VERSION ""

NS_ :

BS_:

BU_: HVESP01 HVESS

BO_ 2499750250 HVESP01_EstOcv_6: 8 HVESP01
 SG_ HVESP01_estOcv_01_6 m0 : 8|14@1+ (0.001,0) [0|16.383] "Ah"  HVESP01
 SG_ HVESP01_estOcv_02_6 m0 : 22|14@1+ (0.001,0) [0|16.383] "Ah"  HVESP01
 SG_ HVESP01_estOcv_03_6 m0 : 36|14@1+ (0.001,0) [0|16.383] "Ah"  HVESP01
 SG_ HVESP01_estOcv_04_6 m0 : 50|14@1+ (0.001,0) [0|16.383] "Ah"  HVESP01
 SG_ HVESP01_estOcv_05_6 m1 : 8|14@1+ (0.001,0) [0|16.383] "Ah"  HVESP01
 SG_ HVESP01_estOcv_06_6 m1 : 22|14@1+ (0.001,0) [0|16.383] "Ah"  HVESP01
 SG_ HVESP01_estOcv_07_6 m1 : 36|14@1+ (0.001,0) [0|16.383] "Ah"  HVESP01
 SG_ HVESP01_estOcv_08_6 m1 : 50|14@1+ (0.001,0) [0|16.383] "Ah"  HVESP01
 SG_ HVESP01_estOcv_09_6 m2 : 8|14@1+ (0.001,0) [0|16.383] "Ah"  HVESP01
 SG_ HVESP01_estOcv_10_6 m2 : 22|14@1+ (0.001,0) [0|16.383] "Ah"  HVESP01
 SG_ HVESP01_estOcv_11_6 m2 : 36|14@1+ (0.001,0) [0|16.383] "Ah"  HVESP01
 SG_ HVESP01_estOcv_12_6 m2 : 50|14@1+ (0.001,0) [0|16.383] "Ah"  HVESP01
 SG_ HVESP01_estOcv_13_6 m3 : 8|14@1+ (0.001,0) [0|16.383] "Ah"  HVESP01
 SG_ HVESP01_estOcv_14_6 m3 : 22|14@1+ (0.001,0) [0|16.383] "Ah"  HVESP01
 SG_ HVESP01_estOcv_15_6 m3 : 36|14@1+ (0.001,0) [0|16.383] "Ah"  HVESP01
 SG_ HVESP01_estOcv_16_6 m3 : 50|14@1+ (0.001,0) [0|16.383] "Ah"  HVESP01
 SG_ HVESP01_estOcv_17_6 m4 : 8|14@1+ (0.001,0) [0|16.383] "Ah"  HVESP01
 SG_ HVESP01_estOcv_18_6 m4 : 22|14@1+ (0.001,0) [0|16.383] "Ah"  HVESP01
 SG_ HVESP01_estOcv_19_6 m4 : 36|14@1+ (0.001,0) [0|16.383] "Ah"  HVESP01
 SG_ HVESP01_estOcv_20_6 m4 : 50|14@1+ (0.001,0) [0|16.383] "Ah"  HVESP01
 SG_ HVESP01_estOcv_21_6 m5 : 8|14@1+ (0.001,0) [0|16.383] "Ah"  HVESP01
 SG_ HVESP01_estOcv_22_6 m5 : 22|14@1+ (0.001,0) [0|16.383] "Ah"  HVESP01
 SG_ HVESP01_estOcv_23_6 m5 : 36|14@1+ (0.001,0) [0|16.383] "Ah"  HVESP01
 SG_ HVESP01_estOcv_24_6 m5 : 50|14@1+ (0.001,0) [0|16.383] "Ah"  HVESP01
 SG_ HVESP01_estOcv_25_6 m6 : 8|14@1+ (0.001,0) [0|16.383] "Ah"  HVESP01
 SG_ HVESP01_estOcv_26_6 m6 : 22|14@1+ (0.001,0) [0|16.383] "Ah"  HVESP01
 SG_ HVESP01_estOcv_27_6 m6 : 36|14@1+ (0.001,0) [0|16.383] "Ah"  HVESP01
 SG_ HVESP01_estOcv_28_6 m6 : 50|14@1+ (0.001,0) [0|16.383] "Ah"  HVESP01
 SG_ HVESP01_estOcv_29_6 m7 : 8|14@1+ (0.001,0) [0|16.383] "Ah"  HVESP01
 SG_ HVESP01_estOcv_30_6 m7 : 22|14@1+ (0.001,0) [0|16.383] "Ah"  HVESP01
 SG_ HVESP01_estOcv_31_6 m7 : 36|14@1+ (0.001,0) [0|16.383] "Ah"  HVESP01
 SG_ HVESP01_estOcv_32_6 m7 : 50|14@1+ (0.001,0) [0|16.383] "Ah"  HVESP01
 SG_ HVESP01_estOcv_33_6 m8 : 8|14@1+ (0.001,0) [0|16.383] "Ah"  HVESP01
 SG_ HVESP01_estOcv_34_6 m8 : 22|14@1+ (0.001,0) [0|16.383] "Ah"  HVESP01
 SG_ HVESP01_estOcv_35_6 m8 : 36|14@1+ (0.001,0) [0|16.383] "Ah"  HVESP01
 SG_ HVESP01_estOcv_36_6 m8 : 50|14@1+ (0.001,0) [0|16.383] "Ah"  HVESP01
 SG_ HVESP01_estOcv_37_6 m9 : 8|14@1+ (0.001,0) [0|16.383] "Ah"  HVESP01
 SG_ HVESP01_estOcv_38_6 m9 : 22|14@1+ (0.001,0) [0|16.383] "Ah"  HVESP01
 SG_ HVESP01_estOcv_39_6 m9 : 36|14@1+ (0.001,0) [0|16.383] "Ah"  HVESP01
 SG_ HVESP01_estOcv_40_6 m9 : 50|14@1+ (0.001,0) [0|16.383] "Ah"  HVESP01
 SG_ HVESP01_estOcv_41_6 m10 : 8|14@1+ (0.001,0) [0|16.383] "Ah"  HVESP01
 SG_ HVESP01_estOcv_42_6 m10 : 22|14@1+ (0.001,0) [0|16.383] "Ah"  HVESP01
 SG_ HVESP01_estOcv_43_6 m10 : 36|14@1+ (0.001,0) [0|16.383] "Ah"  HVESP01
 SG_ HVESP01_estOcv_44_6 m10 : 50|14@1+ (0.001,0) [0|16.383] "Ah"  HVESP01
 SG_ HVESP01_estOcv_45_6 m11 : 8|14@1+ (0.001,0) [0|16.383] "Ah"  HVESP01
 SG_ HVESP01_estOcv_46_6 m11 : 22|14@1+ (0.001,0) [0|16.383] "Ah"  HVESP01
 SG_ HVESP01_estOcv_47_6 m11 : 36|14@1+ (0.001,0) [0|16.383] "Ah"  HVESP01
 SG_ HVESP01_estOcv_48_6 m11 : 50|14@1+ (0.001,0) [0|16.383] "Ah"  HVESP01
 SG_ HVESP01_estOcv_49_6 m12 : 8|14@1+ (0.001,0) [0|16.383] "Ah"  HVESP01
 SG_ HVESP01_estOcv_50_6 m12 : 22|14@1+ (0.001,0) [0|16.383] "Ah"  HVESP01
 SG_ HVESP01_estOcv_51_6 m12 : 36|14@1+ (0.001,0) [0|16.383] "Ah"  HVESP01
 SG_ HVESP01_estOcv_52_6 m12 : 50|14@1+ (0.001,0) [0|16.383] "Ah"  HVESP01
 SG_ HVESP01_estOcv_53_6 m13 : 8|14@1+ (0.001,0) [0|16.383] "Ah"  HVESP01
 SG_ HVESP01_estOcv_54_6 m13 : 22|14@1+ (0.001,0) [0|16.383] "Ah"  HVESP01
 SG_ HVESP01_estOcv_55_6 m13 : 36|14@1+ (0.001,0) [0|16.383] "Ah"  HVESP01
 SG_ HVESP01_estOcv_56_6 m13 : 50|14@1+ (0.001,0) [0|16.383] "Ah"  HVESP01
 SG_ HVESP01_estOcv_57_6 m14 : 8|14@1+ (0.001,0) [0|16.383] "Ah"  HVESP01
 SG_ HVESP01_estOcv_58_6 m14 : 22|14@1+ (0.001,0) [0|16.383] "Ah"  HVESP01
 SG_ HVESP01_estOcv_59_6 m14 : 36|14@1+ (0.001,0) [0|16.383] "Ah"  HVESP01
 SG_ HVESP01_estOcv_60_6 m14 : 50|14@1+ (0.001,0) [0|16.383] "Ah"  HVESP01
 SG_ HVESP01_estOcv_61_6 m15 : 8|14@1+ (0.001,0) [0|16.383] "Ah"  HVESP01
 SG_ HVESP01_estOcv_62_6 m15 : 22|14@1+ (0.001,0) [0|16.383] "Ah"  HVESP01
 SG_ HVESP01_estOcv_63_6 m15 : 36|14@1+ (0.001,0) [0|16.383] "Ah"  HVESP01
 SG_ HVESP01_estOcv_64_6 m15 : 50|14@1+ (0.001,0) [0|16.383] "Ah"  HVESP01
 SG_ HVESP01_estOcv_65_6 m16 : 8|14@1+ (0.001,0) [0|16.383] "Ah"  HVESP01
 SG_ HVESP01_estOcv_66_6 m16 : 22|14@1+ (0.001,0) [0|16.383] "Ah"  HVESP01
 SG_ HVESP01_estOcv_67_6 m16 : 36|14@1+ (0.001,0) [0|16.383] "Ah"  HVESP01
 SG_ HVESP01_estOcv_68_6 m16 : 50|14@1+ (0.001,0) [0|16.383] "Ah"  HVESP01
 SG_ HVESP01_estOcv_69_6 m17 : 8|14@1+ (0.001,0) [0|16.383] "Ah"  HVESP01
 SG_ HVESP01_estOcv_70_6 m17 : 22|14@1+ (0.001,0) [0|16.383] "Ah"  HVESP01
 SG_ HVESP01_estOcv_71_6 m17 : 36|14@1+ (0.001,0) [0|16.383] "Ah"  HVESP01
 SG_ HVESP01_estOcv_72_6 m17 : 50|14@1+ (0.001,0) [0|16.383] "Ah"  HVESP01
 SG_ HVESP01_estOcv_73_6 m18 : 8|14@1+ (0.001,0) [0|16.383] "Ah"  HVESP01
 SG_ HVESP01_estOcv_74_6 m18 : 22|14@1+ (0.001,0) [0|16.383] "Ah"  HVESP01
 SG_ HVESP01_estOcv_75_6 m18 : 36|14@1+ (0.001,0) [0|16.383] "Ah"  HVESP01
 SG_ HVESP01_estOcv_76_6 m18 : 50|14@1+ (0.001,0) [0|16.383] "Ah"  HVESP01
 SG_ HVESP01_estOcv_77_6 m19 : 8|14@1+ (0.001,0) [0|16.383] "Ah"  HVESP01
 SG_ HVESP01_estOcv_78_6 m19 : 22|14@1+ (0.001,0) [0|16.383] "Ah"  HVESP01
 SG_ HVESP01_estOcv_79_6 m19 : 36|14@1+ (0.001,0) [0|16.383] "Ah"  HVESP01
 SG_ HVESP01_estOcv_80_6 m19 : 50|14@1+ (0.001,0) [0|16.383] "Ah"  HVESP01
 SG_ HVESP01_estOcv_81_6 m20 : 8|14@1+ (0.001,0) [0|16.383] "Ah"  HVESP01
 SG_ HVESP01_estOcv_82_6 m20 : 22|14@1+ (0.001,0) [0|16.383] "Ah"  HVESP01
 SG_ HVESP01_estOcv_83_6 m20 : 36|14@1+ (0.001,0) [0|16.383] "Ah"  HVESP01
 SG_ HVESP01_estOcv_84_6 m20 : 50|14@1+ (0.001,0) [0|16.383] "Ah"  HVESP01
 SG_ HVESP01_estOcv_85_6 m21 : 8|14@1+ (0.001,0) [0|16.383] "Ah"  HVESP01
 SG_ HVESP01_estOcv_86_6 m21 : 22|14@1+ (0.001,0) [0|16.383] "Ah"  HVESP01
 SG_ HVESP01_estOcv_87_6 m21 : 36|14@1+ (0.001,0) [0|16.383] "Ah"  HVESP01
 SG_ HVESP01_estOcv_88_6 m21 : 50|14@1+ (0.001,0) [0|16.383] "Ah"  HVESP01
 SG_ HVESP01_estOcv_89_6 m22 : 8|14@1+ (0.001,0) [0|16.383] "Ah"  HVESP01
 SG_ HVESP01_estOcv_90_6 m22 : 22|14@1+ (0.001,0) [0|16.383] "Ah"  HVESP01
 SG_ HVESP01_estOcv_91_6 m22 : 36|14@1+ (0.001,0) [0|16.383] "Ah"  HVESP01
 SG_ HVESP01_estOcv_92_6 m22 : 50|14@1+ (0.001,0) [0|16.383] "Ah"  HVESP01
 SG_ HVESP01_estOcv_93_6 m23 : 8|14@1+ (0.001,0) [0|16.383] "Ah"  HVESP01
 SG_ HVESP01_estOcv_94_6 m23 : 22|14@1+ (0.001,0) [0|16.383] "Ah"  HVESP01
 SG_ HVESP01_estOcv_95_6 m23 : 36|14@1+ (0.001,0) [0|16.383] "Ah"  HVESP01
 SG_ HVESP01_estOcv_96_6 m23 : 50|14@1+ (0.001,0) [0|16.383] "Ah"  HVESP01
 SG_ HVESP01_estOcv_97_6 m24 : 8|14@1+ (0.001,0) [0|16.383] "Ah"  HVESP01
 SG_ HVESP01_estOcv_98_6 m24 : 22|14@1+ (0.001,0) [0|16.383] "Ah"  HVESP01
 SG_ HVESP01_estOcv_99_6 m24 : 36|14@1+ (0.001,0) [0|16.383] "Ah"  HVESP01
 SG_ HVESP01_estOcv_100_6 m24 : 50|14@1+ (0.001,0) [0|16.383] "Ah"  HVESP01
 SG_ HVESP01_estOcv_101_6 m25 : 8|14@1+ (0.001,0) [0|16.383] "Ah"  HVESP01
 SG_ HVESP01_estOcv_102_6 m25 : 22|14@1+ (0.001,0) [0|16.383] "Ah"  HVESP01
 SG_ HVESP01_estOcv_103_6 m25 : 36|14@1+ (0.001,0) [0|16.383] "Ah"  HVESP01
 SG_ HVESP01_estOcv_104_6 m25 : 50|14@1+ (0.001,0) [0|16.383] "Ah"  HVESP01
 SG_ HVESP01_estOcv_105_6 m26 : 8|14@1+ (0.001,0) [0|16.383] "Ah"  HVESP01
 SG_ HVESP01_estOcv_106_6 m26 : 22|14@1+ (0.001,0) [0|16.383] "Ah"  HVESP01
 SG_ HVESP01_estOcv_107_6 m26 : 36|14@1+ (0.001,0) [0|16.383] "Ah"  HVESP01
 SG_ HVESP01_estOcv_108_6 m26 : 50|14@1+ (0.001,0) [0|16.383] "Ah"  HVESP01
 SG_ HVESP01_estOcv_109_6 m27 : 8|14@1+ (0.001,0) [0|16.383] "Ah"  HVESP01
 SG_ HVESP01_estOcv_110_6 m27 : 22|14@1+ (0.001,0) [0|16.383] "Ah"  HVESP01
 SG_ HVESP01_estOcv_111_6 m27 : 36|14@1+ (0.001,0) [0|16.383] "Ah"  HVESP01
 SG_ HVESP01_estOcv_112_6 m27 : 50|14@1+ (0.001,0) [0|16.383] "Ah"  HVESP01
 SG_ HVESP01_estOcv_113_6 m28 : 8|14@1+ (0.001,0) [0|16.383] "Ah"  HVESP01
 SG_ HVESP01_estOcv_114_6 m28 : 22|14@1+ (0.001,0) [0|16.383] "Ah"  HVESP01
 SG_ HVESP01_estOcv_115_6 m28 : 36|14@1+ (0.001,0) [0|16.383] "Ah"  HVESP01
 SG_ HVESP01_estOcv_116_6 m28 : 50|14@1+ (0.001,0) [0|16.383] "Ah"  HVESP01
 SG_ HVESP01_estOcv_117_6 m29 : 8|14@1+ (0.001,0) [0|16.383] "Ah"  HVESP01
 SG_ HVESP01_estOcv_118_6 m29 : 22|14@1+ (0.001,0) [0|16.383] "Ah"  HVESP01
 SG_ HVESP01_estOcv_119_6 m29 : 36|14@1+ (0.001,0) [0|16.383] "Ah"  HVESP01
 SG_ HVESP01_estOcv_120_6 m29 : 50|14@1+ (0.001,0) [0|16.383] "Ah"  HVESP01
 SG_ HVESP01_estOcv_121_6 m30 : 8|14@1+ (0.001,0) [0|16.383] "Ah"  HVESP01
 SG_ HVESP01_estOcv_122_6 m30 : 22|14@1+ (0.001,0) [0|16.383] "Ah"  HVESP01
 SG_ HVESP01_estOcv_123_6 m30 : 36|14@1+ (0.001,0) [0|16.383] "Ah"  HVESP01
 SG_ HVESP01_estOcv_124_6 m30 : 50|14@1+ (0.001,0) [0|16.383] "Ah"  HVESP01
 SG_ HVESP01_estOcv_125_6 m31 : 8|14@1+ (0.001,0) [0|16.383] "Ah"  HVESP01
 SG_ HVESP01_estOcv_126_6 m31 : 22|14@1+ (0.001,0) [0|16.383] "Ah"  HVESP01
 SG_ HVESP01_estOcv_127_6 m31 : 36|14@1+ (0.001,0) [0|16.383] "Ah"  HVESP01
 SG_ HVESP01_estOcv_128_6 m31 : 50|14@1+ (0.001,0) [0|16.383] "Ah"  HVESP01
 SG_ HVESP01_estOcv_129_6 m32 : 8|14@1+ (0.001,0) [0|16.383] "Ah"  HVESP01
 SG_ HVESP01_estOcv_130_6 m32 : 22|14@1+ (0.001,0) [0|16.383] "Ah"  HVESP01
 SG_ HVESP01_estOcv_131_6 m32 : 36|14@1+ (0.001,0) [0|16.383] "Ah"  HVESP01
 SG_ HVESP01_estOcv_132_6 m32 : 50|14@1+ (0.001,0) [0|16.383] "Ah"  HVESP01
 SG_ HVESP01_estOcv_133_6 m33 : 8|14@1+ (0.001,0) [0|16.383] "Ah"  HVESP01
 SG_ HVESP01_estOcv_134_6 m33 : 22|14@1+ (0.001,0) [0|16.383] "Ah"  HVESP01
 SG_ HVESP01_estOcv_135_6 m33 : 36|14@1+ (0.001,0) [0|16.383] "Ah"  HVESP01
 SG_ HVESP01_estOcv_136_6 m33 : 50|14@1+ (0.001,0) [0|16.383] "Ah"  HVESP01
 SG_ HVESP01_estOcv_137_6 m34 : 8|14@1+ (0.001,0) [0|16.383] "Ah"  HVESP01
 SG_ HVESP01_estOcv_138_6 m34 : 22|14@1+ (0.001,0) [0|16.383] "Ah"  HVESP01
 SG_ HVESP01_estOcv_139_6 m34 : 36|14@1+ (0.001,0) [0|16.383] "Ah"  HVESP01
 SG_ HVESP01_estOcv_140_6 m34 : 50|14@1+ (0.001,0) [0|16.383] "Ah"  HVESP01
 SG_ HVESP01_estOcv_141_6 m35 : 8|14@1+ (0.001,0) [0|16.383] "Ah"  HVESP01
 SG_ HVESP01_estOcv_142_6 m35 : 22|14@1+ (0.001,0) [0|16.383] "Ah"  HVESP01
 SG_ HVESP01_estOcv_143_6 m35 : 36|14@1+ (0.001,0) [0|16.383] "Ah"  HVESP01
 SG_ HVESP01_estOcv_144_6 m35 : 50|14@1+ (0.001,0) [0|16.383] "Ah"  HVESP01
 SG_ HVESP01_estOcv_145_6 m36 : 8|14@1+ (0.001,0) [0|16.383] "Ah"  HVESP01
 SG_ HVESP01_estOcv_146_6 m36 : 22|14@1+ (0.001,0) [0|16.383] "Ah"  HVESP01
 SG_ HVESP01_estOcv_147_6 m36 : 36|14@1+ (0.001,0) [0|16.383] "Ah"  HVESP01
 SG_ HVESP01_estOcv_148_6 m36 : 50|14@1+ (0.001,0) [0|16.383] "Ah"  HVESP01
 SG_ HVESP01_estOcv_149_6 m37 : 8|14@1+ (0.001,0) [0|16.383] "Ah"  HVESP01
 SG_ HVESP01_estOcv_150_6 m37 : 22|14@1+ (0.001,0) [0|16.383] "Ah"  HVESP01
 SG_ HVESP01_estOcv_151_6 m37 : 36|14@1+ (0.001,0) [0|16.383] "Ah"  HVESP01
 SG_ HVESP01_estOcv_152_6 m37 : 50|14@1+ (0.001,0) [0|16.383] "Ah"  HVESP01
 SG_ HVESP01_estOcv_153_6 m38 : 8|14@1+ (0.001,0) [0|16.383] "Ah"  HVESP01
 SG_ HVESP01_estOcv_154_6 m38 : 22|14@1+ (0.001,0) [0|16.383] "Ah"  HVESP01
 SG_ HVESP01_estOcv_155_6 m38 : 36|14@1+ (0.001,0) [0|16.383] "Ah"  HVESP01
 SG_ HVESP01_estOcv_156_6 m38 : 50|14@1+ (0.001,0) [0|16.383] "Ah"  HVESP01
 SG_ HVESP01_estOcv_157_6 m39 : 8|14@1+ (0.001,0) [0|16.383] "Ah"  HVESP01
 SG_ HVESP01_estOcv_158_6 m39 : 22|14@1+ (0.001,0) [0|16.383] "Ah"  HVESP01
 SG_ HVESP01_estOcv_159_6 m39 : 36|14@1+ (0.001,0) [0|16.383] "Ah"  HVESP01
 SG_ HVESP01_estOcv_160_6 m39 : 50|14@1+ (0.001,0) [0|16.383] "Ah"  HVESP01
 SG_ HVESP01_estOcv_161_6 m40 : 8|14@1+ (0.001,0) [0|16.383] "Ah"  HVESP01
 SG_ HVESP01_estOcv_162_6 m40 : 22|14@1+ (0.001,0) [0|16.383] "Ah"  HVESP01
 SG_ HVESP01_estOcv_163_6 m40 : 36|14@1+ (0.001,0) [0|16.383] "Ah"  HVESP01
 SG_ HVESP01_estOcv_164_6 m40 : 50|14@1+ (0.001,0) [0|16.383] "Ah"  HVESP01
 SG_ HVESP01_estOcv_165_6 m41 : 8|14@1+ (0.001,0) [0|16.383] "Ah"  HVESP01
 SG_ HVESP01_estOcv_166_6 m41 : 22|14@1+ (0.001,0) [0|16.383] "Ah"  HVESP01
 SG_ HVESP01_estOcv_167_6 m41 : 36|14@1+ (0.001,0) [0|16.383] "Ah"  HVESP01
 SG_ HVESP01_estOcv_168_6 m41 : 50|14@1+ (0.001,0) [0|16.383] "Ah"  HVESP01
 SG_ HVESP01_estOcv_169_6 m42 : 8|14@1+ (0.001,0) [0|16.383] "Ah"  HVESP01
 SG_ HVESP01_estOcv_170_6 m42 : 22|14@1+ (0.001,0) [0|16.383] "Ah"  HVESP01
 SG_ HVESP01_estOcv_171_6 m42 : 36|14@1+ (0.001,0) [0|16.383] "Ah"  HVESP01
 SG_ HVESP01_estOcv_172_6 m42 : 50|14@1+ (0.001,0) [0|16.383] "Ah"  HVESP01
 SG_ HVESP01_estOcv_173_6 m43 : 8|14@1+ (0.001,0) [0|16.383] "Ah"  HVESP01
 SG_ HVESP01_estOcv_174_6 m43 : 22|14@1+ (0.001,0) [0|16.383] "Ah"  HVESP01
 SG_ HVESP01_estOcv_175_6 m43 : 36|14@1+ (0.001,0) [0|16.383] "Ah"  HVESP01
 SG_ HVESP01_estOcv_176_6 m43 : 50|14@1+ (0.001,0) [0|16.383] "Ah"  HVESP01
 SG_ HVESP01_estOcv_177_6 m44 : 8|14@1+ (0.001,0) [0|16.383] "Ah"  HVESP01
 SG_ HVESP01_estOcv_178_6 m44 : 22|14@1+ (0.001,0) [0|16.383] "Ah"  HVESP01
 SG_ HVESP01_estOcv_179_6 m44 : 36|14@1+ (0.001,0) [0|16.383] "Ah"  HVESP01
 SG_ HVESP01_estOcv_180_6 m44 : 50|14@1+ (0.001,0) [0|16.383] "Ah"  HVESP01
 SG_ multiplexoreo_6 M : 0|8@1+ (1,0) [0|255] ""  HVESP01

BO_ 2499750251 HVESP01_EstOcv_7: 8 HVESP01
 SG_ HVESP01_estOcv_01_7 m0 : 8|14@1+ (0.001,0) [0|16.383] "Ah"  HVESP01
 SG_ HVESP01_estOcv_02_7 m0 : 22|14@1+ (0.001,0) [0|16.383] "Ah"  HVESP01
 SG_ HVESP01_estOcv_03_7 m0 : 36|14@1+ (0.001,0) [0|16.383] "Ah"  HVESP01
 SG_ HVESP01_estOcv_04_7 m0 : 50|14@1+ (0.001,0) [0|16.383] "Ah"  HVESP01
 SG_ HVESP01_estOcv_05_7 m1 : 8|14@1+ (0.001,0) [0|16.383] "Ah"  HVESP01
 SG_ HVESP01_estOcv_06_7 m1 : 22|14@1+ (0.001,0) [0|16.383] "Ah"  HVESP01
 SG_ HVESP01_estOcv_07_7 m1 : 36|14@1+ (0.001,0) [0|16.383] "Ah"  HVESP01
 SG_ HVESP01_estOcv_08_7 m1 : 50|14@1+ (0.001,0) [0|16.383] "Ah"  HVESP01
 SG_ HVESP01_estOcv_09_7 m2 : 8|14@1+ (0.001,0) [0|16.383] "Ah"  HVESP01
 SG_ HVESP01_estOcv_10_7 m2 : 22|14@1+ (0.001,0) [0|16.383] "Ah"  HVESP01
 SG_ HVESP01_estOcv_11_7 m2 : 36|14@1+ (0.001,0) [0|16.383] "Ah"  HVESP01
 SG_ HVESP01_estOcv_12_7 m2 : 50|14@1+ (0.001,0) [0|16.383] "Ah"  HVESP01
 SG_ HVESP01_estOcv_13_7 m3 : 8|14@1+ (0.001,0) [0|16.383] "Ah"  HVESP01
 SG_ HVESP01_estOcv_14_7 m3 : 22|14@1+ (0.001,0) [0|16.383] "Ah"  HVESP01
 SG_ HVESP01_estOcv_15_7 m3 : 36|14@1+ (0.001,0) [0|16.383] "Ah"  HVESP01
 SG_ HVESP01_estOcv_16_7 m3 : 50|14@1+ (0.001,0) [0|16.383] "Ah"  HVESP01
 SG_ HVESP01_estOcv_17_7 m4 : 8|14@1+ (0.001,0) [0|16.383] "Ah"  HVESP01
 SG_ HVESP01_estOcv_18_7 m4 : 22|14@1+ (0.001,0) [0|16.383] "Ah"  HVESP01
 SG_ HVESP01_estOcv_19_7 m4 : 36|14@1+ (0.001,0) [0|16.383] "Ah"  HVESP01
 SG_ HVESP01_estOcv_20_7 m4 : 50|14@1+ (0.001,0) [0|16.383] "Ah"  HVESP01
 SG_ HVESP01_estOcv_21_7 m5 : 8|14@1+ (0.001,0) [0|16.383] "Ah"  HVESP01
 SG_ HVESP01_estOcv_22_7 m5 : 22|14@1+ (0.001,0) [0|16.383] "Ah"  HVESP01
 SG_ HVESP01_estOcv_23_7 m5 : 36|14@1+ (0.001,0) [0|16.383] "Ah"  HVESP01
 SG_ HVESP01_estOcv_24_7 m5 : 50|14@1+ (0.001,0) [0|16.383] "Ah"  HVESP01
 SG_ HVESP01_estOcv_25_7 m6 : 8|14@1+ (0.001,0) [0|16.383] "Ah"  HVESP01
 SG_ HVESP01_estOcv_26_7 m6 : 22|14@1+ (0.001,0) [0|16.383] "Ah"  HVESP01
 SG_ HVESP01_estOcv_27_7 m6 : 36|14@1+ (0.001,0) [0|16.383] "Ah"  HVESP01
 SG_ HVESP01_estOcv_28_7 m6 : 50|14@1+ (0.001,0) [0|16.383] "Ah"  HVESP01
 SG_ HVESP01_estOcv_29_7 m7 : 8|14@1+ (0.001,0) [0|16.383] "Ah"  HVESP01
 SG_ HVESP01_estOcv_30_7 m7 : 22|14@1+ (0.001,0) [0|16.383] "Ah"  HVESP01
 SG_ HVESP01_estOcv_31_7 m7 : 36|14@1+ (0.001,0) [0|16.383] "Ah"  HVESP01
 SG_ HVESP01_estOcv_32_7 m7 : 50|14@1+ (0.001,0) [0|16.383] "Ah"  HVESP01
 SG_ HVESP01_estOcv_33_7 m8 : 8|14@1+ (0.001,0) [0|16.383] "Ah"  HVESP01
 SG_ HVESP01_estOcv_34_7 m8 : 22|14@1+ (0.001,0) [0|16.383] "Ah"  HVESP01
 SG_ HVESP01_estOcv_35_7 m8 : 36|14@1+ (0.001,0) [0|16.383] "Ah"  HVESP01
 SG_ HVESP01_estOcv_36_7 m8 : 50|14@1+ (0.001,0) [0|16.383] "Ah"  HVESP01
 SG_ HVESP01_estOcv_37_7 m9 : 8|14@1+ (0.001,0) [0|16.383] "Ah"  HVESP01
 SG_ HVESP01_estOcv_38_7 m9 : 22|14@1+ (0.001,0) [0|16.383] "Ah"  HVESP01
 SG_ HVESP01_estOcv_39_7 m9 : 36|14@1+ (0.001,0) [0|16.383] "Ah"  HVESP01
 SG_ HVESP01_estOcv_40_7 m9 : 50|14@1+ (0.001,0) [0|16.383] "Ah"  HVESP01
 SG_ HVESP01_estOcv_41_7 m10 : 8|14@1+ (0.001,0) [0|16.383] "Ah"  HVESP01
 SG_ HVESP01_estOcv_42_7 m10 : 22|14@1+ (0.001,0) [0|16.383] "Ah"  HVESP01
 SG_ HVESP01_estOcv_43_7 m10 : 36|14@1+ (0.001,0) [0|16.383] "Ah"  HVESP01
 SG_ HVESP01_estOcv_44_7 m10 : 50|14@1+ (0.001,0) [0|16.383] "Ah"  HVESP01
 SG_ HVESP01_estOcv_45_7 m11 : 8|14@1+ (0.001,0) [0|16.383] "Ah"  HVESP01
 SG_ HVESP01_estOcv_46_7 m11 : 22|14@1+ (0.001,0) [0|16.383] "Ah"  HVESP01
 SG_ HVESP01_estOcv_47_7 m11 : 36|14@1+ (0.001,0) [0|16.383] "Ah"  HVESP01
 SG_ HVESP01_estOcv_48_7 m11 : 50|14@1+ (0.001,0) [0|16.383] "Ah"  HVESP01
 SG_ HVESP01_estOcv_49_7 m12 : 8|14@1+ (0.001,0) [0|16.383] "Ah"  HVESP01
 SG_ HVESP01_estOcv_50_7 m12 : 22|14@1+ (0.001,0) [0|16.383] "Ah"  HVESP01
 SG_ HVESP01_estOcv_51_7 m12 : 36|14@1+ (0.001,0) [0|16.383] "Ah"  HVESP01
 SG_ HVESP01_estOcv_52_7 m12 : 50|14@1+ (0.001,0) [0|16.383] "Ah"  HVESP01
 SG_ HVESP01_estOcv_53_7 m13 : 8|14@1+ (0.001,0) [0|16.383] "Ah"  HVESP01
 SG_ HVESP01_estOcv_54_7 m13 : 22|14@1+ (0.001,0) [0|16.383] "Ah"  HVESP01
 SG_ HVESP01_estOcv_55_7 m13 : 36|14@1+ (0.001,0) [0|16.383] "Ah"  HVESP01
 SG_ HVESP01_estOcv_56_7 m13 : 50|14@1+ (0.001,0) [0|16.383] "Ah"  HVESP01
 SG_ HVESP01_estOcv_57_7 m14 : 8|14@1+ (0.001,0) [0|16.383] "Ah"  HVESP01
 SG_ HVESP01_estOcv_58_7 m14 : 22|14@1+ (0.001,0) [0|16.383] "Ah"  HVESP01
 SG_ HVESP01_estOcv_59_7 m14 : 36|14@1+ (0.001,0) [0|16.383] "Ah"  HVESP01
 SG_ HVESP01_estOcv_60_7 m14 : 50|14@1+ (0.001,0) [0|16.383] "Ah"  HVESP01
 SG_ HVESP01_estOcv_61_7 m15 : 8|14@1+ (0.001,0) [0|16.383] "Ah"  HVESP01
 SG_ HVESP01_estOcv_62_7 m15 : 22|14@1+ (0.001,0) [0|16.383] "Ah"  HVESP01
 SG_ HVESP01_estOcv_63_7 m15 : 36|14@1+ (0.001,0) [0|16.383] "Ah"  HVESP01
 SG_ HVESP01_estOcv_64_7 m15 : 50|14@1+ (0.001,0) [0|16.383] "Ah"  HVESP01
 SG_ HVESP01_estOcv_65_7 m16 : 8|14@1+ (0.001,0) [0|16.383] "Ah"  HVESP01
 SG_ HVESP01_estOcv_66_7 m16 : 22|14@1+ (0.001,0) [0|16.383] "Ah"  HVESP01
 SG_ HVESP01_estOcv_67_7 m16 : 36|14@1+ (0.001,0) [0|16.383] "Ah"  HVESP01
 SG_ HVESP01_estOcv_68_7 m16 : 50|14@1+ (0.001,0) [0|16.383] "Ah"  HVESP01
 SG_ HVESP01_estOcv_69_7 m17 : 8|14@1+ (0.001,0) [0|16.383] "Ah"  HVESP01
 SG_ HVESP01_estOcv_70_7 m17 : 22|14@1+ (0.001,0) [0|16.383] "Ah"  HVESP01
 SG_ HVESP01_estOcv_71_7 m17 : 36|14@1+ (0.001,0) [0|16.383] "Ah"  HVESP01
 SG_ HVESP01_estOcv_72_7 m17 : 50|14@1+ (0.001,0) [0|16.383] "Ah"  HVESP01
 SG_ HVESP01_estOcv_73_7 m18 : 8|14@1+ (0.001,0) [0|16.383] "Ah"  HVESP01
 SG_ HVESP01_estOcv_74_7 m18 : 22|14@1+ (0.001,0) [0|16.383] "Ah"  HVESP01
 SG_ HVESP01_estOcv_75_7 m18 : 36|14@1+ (0.001,0) [0|16.383] "Ah"  HVESP01
 SG_ HVESP01_estOcv_76_7 m18 : 50|14@1+ (0.001,0) [0|16.383] "Ah"  HVESP01
 SG_ HVESP01_estOcv_77_7 m19 : 8|14@1+ (0.001,0) [0|16.383] "Ah"  HVESP01
 SG_ HVESP01_estOcv_78_7 m19 : 22|14@1+ (0.001,0) [0|16.383] "Ah"  HVESP01
 SG_ HVESP01_estOcv_79_7 m19 : 36|14@1+ (0.001,0) [0|16.383] "Ah"  HVESP01
 SG_ HVESP01_estOcv_80_7 m19 : 50|14@1+ (0.001,0) [0|16.383] "Ah"  HVESP01
 SG_ HVESP01_estOcv_81_7 m20 : 8|14@1+ (0.001,0) [0|16.383] "Ah"  HVESP01
 SG_ HVESP01_estOcv_82_7 m20 : 22|14@1+ (0.001,0) [0|16.383] "Ah"  HVESP01
 SG_ HVESP01_estOcv_83_7 m20 : 36|14@1+ (0.001,0) [0|16.383] "Ah"  HVESP01
 SG_ HVESP01_estOcv_84_7 m20 : 50|14@1+ (0.001,0) [0|16.383] "Ah"  HVESP01
 SG_ HVESP01_estOcv_85_7 m21 : 8|14@1+ (0.001,0) [0|16.383] "Ah"  HVESP01
 SG_ HVESP01_estOcv_86_7 m21 : 22|14@1+ (0.001,0) [0|16.383] "Ah"  HVESP01
 SG_ HVESP01_estOcv_87_7 m21 : 36|14@1+ (0.001,0) [0|16.383] "Ah"  HVESP01
 SG_ HVESP01_estOcv_88_7 m21 : 50|14@1+ (0.001,0) [0|16.383] "Ah"  HVESP01
 SG_ HVESP01_estOcv_89_7 m22 : 8|14@1+ (0.001,0) [0|16.383] "Ah"  HVESP01
 SG_ HVESP01_estOcv_90_7 m22 : 22|14@1+ (0.001,0) [0|16.383] "Ah"  HVESP01
 SG_ HVESP01_estOcv_91_7 m22 : 36|14@1+ (0.001,0) [0|16.383] "Ah"  HVESP01
 SG_ HVESP01_estOcv_92_7 m22 : 50|14@1+ (0.001,0) [0|16.383] "Ah"  HVESP01
 SG_ HVESP01_estOcv_93_7 m23 : 8|14@1+ (0.001,0) [0|16.383] "Ah"  HVESP01
 SG_ HVESP01_estOcv_94_7 m23 : 22|14@1+ (0.001,0) [0|16.383] "Ah"  HVESP01
 SG_ HVESP01_estOcv_95_7 m23 : 36|14@1+ (0.001,0) [0|16.383] "Ah"  HVESP01
 SG_ HVESP01_estOcv_96_7 m23 : 50|14@1+ (0.001,0) [0|16.383] "Ah"  HVESP01
 SG_ HVESP01_estOcv_97_7 m24 : 8|14@1+ (0.001,0) [0|16.383] "Ah"  HVESP01
 SG_ HVESP01_estOcv_98_7 m24 : 22|14@1+ (0.001,0) [0|16.383] "Ah"  HVESP01
 SG_ HVESP01_estOcv_99_7 m24 : 36|14@1+ (0.001,0) [0|16.383] "Ah"  HVESP01
 SG_ HVESP01_estOcv_100_7 m24 : 50|14@1+ (0.001,0) [0|16.383] "Ah"  HVESP01
 SG_ HVESP01_estOcv_101_7 m25 : 8|14@1+ (0.001,0) [0|16.383] "Ah"  HVESP01
 SG_ HVESP01_estOcv_102_7 m25 : 22|14@1+ (0.001,0) [0|16.383] "Ah"  HVESP01
 SG_ HVESP01_estOcv_103_7 m25 : 36|14@1+ (0.001,0) [0|16.383] "Ah"  HVESP01
 SG_ HVESP01_estOcv_104_7 m25 : 50|14@1+ (0.001,0) [0|16.383] "Ah"  HVESP01
 SG_ HVESP01_estOcv_105_7 m26 : 8|14@1+ (0.001,0) [0|16.383] "Ah"  HVESP01
 SG_ HVESP01_estOcv_106_7 m26 : 22|14@1+ (0.001,0) [0|16.383] "Ah"  HVESP01
 SG_ HVESP01_estOcv_107_7 m26 : 36|14@1+ (0.001,0) [0|16.383] "Ah"  HVESP01
 SG_ HVESP01_estOcv_108_7 m26 : 50|14@1+ (0.001,0) [0|16.383] "Ah"  HVESP01
 SG_ HVESP01_estOcv_109_7 m27 : 8|14@1+ (0.001,0) [0|16.383] "Ah"  HVESP01
 SG_ HVESP01_estOcv_110_7 m27 : 22|14@1+ (0.001,0) [0|16.383] "Ah"  HVESP01
 SG_ HVESP01_estOcv_111_7 m27 : 36|14@1+ (0.001,0) [0|16.383] "Ah"  HVESP01
 SG_ HVESP01_estOcv_112_7 m27 : 50|14@1+ (0.001,0) [0|16.383] "Ah"  HVESP01
 SG_ HVESP01_estOcv_113_7 m28 : 8|14@1+ (0.001,0) [0|16.383] "Ah"  HVESP01
 SG_ HVESP01_estOcv_114_7 m28 : 22|14@1+ (0.001,0) [0|16.383] "Ah"  HVESP01
 SG_ HVESP01_estOcv_115_7 m28 : 36|14@1+ (0.001,0) [0|16.383] "Ah"  HVESP01
 SG_ HVESP01_estOcv_116_7 m28 : 50|14@1+ (0.001,0) [0|16.383] "Ah"  HVESP01
 SG_ HVESP01_estOcv_117_7 m29 : 8|14@1+ (0.001,0) [0|16.383] "Ah"  HVESP01
 SG_ HVESP01_estOcv_118_7 m29 : 22|14@1+ (0.001,0) [0|16.383] "Ah"  HVESP01
 SG_ HVESP01_estOcv_119_7 m29 : 36|14@1+ (0.001,0) [0|16.383] "Ah"  HVESP01
 SG_ HVESP01_estOcv_120_7 m29 : 50|14@1+ (0.001,0) [0|16.383] "Ah"  HVESP01
 SG_ HVESP01_estOcv_121_7 m30 : 8|14@1+ (0.001,0) [0|16.383] "Ah"  HVESP01
 SG_ HVESP01_estOcv_122_7 m30 : 22|14@1+ (0.001,0) [0|16.383] "Ah"  HVESP01
 SG_ HVESP01_estOcv_123_7 m30 : 36|14@1+ (0.001,0) [0|16.383] "Ah"  HVESP01
 SG_ HVESP01_estOcv_124_7 m30 : 50|14@1+ (0.001,0) [0|16.383] "Ah"  HVESP01
 SG_ HVESP01_estOcv_125_7 m31 : 8|14@1+ (0.001,0) [0|16.383] "Ah"  HVESP01
 SG_ HVESP01_estOcv_126_7 m31 : 22|14@1+ (0.001,0) [0|16.383] "Ah"  HVESP01
 SG_ HVESP01_estOcv_127_7 m31 : 36|14@1+ (0.001,0) [0|16.383] "Ah"  HVESP01
 SG_ HVESP01_estOcv_128_7 m31 : 50|14@1+ (0.001,0) [0|16.383] "Ah"  HVESP01
 SG_ HVESP01_estOcv_129_7 m32 : 8|14@1+ (0.001,0) [0|16.383] "Ah"  HVESP01
 SG_ HVESP01_estOcv_130_7 m32 : 22|14@1+ (0.001,0) [0|16.383] "Ah"  HVESP01
 SG_ HVESP01_estOcv_131_7 m32 : 36|14@1+ (0.001,0) [0|16.383] "Ah"  HVESP01
 SG_ HVESP01_estOcv_132_7 m32 : 50|14@1+ (0.001,0) [0|16.383] "Ah"  HVESP01
 SG_ HVESP01_estOcv_133_7 m33 : 8|14@1+ (0.001,0) [0|16.383] "Ah"  HVESP01
 SG_ HVESP01_estOcv_134_7 m33 : 22|14@1+ (0.001,0) [0|16.383] "Ah"  HVESP01
 SG_ HVESP01_estOcv_135_7 m33 : 36|14@1+ (0.001,0) [0|16.383] "Ah"  HVESP01
 SG_ HVESP01_estOcv_136_7 m33 : 50|14@1+ (0.001,0) [0|16.383] "Ah"  HVESP01
 SG_ HVESP01_estOcv_137_7 m34 : 8|14@1+ (0.001,0) [0|16.383] "Ah"  HVESP01
 SG_ HVESP01_estOcv_138_7 m34 : 22|14@1+ (0.001,0) [0|16.383] "Ah"  HVESP01
 SG_ HVESP01_estOcv_139_7 m34 : 36|14@1+ (0.001,0) [0|16.383] "Ah"  HVESP01
 SG_ HVESP01_estOcv_140_7 m34 : 50|14@1+ (0.001,0) [0|16.383] "Ah"  HVESP01
 SG_ HVESP01_estOcv_141_7 m35 : 8|14@1+ (0.001,0) [0|16.383] "Ah"  HVESP01
 SG_ HVESP01_estOcv_142_7 m35 : 22|14@1+ (0.001,0) [0|16.383] "Ah"  HVESP01
 SG_ HVESP01_estOcv_143_7 m35 : 36|14@1+ (0.001,0) [0|16.383] "Ah"  HVESP01
 SG_ HVESP01_estOcv_144_7 m35 : 50|14@1+ (0.001,0) [0|16.383] "Ah"  HVESP01
 SG_ HVESP01_estOcv_145_7 m36 : 8|14@1+ (0.001,0) [0|16.383] "Ah"  HVESP01
 SG_ HVESP01_estOcv_146_7 m36 : 22|14@1+ (0.001,0) [0|16.383] "Ah"  HVESP01
 SG_ HVESP01_estOcv_147_7 m36 : 36|14@1+ (0.001,0) [0|16.383] "Ah"  HVESP01
 SG_ HVESP01_estOcv_148_7 m36 : 50|14@1+ (0.001,0) [0|16.383] "Ah"  HVESP01
 SG_ HVESP01_estOcv_149_7 m37 : 8|14@1+ (0.001,0) [0|16.383] "Ah"  HVESP01
 SG_ HVESP01_estOcv_150_7 m37 : 22|14@1+ (0.001,0) [0|16.383] "Ah"  HVESP01
 SG_ HVESP01_estOcv_151_7 m37 : 36|14@1+ (0.001,0) [0|16.383] "Ah"  HVESP01
 SG_ HVESP01_estOcv_152_7 m37 : 50|14@1+ (0.001,0) [0|16.383] "Ah"  HVESP01
 SG_ HVESP01_estOcv_153_7 m38 : 8|14@1+ (0.001,0) [0|16.383] "Ah"  HVESP01
 SG_ HVESP01_estOcv_154_7 m38 : 22|14@1+ (0.001,0) [0|16.383] "Ah"  HVESP01
 SG_ HVESP01_estOcv_155_7 m38 : 36|14@1+ (0.001,0) [0|16.383] "Ah"  HVESP01
 SG_ HVESP01_estOcv_156_7 m38 : 50|14@1+ (0.001,0) [0|16.383] "Ah"  HVESP01
 SG_ HVESP01_estOcv_157_7 m39 : 8|14@1+ (0.001,0) [0|16.383] "Ah"  HVESP01
 SG_ HVESP01_estOcv_158_7 m39 : 22|14@1+ (0.001,0) [0|16.383] "Ah"  HVESP01
 SG_ HVESP01_estOcv_159_7 m39 : 36|14@1+ (0.001,0) [0|16.383] "Ah"  HVESP01
 SG_ HVESP01_estOcv_160_7 m39 : 50|14@1+ (0.001,0) [0|16.383] "Ah"  HVESP01
 SG_ HVESP01_estOcv_161_7 m40 : 8|14@1+ (0.001,0) [0|16.383] "Ah"  HVESP01
 SG_ HVESP01_estOcv_162_7 m40 : 22|14@1+ (0.001,0) [0|16.383] "Ah"  HVESP01
 SG_ HVESP01_estOcv_163_7 m40 : 36|14@1+ (0.001,0) [0|16.383] "Ah"  HVESP01
 SG_ HVESP01_estOcv_164_7 m40 : 50|14@1+ (0.001,0) [0|16.383] "Ah"  HVESP01
 SG_ HVESP01_estOcv_165_7 m41 : 8|14@1+ (0.001,0) [0|16.383] "Ah"  HVESP01
 SG_ HVESP01_estOcv_166_7 m41 : 22|14@1+ (0.001,0) [0|16.383] "Ah"  HVESP01
 SG_ HVESP01_estOcv_167_7 m41 : 36|14@1+ (0.001,0) [0|16.383] "Ah"  HVESP01
 SG_ HVESP01_estOcv_168_7 m41 : 50|14@1+ (0.001,0) [0|16.383] "Ah"  HVESP01
 SG_ HVESP01_estOcv_169_7 m42 : 8|14@1+ (0.001,0) [0|16.383] "Ah"  HVESP01
 SG_ HVESP01_estOcv_170_7 m42 : 22|14@1+ (0.001,0) [0|16.383] "Ah"  HVESP01
 SG_ HVESP01_estOcv_171_7 m42 : 36|14@1+ (0.001,0) [0|16.383] "Ah"  HVESP01
 SG_ HVESP01_estOcv_172_7 m42 : 50|14@1+ (0.001,0) [0|16.383] "Ah"  HVESP01
 SG_ HVESP01_estOcv_173_7 m43 : 8|14@1+ (0.001,0) [0|16.383] "Ah"  HVESP01
 SG_ HVESP01_estOcv_174_7 m43 : 22|14@1+ (0.001,0) [0|16.383] "Ah"  HVESP01
 SG_ HVESP01_estOcv_175_7 m43 : 36|14@1+ (0.001,0) [0|16.383] "Ah"  HVESP01
 SG_ HVESP01_estOcv_176_7 m43 : 50|14@1+ (0.001,0) [0|16.383] "Ah"  HVESP01
 SG_ HVESP01_estOcv_177_7 m44 : 8|14@1+ (0.001,0) [0|16.383] "Ah"  HVESP01
 SG_ HVESP01_estOcv_178_7 m44 : 22|14@1+ (0.001,0) [0|16.383] "Ah"  HVESP01
 SG_ HVESP01_estOcv_179_7 m44 : 36|14@1+ (0.001,0) [0|16.383] "Ah"  HVESP01
 SG_ HVESP01_estOcv_180_7 m44 : 50|14@1+ (0.001,0) [0|16.383] "Ah"  HVESP01
 SG_ multiplexoreo_7 M : 0|8@1+ (1,0) [0|255] ""  HVESP01

BO_ 2499750252 HVESP01_EstOcv_8: 8 HVESP01
 SG_ HVESP01_estOcv_01_8 m0 : 8|14@1+ (0.001,0) [0|16.383] "Ah"  HVESP01
 SG_ HVESP01_estOcv_02_8 m0 : 22|14@1+ (0.001,0) [0|16.383] "Ah"  HVESP01
 SG_ HVESP01_estOcv_03_8 m0 : 36|14@1+ (0.001,0) [0|16.383] "Ah"  HVESP01
 SG_ HVESP01_estOcv_04_8 m0 : 50|14@1+ (0.001,0) [0|16.383] "Ah"  HVESP01
 SG_ HVESP01_estOcv_05_8 m1 : 8|14@1+ (0.001,0) [0|16.383] "Ah"  HVESP01
 SG_ HVESP01_estOcv_06_8 m1 : 22|14@1+ (0.001,0) [0|16.383] "Ah"  HVESP01
 SG_ HVESP01_estOcv_07_8 m1 : 36|14@1+ (0.001,0) [0|16.383] "Ah"  HVESP01
 SG_ HVESP01_estOcv_08_8 m1 : 50|14@1+ (0.001,0) [0|16.383] "Ah"  HVESP01
 SG_ HVESP01_estOcv_09_8 m2 : 8|14@1+ (0.001,0) [0|16.383] "Ah"  HVESP01
 SG_ HVESP01_estOcv_10_8 m2 : 22|14@1+ (0.001,0) [0|16.383] "Ah"  HVESP01
 SG_ HVESP01_estOcv_11_8 m2 : 36|14@1+ (0.001,0) [0|16.383] "Ah"  HVESP01
 SG_ HVESP01_estOcv_12_8 m2 : 50|14@1+ (0.001,0) [0|16.383] "Ah"  HVESP01
 SG_ HVESP01_estOcv_13_8 m3 : 8|14@1+ (0.001,0) [0|16.383] "Ah"  HVESP01
 SG_ HVESP01_estOcv_14_8 m3 : 22|14@1+ (0.001,0) [0|16.383] "Ah"  HVESP01
 SG_ HVESP01_estOcv_15_8 m3 : 36|14@1+ (0.001,0) [0|16.383] "Ah"  HVESP01
 SG_ HVESP01_estOcv_16_8 m3 : 50|14@1+ (0.001,0) [0|16.383] "Ah"  HVESP01
 SG_ HVESP01_estOcv_17_8 m4 : 8|14@1+ (0.001,0) [0|16.383] "Ah"  HVESP01
 SG_ HVESP01_estOcv_18_8 m4 : 22|14@1+ (0.001,0) [0|16.383] "Ah"  HVESP01
 SG_ HVESP01_estOcv_19_8 m4 : 36|14@1+ (0.001,0) [0|16.383] "Ah"  HVESP01
 SG_ HVESP01_estOcv_20_8 m4 : 50|14@1+ (0.001,0) [0|16.383] "Ah"  HVESP01
 SG_ HVESP01_estOcv_21_8 m5 : 8|14@1+ (0.001,0) [0|16.383] "Ah"  HVESP01
 SG_ HVESP01_estOcv_22_8 m5 : 22|14@1+ (0.001,0) [0|16.383] "Ah"  HVESP01
 SG_ HVESP01_estOcv_23_8 m5 : 36|14@1+ (0.001,0) [0|16.383] "Ah"  HVESP01
 SG_ HVESP01_estOcv_24_8 m5 : 50|14@1+ (0.001,0) [0|16.383] "Ah"  HVESP01
 SG_ HVESP01_estOcv_25_8 m6 : 8|14@1+ (0.001,0) [0|16.383] "Ah"  HVESP01
 SG_ HVESP01_estOcv_26_8 m6 : 22|14@1+ (0.001,0) [0|16.383] "Ah"  HVESP01
 SG_ HVESP01_estOcv_27_8 m6 : 36|14@1+ (0.001,0) [0|16.383] "Ah"  HVESP01
 SG_ HVESP01_estOcv_28_8 m6 : 50|14@1+ (0.001,0) [0|16.383] "Ah"  HVESP01
 SG_ HVESP01_estOcv_29_8 m7 : 8|14@1+ (0.001,0) [0|16.383] "Ah"  HVESP01
 SG_ HVESP01_estOcv_30_8 m7 : 22|14@1+ (0.001,0) [0|16.383] "Ah"  HVESP01
 SG_ HVESP01_estOcv_31_8 m7 : 36|14@1+ (0.001,0) [0|16.383] "Ah"  HVESP01
 SG_ HVESP01_estOcv_32_8 m7 : 50|14@1+ (0.001,0) [0|16.383] "Ah"  HVESP01
 SG_ HVESP01_estOcv_33_8 m8 : 8|14@1+ (0.001,0) [0|16.383] "Ah"  HVESP01
 SG_ HVESP01_estOcv_34_8 m8 : 22|14@1+ (0.001,0) [0|16.383] "Ah"  HVESP01
 SG_ HVESP01_estOcv_35_8 m8 : 36|14@1+ (0.001,0) [0|16.383] "Ah"  HVESP01
 SG_ HVESP01_estOcv_36_8 m8 : 50|14@1+ (0.001,0) [0|16.383] "Ah"  HVESP01
 SG_ HVESP01_estOcv_37_8 m9 : 8|14@1+ (0.001,0) [0|16.383] "Ah"  HVESP01
 SG_ HVESP01_estOcv_38_8 m9 : 22|14@1+ (0.001,0) [0|16.383] "Ah"  HVESP01
 SG_ HVESP01_estOcv_39_8 m9 : 36|14@1+ (0.001,0) [0|16.383] "Ah"  HVESP01
 SG_ HVESP01_estOcv_40_8 m9 : 50|14@1+ (0.001,0) [0|16.383] "Ah"  HVESP01
 SG_ HVESP01_estOcv_41_8 m10 : 8|14@1+ (0.001,0) [0|16.383] "Ah"  HVESP01
 SG_ HVESP01_estOcv_42_8 m10 : 22|14@1+ (0.001,0) [0|16.383] "Ah"  HVESP01
 SG_ HVESP01_estOcv_43_8 m10 : 36|14@1+ (0.001,0) [0|16.383] "Ah"  HVESP01
 SG_ HVESP01_estOcv_44_8 m10 : 50|14@1+ (0.001,0) [0|16.383] "Ah"  HVESP01
 SG_ HVESP01_estOcv_45_8 m11 : 8|14@1+ (0.001,0) [0|16.383] "Ah"  HVESP01
 SG_ HVESP01_estOcv_46_8 m11 : 22|14@1+ (0.001,0) [0|16.383] "Ah"  HVESP01
 SG_ HVESP01_estOcv_47_8 m11 : 36|14@1+ (0.001,0) [0|16.383] "Ah"  HVESP01
 SG_ HVESP01_estOcv_48_8 m11 : 50|14@1+ (0.001,0) [0|16.383] "Ah"  HVESP01
 SG_ HVESP01_estOcv_49_8 m12 : 8|14@1+ (0.001,0) [0|16.383] "Ah"  HVESP01
 SG_ HVESP01_estOcv_50_8 m12 : 22|14@1+ (0.001,0) [0|16.383] "Ah"  HVESP01
 SG_ HVESP01_estOcv_51_8 m12 : 36|14@1+ (0.001,0) [0|16.383] "Ah"  HVESP01
 SG_ HVESP01_estOcv_52_8 m12 : 50|14@1+ (0.001,0) [0|16.383] "Ah"  HVESP01
 SG_ HVESP01_estOcv_53_8 m13 : 8|14@1+ (0.001,0) [0|16.383] "Ah"  HVESP01
 SG_ HVESP01_estOcv_54_8 m13 : 22|14@1+ (0.001,0) [0|16.383] "Ah"  HVESP01
 SG_ HVESP01_estOcv_55_8 m13 : 36|14@1+ (0.001,0) [0|16.383] "Ah"  HVESP01
 SG_ HVESP01_estOcv_56_8 m13 : 50|14@1+ (0.001,0) [0|16.383] "Ah"  HVESP01
 SG_ HVESP01_estOcv_57_8 m14 : 8|14@1+ (0.001,0) [0|16.383] "Ah"  HVESP01
 SG_ HVESP01_estOcv_58_8 m14 : 22|14@1+ (0.001,0) [0|16.383] "Ah"  HVESP01
 SG_ HVESP01_estOcv_59_8 m14 : 36|14@1+ (0.001,0) [0|16.383] "Ah"  HVESP01
 SG_ HVESP01_estOcv_60_8 m14 : 50|14@1+ (0.001,0) [0|16.383] "Ah"  HVESP01
 SG_ HVESP01_estOcv_61_8 m15 : 8|14@1+ (0.001,0) [0|16.383] "Ah"  HVESP01
 SG_ HVESP01_estOcv_62_8 m15 : 22|14@1+ (0.001,0) [0|16.383] "Ah"  HVESP01
 SG_ HVESP01_estOcv_63_8 m15 : 36|14@1+ (0.001,0) [0|16.383] "Ah"  HVESP01
 SG_ HVESP01_estOcv_64_8 m15 : 50|14@1+ (0.001,0) [0|16.383] "Ah"  HVESP01
 SG_ HVESP01_estOcv_65_8 m16 : 8|14@1+ (0.001,0) [0|16.383] "Ah"  HVESP01
 SG_ HVESP01_estOcv_66_8 m16 : 22|14@1+ (0.001,0) [0|16.383] "Ah"  HVESP01
 SG_ HVESP01_estOcv_67_8 m16 : 36|14@1+ (0.001,0) [0|16.383] "Ah"  HVESP01
 SG_ HVESP01_estOcv_68_8 m16 : 50|14@1+ (0.001,0) [0|16.383] "Ah"  HVESP01
 SG_ HVESP01_estOcv_69_8 m17 : 8|14@1+ (0.001,0) [0|16.383] "Ah"  HVESP01
 SG_ HVESP01_estOcv_70_8 m17 : 22|14@1+ (0.001,0) [0|16.383] "Ah"  HVESP01
 SG_ HVESP01_estOcv_71_8 m17 : 36|14@1+ (0.001,0) [0|16.383] "Ah"  HVESP01
 SG_ HVESP01_estOcv_72_8 m17 : 50|14@1+ (0.001,0) [0|16.383] "Ah"  HVESP01
 SG_ HVESP01_estOcv_73_8 m18 : 8|14@1+ (0.001,0) [0|16.383] "Ah"  HVESP01
 SG_ HVESP01_estOcv_74_8 m18 : 22|14@1+ (0.001,0) [0|16.383] "Ah"  HVESP01
 SG_ HVESP01_estOcv_75_8 m18 : 36|14@1+ (0.001,0) [0|16.383] "Ah"  HVESP01
 SG_ HVESP01_estOcv_76_8 m18 : 50|14@1+ (0.001,0) [0|16.383] "Ah"  HVESP01
 SG_ HVESP01_estOcv_77_8 m19 : 8|14@1+ (0.001,0) [0|16.383] "Ah"  HVESP01
 SG_ HVESP01_estOcv_78_8 m19 : 22|14@1+ (0.001,0) [0|16.383] "Ah"  HVESP01
 SG_ HVESP01_estOcv_79_8 m19 : 36|14@1+ (0.001,0) [0|16.383] "Ah"  HVESP01
 SG_ HVESP01_estOcv_80_8 m19 : 50|14@1+ (0.001,0) [0|16.383] "Ah"  HVESP01
 SG_ HVESP01_estOcv_81_8 m20 : 8|14@1+ (0.001,0) [0|16.383] "Ah"  HVESP01
 SG_ HVESP01_estOcv_82_8 m20 : 22|14@1+ (0.001,0) [0|16.383] "Ah"  HVESP01
 SG_ HVESP01_estOcv_83_8 m20 : 36|14@1+ (0.001,0) [0|16.383] "Ah"  HVESP01
 SG_ HVESP01_estOcv_84_8 m20 : 50|14@1+ (0.001,0) [0|16.383] "Ah"  HVESP01
 SG_ HVESP01_estOcv_85_8 m21 : 8|14@1+ (0.001,0) [0|16.383] "Ah"  HVESP01
 SG_ HVESP01_estOcv_86_8 m21 : 22|14@1+ (0.001,0) [0|16.383] "Ah"  HVESP01
 SG_ HVESP01_estOcv_87_8 m21 : 36|14@1+ (0.001,0) [0|16.383] "Ah"  HVESP01
 SG_ HVESP01_estOcv_88_8 m21 : 50|14@1+ (0.001,0) [0|16.383] "Ah"  HVESP01
 SG_ HVESP01_estOcv_89_8 m22 : 8|14@1+ (0.001,0) [0|16.383] "Ah"  HVESP01
 SG_ HVESP01_estOcv_90_8 m22 : 22|14@1+ (0.001,0) [0|16.383] "Ah"  HVESP01
 SG_ HVESP01_estOcv_91_8 m22 : 36|14@1+ (0.001,0) [0|16.383] "Ah"  HVESP01
 SG_ HVESP01_estOcv_92_8 m22 : 50|14@1+ (0.001,0) [0|16.383] "Ah"  HVESP01
 SG_ HVESP01_estOcv_93_8 m23 : 8|14@1+ (0.001,0) [0|16.383] "Ah"  HVESP01
 SG_ HVESP01_estOcv_94_8 m23 : 22|14@1+ (0.001,0) [0|16.383] "Ah"  HVESP01
 SG_ HVESP01_estOcv_95_8 m23 : 36|14@1+ (0.001,0) [0|16.383] "Ah"  HVESP01
 SG_ HVESP01_estOcv_96_8 m23 : 50|14@1+ (0.001,0) [0|16.383] "Ah"  HVESP01
 SG_ HVESP01_estOcv_97_8 m24 : 8|14@1+ (0.001,0) [0|16.383] "Ah"  HVESP01
 SG_ HVESP01_estOcv_98_8 m24 : 22|14@1+ (0.001,0) [0|16.383] "Ah"  HVESP01
 SG_ HVESP01_estOcv_99_8 m24 : 36|14@1+ (0.001,0) [0|16.383] "Ah"  HVESP01
 SG_ HVESP01_estOcv_100_8 m24 : 50|14@1+ (0.001,0) [0|16.383] "Ah"  HVESP01
 SG_ HVESP01_estOcv_101_8 m25 : 8|14@1+ (0.001,0) [0|16.383] "Ah"  HVESP01
 SG_ HVESP01_estOcv_102_8 m25 : 22|14@1+ (0.001,0) [0|16.383] "Ah"  HVESP01
 SG_ HVESP01_estOcv_103_8 m25 : 36|14@1+ (0.001,0) [0|16.383] "Ah"  HVESP01
 SG_ HVESP01_estOcv_104_8 m25 : 50|14@1+ (0.001,0) [0|16.383] "Ah"  HVESP01
 SG_ HVESP01_estOcv_105_8 m26 : 8|14@1+ (0.001,0) [0|16.383] "Ah"  HVESP01
 SG_ HVESP01_estOcv_106_8 m26 : 22|14@1+ (0.001,0) [0|16.383] "Ah"  HVESP01
 SG_ HVESP01_estOcv_107_8 m26 : 36|14@1+ (0.001,0) [0|16.383] "Ah"  HVESP01
 SG_ HVESP01_estOcv_108_8 m26 : 50|14@1+ (0.001,0) [0|16.383] "Ah"  HVESP01
 SG_ HVESP01_estOcv_109_8 m27 : 8|14@1+ (0.001,0) [0|16.383] "Ah"  HVESP01
 SG_ HVESP01_estOcv_110_8 m27 : 22|14@1+ (0.001,0) [0|16.383] "Ah"  HVESP01
 SG_ HVESP01_estOcv_111_8 m27 : 36|14@1+ (0.001,0) [0|16.383] "Ah"  HVESP01
 SG_ HVESP01_estOcv_112_8 m27 : 50|14@1+ (0.001,0) [0|16.383] "Ah"  HVESP01
 SG_ HVESP01_estOcv_113_8 m28 : 8|14@1+ (0.001,0) [0|16.383] "Ah"  HVESP01
 SG_ HVESP01_estOcv_114_8 m28 : 22|14@1+ (0.001,0) [0|16.383] "Ah"  HVESP01
 SG_ HVESP01_estOcv_115_8 m28 : 36|14@1+ (0.001,0) [0|16.383] "Ah"  HVESP01
 SG_ HVESP01_estOcv_116_8 m28 : 50|14@1+ (0.001,0) [0|16.383] "Ah"  HVESP01
 SG_ HVESP01_estOcv_117_8 m29 : 8|14@1+ (0.001,0) [0|16.383] "Ah"  HVESP01
 SG_ HVESP01_estOcv_118_8 m29 : 22|14@1+ (0.001,0) [0|16.383] "Ah"  HVESP01
 SG_ HVESP01_estOcv_119_8 m29 : 36|14@1+ (0.001,0) [0|16.383] "Ah"  HVESP01
 SG_ HVESP01_estOcv_120_8 m29 : 50|14@1+ (0.001,0) [0|16.383] "Ah"  HVESP01
 SG_ HVESP01_estOcv_121_8 m30 : 8|14@1+ (0.001,0) [0|16.383] "Ah"  HVESP01
 SG_ HVESP01_estOcv_122_8 m30 : 22|14@1+ (0.001,0) [0|16.383] "Ah"  HVESP01
 SG_ HVESP01_estOcv_123_8 m30 : 36|14@1+ (0.001,0) [0|16.383] "Ah"  HVESP01
 SG_ HVESP01_estOcv_124_8 m30 : 50|14@1+ (0.001,0) [0|16.383] "Ah"  HVESP01
 SG_ HVESP01_estOcv_125_8 m31 : 8|14@1+ (0.001,0) [0|16.383] "Ah"  HVESP01
 SG_ HVESP01_estOcv_126_8 m31 : 22|14@1+ (0.001,0) [0|16.383] "Ah"  HVESP01
 SG_ HVESP01_estOcv_127_8 m31 : 36|14@1+ (0.001,0) [0|16.383] "Ah"  HVESP01
 SG_ HVESP01_estOcv_128_8 m31 : 50|14@1+ (0.001,0) [0|16.383] "Ah"  HVESP01
 SG_ HVESP01_estOcv_129_8 m32 : 8|14@1+ (0.001,0) [0|16.383] "Ah"  HVESP01
 SG_ HVESP01_estOcv_130_8 m32 : 22|14@1+ (0.001,0) [0|16.383] "Ah"  HVESP01
 SG_ HVESP01_estOcv_131_8 m32 : 36|14@1+ (0.001,0) [0|16.383] "Ah"  HVESP01
 SG_ HVESP01_estOcv_132_8 m32 : 50|14@1+ (0.001,0) [0|16.383] "Ah"  HVESP01
 SG_ HVESP01_estOcv_133_8 m33 : 8|14@1+ (0.001,0) [0|16.383] "Ah"  HVESP01
 SG_ HVESP01_estOcv_134_8 m33 : 22|14@1+ (0.001,0) [0|16.383] "Ah"  HVESP01
 SG_ HVESP01_estOcv_135_8 m33 : 36|14@1+ (0.001,0) [0|16.383] "Ah"  HVESP01
 SG_ HVESP01_estOcv_136_8 m33 : 50|14@1+ (0.001,0) [0|16.383] "Ah"  HVESP01
 SG_ HVESP01_estOcv_137_8 m34 : 8|14@1+ (0.001,0) [0|16.383] "Ah"  HVESP01
 SG_ HVESP01_estOcv_138_8 m34 : 22|14@1+ (0.001,0) [0|16.383] "Ah"  HVESP01
 SG_ HVESP01_estOcv_139_8 m34 : 36|14@1+ (0.001,0) [0|16.383] "Ah"  HVESP01
 SG_ HVESP01_estOcv_140_8 m34 : 50|14@1+ (0.001,0) [0|16.383] "Ah"  HVESP01
 SG_ HVESP01_estOcv_141_8 m35 : 8|14@1+ (0.001,0) [0|16.383] "Ah"  HVESP01
 SG_ HVESP01_estOcv_142_8 m35 : 22|14@1+ (0.001,0) [0|16.383] "Ah"  HVESP01
 SG_ HVESP01_estOcv_143_8 m35 : 36|14@1+ (0.001,0) [0|16.383] "Ah"  HVESP01
 SG_ HVESP01_estOcv_144_8 m35 : 50|14@1+ (0.001,0) [0|16.383] "Ah"  HVESP01
 SG_ HVESP01_estOcv_145_8 m36 : 8|14@1+ (0.001,0) [0|16.383] "Ah"  HVESP01
 SG_ HVESP01_estOcv_146_8 m36 : 22|14@1+ (0.001,0) [0|16.383] "Ah"  HVESP01
 SG_ HVESP01_estOcv_147_8 m36 : 36|14@1+ (0.001,0) [0|16.383] "Ah"  HVESP01
 SG_ HVESP01_estOcv_148_8 m36 : 50|14@1+ (0.001,0) [0|16.383] "Ah"  HVESP01
 SG_ HVESP01_estOcv_149_8 m37 : 8|14@1+ (0.001,0) [0|16.383] "Ah"  HVESP01
 SG_ HVESP01_estOcv_150_8 m37 : 22|14@1+ (0.001,0) [0|16.383] "Ah"  HVESP01
 SG_ HVESP01_estOcv_151_8 m37 : 36|14@1+ (0.001,0) [0|16.383] "Ah"  HVESP01
 SG_ HVESP01_estOcv_152_8 m37 : 50|14@1+ (0.001,0) [0|16.383] "Ah"  HVESP01
 SG_ HVESP01_estOcv_153_8 m38 : 8|14@1+ (0.001,0) [0|16.383] "Ah"  HVESP01
 SG_ HVESP01_estOcv_154_8 m38 : 22|14@1+ (0.001,0) [0|16.383] "Ah"  HVESP01
 SG_ HVESP01_estOcv_155_8 m38 : 36|14@1+ (0.001,0) [0|16.383] "Ah"  HVESP01
 SG_ HVESP01_estOcv_156_8 m38 : 50|14@1+ (0.001,0) [0|16.383] "Ah"  HVESP01
 SG_ HVESP01_estOcv_157_8 m39 : 8|14@1+ (0.001,0) [0|16.383] "Ah"  HVESP01
 SG_ HVESP01_estOcv_158_8 m39 : 22|14@1+ (0.001,0) [0|16.383] "Ah"  HVESP01
 SG_ HVESP01_estOcv_159_8 m39 : 36|14@1+ (0.001,0) [0|16.383] "Ah"  HVESP01
 SG_ HVESP01_estOcv_160_8 m39 : 50|14@1+ (0.001,0) [0|16.383] "Ah"  HVESP01
 SG_ HVESP01_estOcv_161_8 m40 : 8|14@1+ (0.001,0) [0|16.383] "Ah"  HVESP01
 SG_ HVESP01_estOcv_162_8 m40 : 22|14@1+ (0.001,0) [0|16.383] "Ah"  HVESP01
 SG_ HVESP01_estOcv_163_8 m40 : 36|14@1+ (0.001,0) [0|16.383] "Ah"  HVESP01
 SG_ HVESP01_estOcv_164_8 m40 : 50|14@1+ (0.001,0) [0|16.383] "Ah"  HVESP01
 SG_ HVESP01_estOcv_165_8 m41 : 8|14@1+ (0.001,0) [0|16.383] "Ah"  HVESP01
 SG_ HVESP01_estOcv_166_8 m41 : 22|14@1+ (0.001,0) [0|16.383] "Ah"  HVESP01
 SG_ HVESP01_estOcv_167_8 m41 : 36|14@1+ (0.001,0) [0|16.383] "Ah"  HVESP01
 SG_ HVESP01_estOcv_168_8 m41 : 50|14@1+ (0.001,0) [0|16.383] "Ah"  HVESP01
 SG_ HVESP01_estOcv_169_8 m42 : 8|14@1+ (0.001,0) [0|16.383] "Ah"  HVESP01
 SG_ HVESP01_estOcv_170_8 m42 : 22|14@1+ (0.001,0) [0|16.383] "Ah"  HVESP01
 SG_ HVESP01_estOcv_171_8 m42 : 36|14@1+ (0.001,0) [0|16.383] "Ah"  HVESP01
 SG_ HVESP01_estOcv_172_8 m42 : 50|14@1+ (0.001,0) [0|16.383] "Ah"  HVESP01
 SG_ HVESP01_estOcv_173_8 m43 : 8|14@1+ (0.001,0) [0|16.383] "Ah"  HVESP01
 SG_ HVESP01_estOcv_174_8 m43 : 22|14@1+ (0.001,0) [0|16.383] "Ah"  HVESP01
 SG_ HVESP01_estOcv_175_8 m43 : 36|14@1+ (0.001,0) [0|16.383] "Ah"  HVESP01
 SG_ HVESP01_estOcv_176_8 m43 : 50|14@1+ (0.001,0) [0|16.383] "Ah"  HVESP01
 SG_ HVESP01_estOcv_177_8 m44 : 8|14@1+ (0.001,0) [0|16.383] "Ah"  HVESP01
 SG_ HVESP01_estOcv_178_8 m44 : 22|14@1+ (0.001,0) [0|16.383] "Ah"  HVESP01
 SG_ HVESP01_estOcv_179_8 m44 : 36|14@1+ (0.001,0) [0|16.383] "Ah"  HVESP01
 SG_ HVESP01_estOcv_180_8 m44 : 50|14@1+ (0.001,0) [0|16.383] "Ah"  HVESP01
 SG_ multiplexoreo_8 M : 0|8@1+ (1,0) [0|255] ""  HVESP01

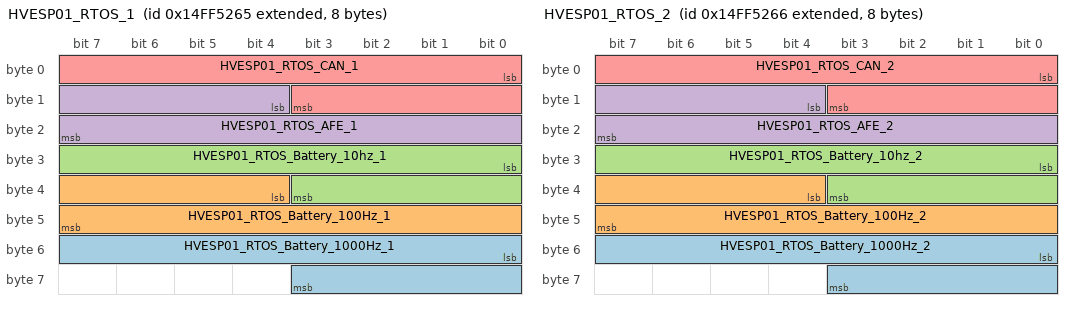
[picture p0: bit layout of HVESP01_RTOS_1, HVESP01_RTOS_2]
BO_ 2499760741 HVESP01_RTOS_1: 8 HVESP01
 SG_ HVESP01_RTOS_Battery_1000Hz_1 : 48|12@1+ (1,0) [0|4095] ""  HVESP01
 SG_ HVESP01_RTOS_Battery_100Hz_1 : 36|12@1+ (1,0) [0|4095] ""  HVESP01
 SG_ HVESP01_RTOS_Battery_10hz_1 : 24|12@1+ (1,0) [0|4095] ""  HVESP01
 SG_ HVESP01_RTOS_AFE_1 : 12|12@1+ (1,0) [0|4095] ""  HVESP01
 SG_ HVESP01_RTOS_CAN_1 : 0|12@1+ (1,0) [0|4095] ""  HVESP01

BO_ 2499760742 HVESP01_RTOS_2: 8 HVESP01
 SG_ HVESP01_RTOS_Battery_1000Hz_2 : 48|12@1+ (1,0) [0|4095] ""  HVESP01
 SG_ HVESP01_RTOS_Battery_100Hz_2 : 36|12@1+ (1,0) [0|4095] ""  HVESP01
 SG_ HVESP01_RTOS_Battery_10hz_2 : 24|12@1+ (1,0) [0|4095] ""  HVESP01
 SG_ HVESP01_RTOS_AFE_2 : 12|12@1+ (1,0) [0|4095] ""  HVESP01
 SG_ HVESP01_RTOS_CAN_2 : 0|12@1+ (1,0) [0|4095] ""  HVESP01

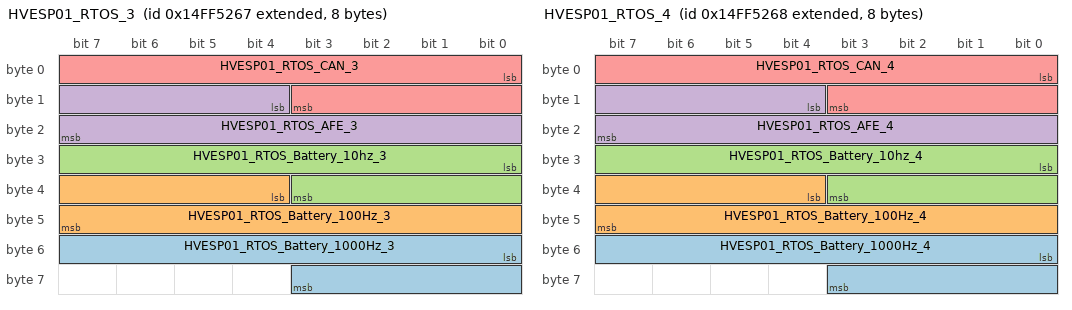
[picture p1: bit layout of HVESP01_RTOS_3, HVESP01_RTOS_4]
BO_ 2499760743 HVESP01_RTOS_3: 8 HVESP01
 SG_ HVESP01_RTOS_Battery_1000Hz_3 : 48|12@1+ (1,0) [0|4095] ""  HVESP01
 SG_ HVESP01_RTOS_Battery_100Hz_3 : 36|12@1+ (1,0) [0|4095] ""  HVESP01
 SG_ HVESP01_RTOS_Battery_10hz_3 : 24|12@1+ (1,0) [0|4095] ""  HVESP01
 SG_ HVESP01_RTOS_AFE_3 : 12|12@1+ (1,0) [0|4095] ""  HVESP01
 SG_ HVESP01_RTOS_CAN_3 : 0|12@1+ (1,0) [0|4095] ""  HVESP01

BO_ 2499760744 HVESP01_RTOS_4: 8 HVESP01
 SG_ HVESP01_RTOS_Battery_1000Hz_4 : 48|12@1+ (1,0) [0|4095] ""  HVESP01
 SG_ HVESP01_RTOS_Battery_100Hz_4 : 36|12@1+ (1,0) [0|4095] ""  HVESP01
 SG_ HVESP01_RTOS_Battery_10hz_4 : 24|12@1+ (1,0) [0|4095] ""  HVESP01
 SG_ HVESP01_RTOS_AFE_4 : 12|12@1+ (1,0) [0|4095] ""  HVESP01
 SG_ HVESP01_RTOS_CAN_4 : 0|12@1+ (1,0) [0|4095] ""  HVESP01

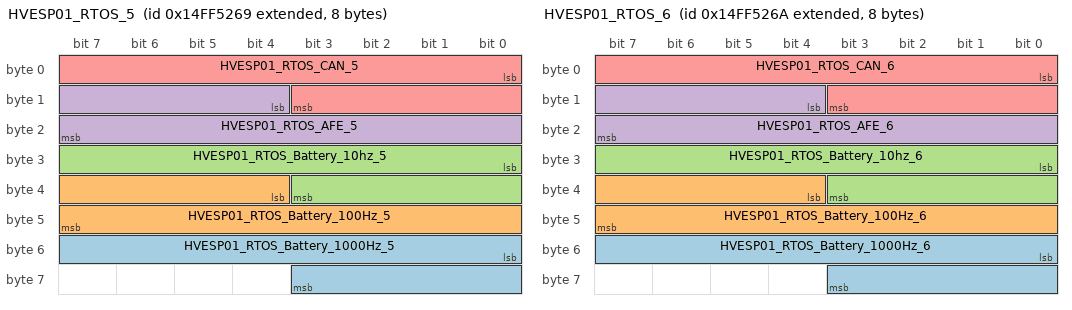
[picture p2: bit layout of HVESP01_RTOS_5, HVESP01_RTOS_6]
BO_ 2499760745 HVESP01_RTOS_5: 8 HVESP01
 SG_ HVESP01_RTOS_Battery_1000Hz_5 : 48|12@1+ (1,0) [0|4095] ""  HVESP01
 SG_ HVESP01_RTOS_Battery_100Hz_5 : 36|12@1+ (1,0) [0|4095] ""  HVESP01
 SG_ HVESP01_RTOS_Battery_10hz_5 : 24|12@1+ (1,0) [0|4095] ""  HVESP01
 SG_ HVESP01_RTOS_AFE_5 : 12|12@1+ (1,0) [0|4095] ""  HVESP01
 SG_ HVESP01_RTOS_CAN_5 : 0|12@1+ (1,0) [0|4095] ""  HVESP01

BO_ 2499760746 HVESP01_RTOS_6: 8 HVESP01
 SG_ HVESP01_RTOS_Battery_1000Hz_6 : 48|12@1+ (1,0) [0|4095] ""  HVESP01
 SG_ HVESP01_RTOS_Battery_100Hz_6 : 36|12@1+ (1,0) [0|4095] ""  HVESP01
 SG_ HVESP01_RTOS_Battery_10hz_6 : 24|12@1+ (1,0) [0|4095] ""  HVESP01
 SG_ HVESP01_RTOS_AFE_6 : 12|12@1+ (1,0) [0|4095] ""  HVESP01
 SG_ HVESP01_RTOS_CAN_6 : 0|12@1+ (1,0) [0|4095] ""  HVESP01

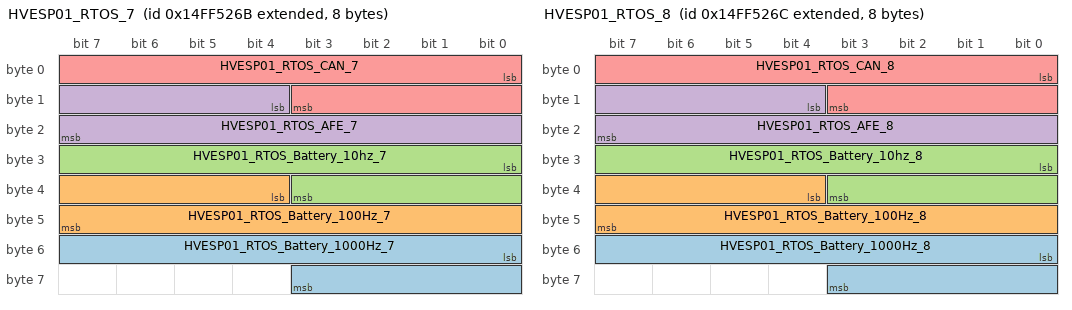
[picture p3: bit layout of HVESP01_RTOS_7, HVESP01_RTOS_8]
BO_ 2499760747 HVESP01_RTOS_7: 8 HVESP01
 SG_ HVESP01_RTOS_Battery_1000Hz_7 : 48|12@1+ (1,0) [0|4095] ""  HVESP01
 SG_ HVESP01_RTOS_Battery_100Hz_7 : 36|12@1+ (1,0) [0|4095] ""  HVESP01
 SG_ HVESP01_RTOS_Battery_10hz_7 : 24|12@1+ (1,0) [0|4095] ""  HVESP01
 SG_ HVESP01_RTOS_AFE_7 : 12|12@1+ (1,0) [0|4095] ""  HVESP01
 SG_ HVESP01_RTOS_CAN_7 : 0|12@1+ (1,0) [0|4095] ""  HVESP01

BO_ 2499760748 HVESP01_RTOS_8: 8 HVESP01
 SG_ HVESP01_RTOS_Battery_1000Hz_8 : 48|12@1+ (1,0) [0|4095] ""  HVESP01
 SG_ HVESP01_RTOS_Battery_100Hz_8 : 36|12@1+ (1,0) [0|4095] ""  HVESP01
 SG_ HVESP01_RTOS_Battery_10hz_8 : 24|12@1+ (1,0) [0|4095] ""  HVESP01
 SG_ HVESP01_RTOS_AFE_8 : 12|12@1+ (1,0) [0|4095] ""  HVESP01
 SG_ HVESP01_RTOS_CAN_8 : 0|12@1+ (1,0) [0|4095] ""  HVESP01

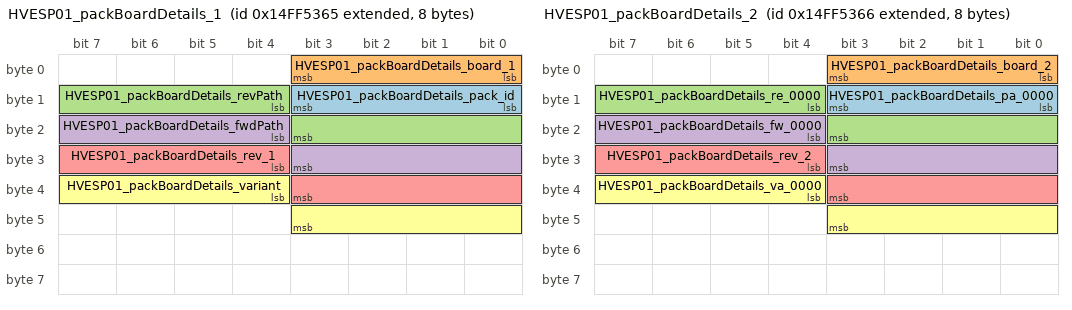
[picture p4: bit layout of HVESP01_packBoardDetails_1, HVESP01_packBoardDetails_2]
BO_ 2499760997 HVESP01_packBoardDetails_1: 8 HVESP01
 SG_ HVESP01_packBoardDetails_pack_id : 8|4@1+ (1,0) [0|15] ""  HVESP01
 SG_ HVESP01_packBoardDetails_board_1 : 0|4@1+ (1,0) [0|15] ""  HVESP01
 SG_ HVESP01_packBoardDetails_revPath : 12|8@1+ (1,0) [0|255] ""  HVESP01
 SG_ HVESP01_packBoardDetails_fwdPath : 20|8@1+ (1,0) [0|255] ""  HVESP01
 SG_ HVESP01_packBoardDetails_rev_1 : 28|8@1+ (1,0) [0|255] ""  HVESP01
 SG_ HVESP01_packBoardDetails_variant : 36|8@1+ (1,0) [0|255] ""  HVESP01

BO_ 2499760998 HVESP01_packBoardDetails_2: 8 HVESP01
 SG_ HVESP01_packBoardDetails_pa_0000 : 8|4@1+ (1,0) [0|15] ""  HVESP01
 SG_ HVESP01_packBoardDetails_board_2 : 0|4@1+ (1,0) [0|15] ""  HVESP01
 SG_ HVESP01_packBoardDetails_re_0000 : 12|8@1+ (1,0) [0|255] ""  HVESP01
 SG_ HVESP01_packBoardDetails_fw_0000 : 20|8@1+ (1,0) [0|255] ""  HVESP01
 SG_ HVESP01_packBoardDetails_rev_2 : 28|8@1+ (1,0) [0|255] ""  HVESP01
 SG_ HVESP01_packBoardDetails_va_0000 : 36|8@1+ (1,0) [0|255] ""  HVESP01

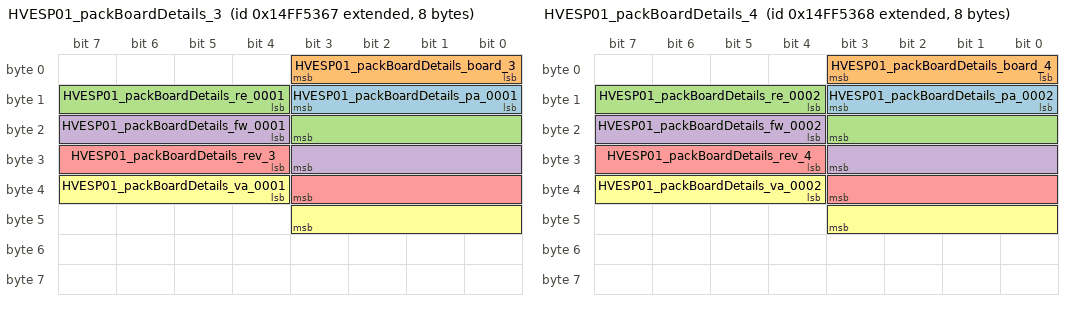
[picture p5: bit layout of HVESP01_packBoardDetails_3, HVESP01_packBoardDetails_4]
BO_ 2499760999 HVESP01_packBoardDetails_3: 8 HVESP01
 SG_ HVESP01_packBoardDetails_pa_0001 : 8|4@1+ (1,0) [0|15] ""  HVESP01
 SG_ HVESP01_packBoardDetails_board_3 : 0|4@1+ (1,0) [0|15] ""  HVESP01
 SG_ HVESP01_packBoardDetails_re_0001 : 12|8@1+ (1,0) [0|255] ""  HVESP01
 SG_ HVESP01_packBoardDetails_fw_0001 : 20|8@1+ (1,0) [0|255] ""  HVESP01
 SG_ HVESP01_packBoardDetails_rev_3 : 28|8@1+ (1,0) [0|255] ""  HVESP01
 SG_ HVESP01_packBoardDetails_va_0001 : 36|8@1+ (1,0) [0|255] ""  HVESP01

BO_ 2499761000 HVESP01_packBoardDetails_4: 8 HVESP01
 SG_ HVESP01_packBoardDetails_pa_0002 : 8|4@1+ (1,0) [0|15] ""  HVESP01
 SG_ HVESP01_packBoardDetails_board_4 : 0|4@1+ (1,0) [0|15] ""  HVESP01
 SG_ HVESP01_packBoardDetails_re_0002 : 12|8@1+ (1,0) [0|255] ""  HVESP01
 SG_ HVESP01_packBoardDetails_fw_0002 : 20|8@1+ (1,0) [0|255] ""  HVESP01
 SG_ HVESP01_packBoardDetails_rev_4 : 28|8@1+ (1,0) [0|255] ""  HVESP01
 SG_ HVESP01_packBoardDetails_va_0002 : 36|8@1+ (1,0) [0|255] ""  HVESP01

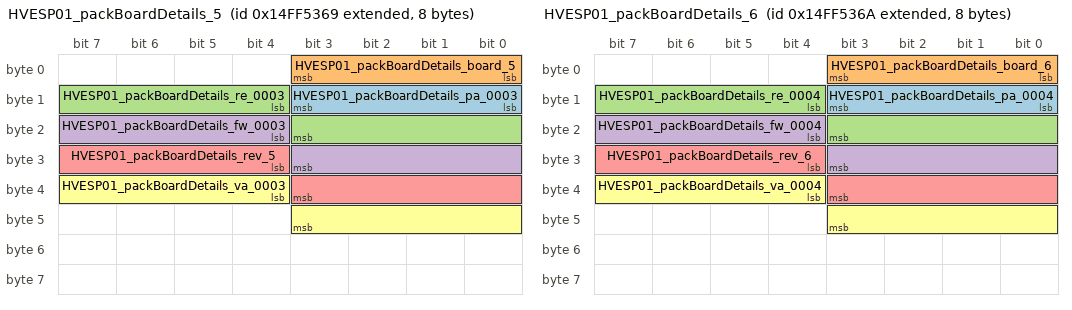
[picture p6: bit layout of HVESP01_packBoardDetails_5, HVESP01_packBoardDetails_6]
BO_ 2499761001 HVESP01_packBoardDetails_5: 8 HVESP01
 SG_ HVESP01_packBoardDetails_pa_0003 : 8|4@1+ (1,0) [0|15] ""  HVESP01
 SG_ HVESP01_packBoardDetails_board_5 : 0|4@1+ (1,0) [0|15] ""  HVESP01
 SG_ HVESP01_packBoardDetails_re_0003 : 12|8@1+ (1,0) [0|255] ""  HVESP01
 SG_ HVESP01_packBoardDetails_fw_0003 : 20|8@1+ (1,0) [0|255] ""  HVESP01
 SG_ HVESP01_packBoardDetails_rev_5 : 28|8@1+ (1,0) [0|255] ""  HVESP01
 SG_ HVESP01_packBoardDetails_va_0003 : 36|8@1+ (1,0) [0|255] ""  HVESP01

BO_ 2499761002 HVESP01_packBoardDetails_6: 8 HVESP01
 SG_ HVESP01_packBoardDetails_pa_0004 : 8|4@1+ (1,0) [0|15] ""  HVESP01
 SG_ HVESP01_packBoardDetails_board_6 : 0|4@1+ (1,0) [0|15] ""  HVESP01
 SG_ HVESP01_packBoardDetails_re_0004 : 12|8@1+ (1,0) [0|255] ""  HVESP01
 SG_ HVESP01_packBoardDetails_fw_0004 : 20|8@1+ (1,0) [0|255] ""  HVESP01
 SG_ HVESP01_packBoardDetails_rev_6 : 28|8@1+ (1,0) [0|255] ""  HVESP01
 SG_ HVESP01_packBoardDetails_va_0004 : 36|8@1+ (1,0) [0|255] ""  HVESP01

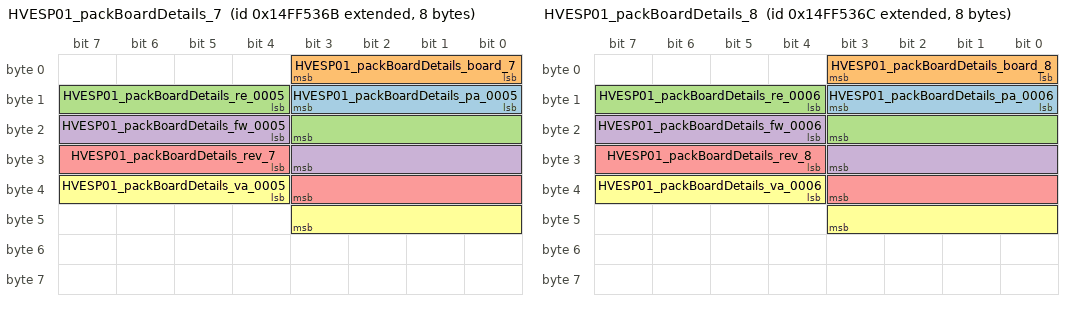
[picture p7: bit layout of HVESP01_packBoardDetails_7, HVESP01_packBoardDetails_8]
BO_ 2499761003 HVESP01_packBoardDetails_7: 8 HVESP01
 SG_ HVESP01_packBoardDetails_pa_0005 : 8|4@1+ (1,0) [0|15] ""  HVESP01
 SG_ HVESP01_packBoardDetails_board_7 : 0|4@1+ (1,0) [0|15] ""  HVESP01
 SG_ HVESP01_packBoardDetails_re_0005 : 12|8@1+ (1,0) [0|255] ""  HVESP01
 SG_ HVESP01_packBoardDetails_fw_0005 : 20|8@1+ (1,0) [0|255] ""  HVESP01
 SG_ HVESP01_packBoardDetails_rev_7 : 28|8@1+ (1,0) [0|255] ""  HVESP01
 SG_ HVESP01_packBoardDetails_va_0005 : 36|8@1+ (1,0) [0|255] ""  HVESP01

BO_ 2499761004 HVESP01_packBoardDetails_8: 8 HVESP01
 SG_ HVESP01_packBoardDetails_pa_0006 : 8|4@1+ (1,0) [0|15] ""  HVESP01
 SG_ HVESP01_packBoardDetails_board_8 : 0|4@1+ (1,0) [0|15] ""  HVESP01
 SG_ HVESP01_packBoardDetails_re_0006 : 12|8@1+ (1,0) [0|255] ""  HVESP01
 SG_ HVESP01_packBoardDetails_fw_0006 : 20|8@1+ (1,0) [0|255] ""  HVESP01
 SG_ HVESP01_packBoardDetails_rev_8 : 28|8@1+ (1,0) [0|255] ""  HVESP01
 SG_ HVESP01_packBoardDetails_va_0006 : 36|8@1+ (1,0) [0|255] ""  HVESP01

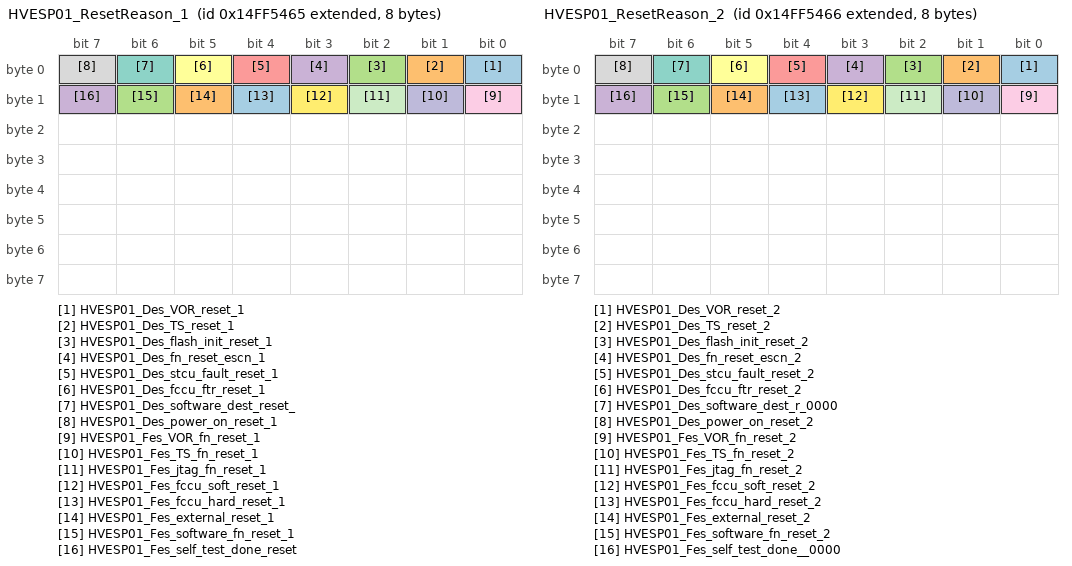
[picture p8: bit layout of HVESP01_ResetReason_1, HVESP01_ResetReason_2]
BO_ 2499761253 HVESP01_ResetReason_1: 8 HVESP01
 SG_ HVESP01_Des_VOR_reset_1 : 0|1@0+ (1,0) [0|1] "B"  HVESP01
 SG_ HVESP01_Des_TS_reset_1 : 1|1@0+ (1,0) [0|1] "B"  HVESP01
 SG_ HVESP01_Des_flash_init_reset_1 : 2|1@0+ (1,0) [0|1] "B"  HVESP01
 SG_ HVESP01_Des_fn_reset_escn_1 : 3|1@0+ (1,0) [0|1] "B"  HVESP01
 SG_ HVESP01_Des_stcu_fault_reset_1 : 4|1@0+ (1,0) [0|1] "B"  HVESP01
 SG_ HVESP01_Des_fccu_ftr_reset_1 : 5|1@0+ (1,0) [0|1] "B"  HVESP01
 SG_ HVESP01_Des_software_dest_reset_ : 6|1@0+ (1,0) [0|1] "B"  HVESP01
 SG_ HVESP01_Des_power_on_reset_1 : 7|1@0+ (1,0) [0|1] "B"  HVESP01
 SG_ HVESP01_Fes_VOR_fn_reset_1 : 8|1@0+ (1,0) [0|1] "B"  HVESP01
 SG_ HVESP01_Fes_TS_fn_reset_1 : 9|1@0+ (1,0) [0|1] "B"  HVESP01
 SG_ HVESP01_Fes_jtag_fn_reset_1 : 10|1@0+ (1,0) [0|1] "B"  HVESP01
 SG_ HVESP01_Fes_fccu_soft_reset_1 : 11|1@0+ (1,0) [0|1] "B"  HVESP01
 SG_ HVESP01_Fes_fccu_hard_reset_1 : 12|1@0+ (1,0) [0|1] "B"  HVESP01
 SG_ HVESP01_Fes_external_reset_1 : 13|1@0+ (1,0) [0|1] "B"  HVESP01
 SG_ HVESP01_Fes_software_fn_reset_1 : 14|1@0+ (1,0) [0|1] "B"  HVESP01
 SG_ HVESP01_Fes_self_test_done_reset : 15|1@0+ (1,0) [0|1] "B"  HVESP01

BO_ 2499761254 HVESP01_ResetReason_2: 8 HVESP01
 SG_ HVESP01_Des_VOR_reset_2 : 0|1@0+ (1,0) [0|1] "B"  HVESP01
 SG_ HVESP01_Des_TS_reset_2 : 1|1@0+ (1,0) [0|1] "B"  HVESP01
 SG_ HVESP01_Des_flash_init_reset_2 : 2|1@0+ (1,0) [0|1] "B"  HVESP01
 SG_ HVESP01_Des_fn_reset_escn_2 : 3|1@0+ (1,0) [0|1] "B"  HVESP01
 SG_ HVESP01_Des_stcu_fault_reset_2 : 4|1@0+ (1,0) [0|1] "B"  HVESP01
 SG_ HVESP01_Des_fccu_ftr_reset_2 : 5|1@0+ (1,0) [0|1] "B"  HVESP01
 SG_ HVESP01_Des_software_dest_r_0000 : 6|1@0+ (1,0) [0|1] "B"  HVESP01
 SG_ HVESP01_Des_power_on_reset_2 : 7|1@0+ (1,0) [0|1] "B"  HVESP01
 SG_ HVESP01_Fes_VOR_fn_reset_2 : 8|1@0+ (1,0) [0|1] "B"  HVESP01
 SG_ HVESP01_Fes_TS_fn_reset_2 : 9|1@0+ (1,0) [0|1] "B"  HVESP01
 SG_ HVESP01_Fes_jtag_fn_reset_2 : 10|1@0+ (1,0) [0|1] "B"  HVESP01
 SG_ HVESP01_Fes_fccu_soft_reset_2 : 11|1@0+ (1,0) [0|1] "B"  HVESP01
 SG_ HVESP01_Fes_fccu_hard_reset_2 : 12|1@0+ (1,0) [0|1] "B"  HVESP01
 SG_ HVESP01_Fes_external_reset_2 : 13|1@0+ (1,0) [0|1] "B"  HVESP01
 SG_ HVESP01_Fes_software_fn_reset_2 : 14|1@0+ (1,0) [0|1] "B"  HVESP01
 SG_ HVESP01_Fes_self_test_done__0000 : 15|1@0+ (1,0) [0|1] "B"  HVESP01

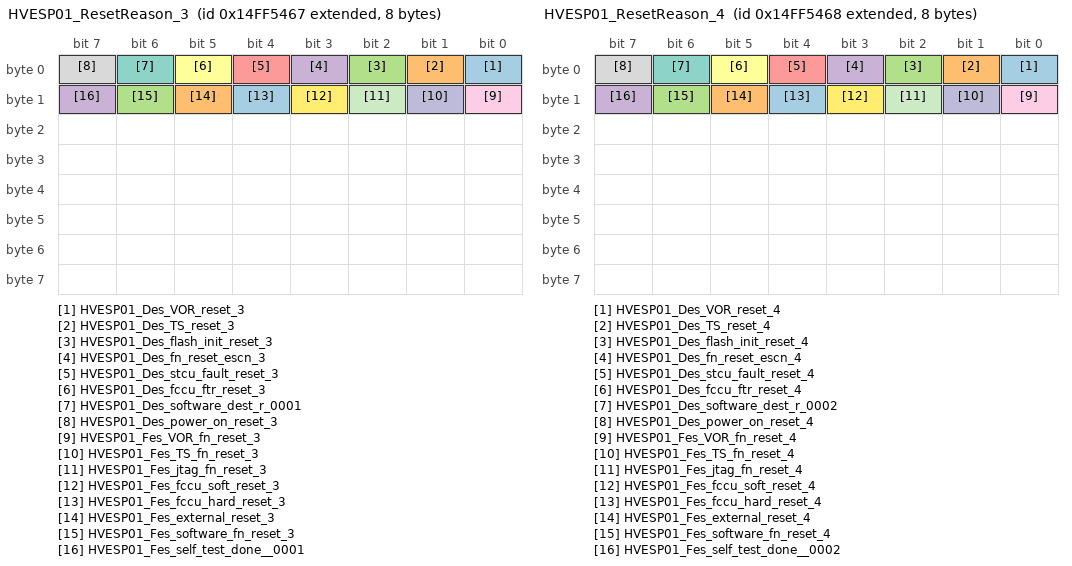
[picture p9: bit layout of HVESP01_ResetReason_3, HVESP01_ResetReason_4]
BO_ 2499761255 HVESP01_ResetReason_3: 8 HVESP01
 SG_ HVESP01_Des_VOR_reset_3 : 0|1@0+ (1,0) [0|1] "B"  HVESP01
 SG_ HVESP01_Des_TS_reset_3 : 1|1@0+ (1,0) [0|1] "B"  HVESP01
 SG_ HVESP01_Des_flash_init_reset_3 : 2|1@0+ (1,0) [0|1] "B"  HVESP01
 SG_ HVESP01_Des_fn_reset_escn_3 : 3|1@0+ (1,0) [0|1] "B"  HVESP01
 SG_ HVESP01_Des_stcu_fault_reset_3 : 4|1@0+ (1,0) [0|1] "B"  HVESP01
 SG_ HVESP01_Des_fccu_ftr_reset_3 : 5|1@0+ (1,0) [0|1] "B"  HVESP01
 SG_ HVESP01_Des_software_dest_r_0001 : 6|1@0+ (1,0) [0|1] "B"  HVESP01
 SG_ HVESP01_Des_power_on_reset_3 : 7|1@0+ (1,0) [0|1] "B"  HVESP01
 SG_ HVESP01_Fes_VOR_fn_reset_3 : 8|1@0+ (1,0) [0|1] "B"  HVESP01
 SG_ HVESP01_Fes_TS_fn_reset_3 : 9|1@0+ (1,0) [0|1] "B"  HVESP01
 SG_ HVESP01_Fes_jtag_fn_reset_3 : 10|1@0+ (1,0) [0|1] "B"  HVESP01
 SG_ HVESP01_Fes_fccu_soft_reset_3 : 11|1@0+ (1,0) [0|1] "B"  HVESP01
 SG_ HVESP01_Fes_fccu_hard_reset_3 : 12|1@0+ (1,0) [0|1] "B"  HVESP01
 SG_ HVESP01_Fes_external_reset_3 : 13|1@0+ (1,0) [0|1] "B"  HVESP01
 SG_ HVESP01_Fes_software_fn_reset_3 : 14|1@0+ (1,0) [0|1] "B"  HVESP01
 SG_ HVESP01_Fes_self_test_done__0001 : 15|1@0+ (1,0) [0|1] "B"  HVESP01

BO_ 2499761256 HVESP01_ResetReason_4: 8 HVESP01
 SG_ HVESP01_Des_VOR_reset_4 : 0|1@0+ (1,0) [0|1] "B"  HVESP01
 SG_ HVESP01_Des_TS_reset_4 : 1|1@0+ (1,0) [0|1] "B"  HVESP01
 SG_ HVESP01_Des_flash_init_reset_4 : 2|1@0+ (1,0) [0|1] "B"  HVESP01
 SG_ HVESP01_Des_fn_reset_escn_4 : 3|1@0+ (1,0) [0|1] "B"  HVESP01
 SG_ HVESP01_Des_stcu_fault_reset_4 : 4|1@0+ (1,0) [0|1] "B"  HVESP01
 SG_ HVESP01_Des_fccu_ftr_reset_4 : 5|1@0+ (1,0) [0|1] "B"  HVESP01
 SG_ HVESP01_Des_software_dest_r_0002 : 6|1@0+ (1,0) [0|1] "B"  HVESP01
 SG_ HVESP01_Des_power_on_reset_4 : 7|1@0+ (1,0) [0|1] "B"  HVESP01
 SG_ HVESP01_Fes_VOR_fn_reset_4 : 8|1@0+ (1,0) [0|1] "B"  HVESP01
 SG_ HVESP01_Fes_TS_fn_reset_4 : 9|1@0+ (1,0) [0|1] "B"  HVESP01
 SG_ HVESP01_Fes_jtag_fn_reset_4 : 10|1@0+ (1,0) [0|1] "B"  HVESP01
 SG_ HVESP01_Fes_fccu_soft_reset_4 : 11|1@0+ (1,0) [0|1] "B"  HVESP01
 SG_ HVESP01_Fes_fccu_hard_reset_4 : 12|1@0+ (1,0) [0|1] "B"  HVESP01
 SG_ HVESP01_Fes_external_reset_4 : 13|1@0+ (1,0) [0|1] "B"  HVESP01
 SG_ HVESP01_Fes_software_fn_reset_4 : 14|1@0+ (1,0) [0|1] "B"  HVESP01
 SG_ HVESP01_Fes_self_test_done__0002 : 15|1@0+ (1,0) [0|1] "B"  HVESP01

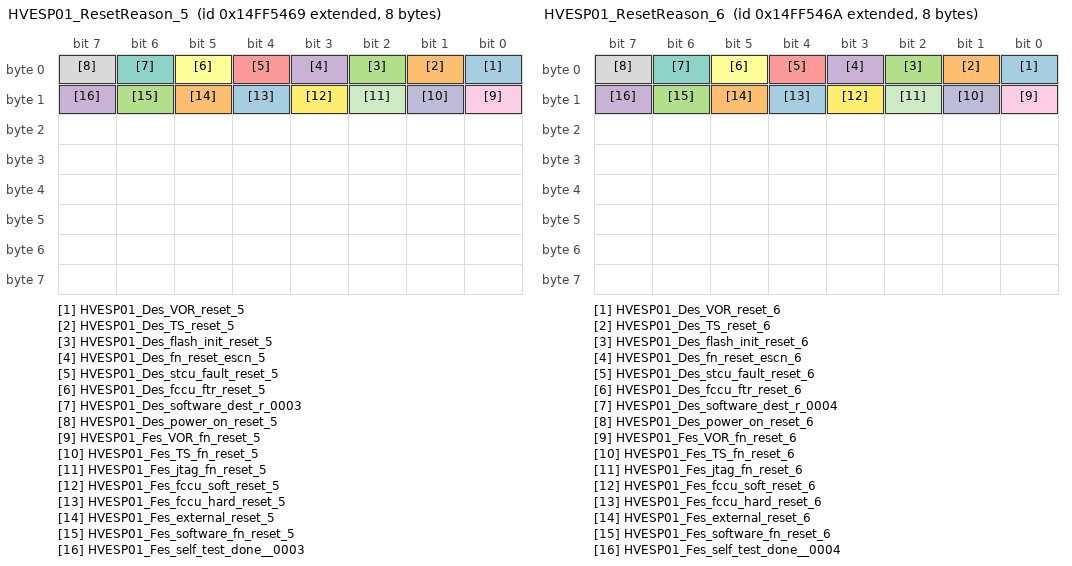
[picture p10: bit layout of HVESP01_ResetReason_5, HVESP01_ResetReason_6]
BO_ 2499761257 HVESP01_ResetReason_5: 8 HVESP01
 SG_ HVESP01_Des_VOR_reset_5 : 0|1@0+ (1,0) [0|1] "B"  HVESP01
 SG_ HVESP01_Des_TS_reset_5 : 1|1@0+ (1,0) [0|1] "B"  HVESP01
 SG_ HVESP01_Des_flash_init_reset_5 : 2|1@0+ (1,0) [0|1] "B"  HVESP01
 SG_ HVESP01_Des_fn_reset_escn_5 : 3|1@0+ (1,0) [0|1] "B"  HVESP01
 SG_ HVESP01_Des_stcu_fault_reset_5 : 4|1@0+ (1,0) [0|1] "B"  HVESP01
 SG_ HVESP01_Des_fccu_ftr_reset_5 : 5|1@0+ (1,0) [0|1] "B"  HVESP01
 SG_ HVESP01_Des_software_dest_r_0003 : 6|1@0+ (1,0) [0|1] "B"  HVESP01
 SG_ HVESP01_Des_power_on_reset_5 : 7|1@0+ (1,0) [0|1] "B"  HVESP01
 SG_ HVESP01_Fes_VOR_fn_reset_5 : 8|1@0+ (1,0) [0|1] "B"  HVESP01
 SG_ HVESP01_Fes_TS_fn_reset_5 : 9|1@0+ (1,0) [0|1] "B"  HVESP01
 SG_ HVESP01_Fes_jtag_fn_reset_5 : 10|1@0+ (1,0) [0|1] "B"  HVESP01
 SG_ HVESP01_Fes_fccu_soft_reset_5 : 11|1@0+ (1,0) [0|1] "B"  HVESP01
 SG_ HVESP01_Fes_fccu_hard_reset_5 : 12|1@0+ (1,0) [0|1] "B"  HVESP01
 SG_ HVESP01_Fes_external_reset_5 : 13|1@0+ (1,0) [0|1] "B"  HVESP01
 SG_ HVESP01_Fes_software_fn_reset_5 : 14|1@0+ (1,0) [0|1] "B"  HVESP01
 SG_ HVESP01_Fes_self_test_done__0003 : 15|1@0+ (1,0) [0|1] "B"  HVESP01

BO_ 2499761258 HVESP01_ResetReason_6: 8 HVESP01
 SG_ HVESP01_Des_VOR_reset_6 : 0|1@0+ (1,0) [0|1] "B"  HVESP01
 SG_ HVESP01_Des_TS_reset_6 : 1|1@0+ (1,0) [0|1] "B"  HVESP01
 SG_ HVESP01_Des_flash_init_reset_6 : 2|1@0+ (1,0) [0|1] "B"  HVESP01
 SG_ HVESP01_Des_fn_reset_escn_6 : 3|1@0+ (1,0) [0|1] "B"  HVESP01
 SG_ HVESP01_Des_stcu_fault_reset_6 : 4|1@0+ (1,0) [0|1] "B"  HVESP01
 SG_ HVESP01_Des_fccu_ftr_reset_6 : 5|1@0+ (1,0) [0|1] "B"  HVESP01
 SG_ HVESP01_Des_software_dest_r_0004 : 6|1@0+ (1,0) [0|1] "B"  HVESP01
 SG_ HVESP01_Des_power_on_reset_6 : 7|1@0+ (1,0) [0|1] "B"  HVESP01
 SG_ HVESP01_Fes_VOR_fn_reset_6 : 8|1@0+ (1,0) [0|1] "B"  HVESP01
 SG_ HVESP01_Fes_TS_fn_reset_6 : 9|1@0+ (1,0) [0|1] "B"  HVESP01
 SG_ HVESP01_Fes_jtag_fn_reset_6 : 10|1@0+ (1,0) [0|1] "B"  HVESP01
 SG_ HVESP01_Fes_fccu_soft_reset_6 : 11|1@0+ (1,0) [0|1] "B"  HVESP01
 SG_ HVESP01_Fes_fccu_hard_reset_6 : 12|1@0+ (1,0) [0|1] "B"  HVESP01
 SG_ HVESP01_Fes_external_reset_6 : 13|1@0+ (1,0) [0|1] "B"  HVESP01
 SG_ HVESP01_Fes_software_fn_reset_6 : 14|1@0+ (1,0) [0|1] "B"  HVESP01
 SG_ HVESP01_Fes_self_test_done__0004 : 15|1@0+ (1,0) [0|1] "B"  HVESP01

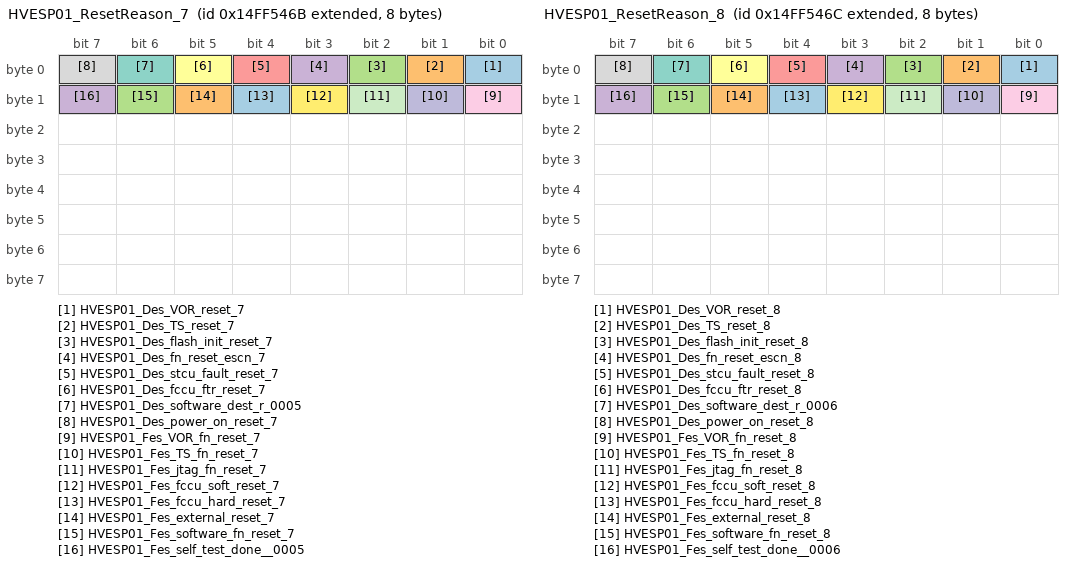
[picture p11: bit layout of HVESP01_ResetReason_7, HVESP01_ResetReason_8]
BO_ 2499761259 HVESP01_ResetReason_7: 8 HVESP01
 SG_ HVESP01_Des_VOR_reset_7 : 0|1@0+ (1,0) [0|1] "B"  HVESP01
 SG_ HVESP01_Des_TS_reset_7 : 1|1@0+ (1,0) [0|1] "B"  HVESP01
 SG_ HVESP01_Des_flash_init_reset_7 : 2|1@0+ (1,0) [0|1] "B"  HVESP01
 SG_ HVESP01_Des_fn_reset_escn_7 : 3|1@0+ (1,0) [0|1] "B"  HVESP01
 SG_ HVESP01_Des_stcu_fault_reset_7 : 4|1@0+ (1,0) [0|1] "B"  HVESP01
 SG_ HVESP01_Des_fccu_ftr_reset_7 : 5|1@0+ (1,0) [0|1] "B"  HVESP01
 SG_ HVESP01_Des_software_dest_r_0005 : 6|1@0+ (1,0) [0|1] "B"  HVESP01
 SG_ HVESP01_Des_power_on_reset_7 : 7|1@0+ (1,0) [0|1] "B"  HVESP01
 SG_ HVESP01_Fes_VOR_fn_reset_7 : 8|1@0+ (1,0) [0|1] "B"  HVESP01
 SG_ HVESP01_Fes_TS_fn_reset_7 : 9|1@0+ (1,0) [0|1] "B"  HVESP01
 SG_ HVESP01_Fes_jtag_fn_reset_7 : 10|1@0+ (1,0) [0|1] "B"  HVESP01
 SG_ HVESP01_Fes_fccu_soft_reset_7 : 11|1@0+ (1,0) [0|1] "B"  HVESP01
 SG_ HVESP01_Fes_fccu_hard_reset_7 : 12|1@0+ (1,0) [0|1] "B"  HVESP01
 SG_ HVESP01_Fes_external_reset_7 : 13|1@0+ (1,0) [0|1] "B"  HVESP01
 SG_ HVESP01_Fes_software_fn_reset_7 : 14|1@0+ (1,0) [0|1] "B"  HVESP01
 SG_ HVESP01_Fes_self_test_done__0005 : 15|1@0+ (1,0) [0|1] "B"  HVESP01

BO_ 2499761260 HVESP01_ResetReason_8: 8 HVESP01
 SG_ HVESP01_Des_VOR_reset_8 : 0|1@0+ (1,0) [0|1] "B"  HVESP01
 SG_ HVESP01_Des_TS_reset_8 : 1|1@0+ (1,0) [0|1] "B"  HVESP01
 SG_ HVESP01_Des_flash_init_reset_8 : 2|1@0+ (1,0) [0|1] "B"  HVESP01
 SG_ HVESP01_Des_fn_reset_escn_8 : 3|1@0+ (1,0) [0|1] "B"  HVESP01
 SG_ HVESP01_Des_stcu_fault_reset_8 : 4|1@0+ (1,0) [0|1] "B"  HVESP01
 SG_ HVESP01_Des_fccu_ftr_reset_8 : 5|1@0+ (1,0) [0|1] "B"  HVESP01
 SG_ HVESP01_Des_software_dest_r_0006 : 6|1@0+ (1,0) [0|1] "B"  HVESP01
 SG_ HVESP01_Des_power_on_reset_8 : 7|1@0+ (1,0) [0|1] "B"  HVESP01
 SG_ HVESP01_Fes_VOR_fn_reset_8 : 8|1@0+ (1,0) [0|1] "B"  HVESP01
 SG_ HVESP01_Fes_TS_fn_reset_8 : 9|1@0+ (1,0) [0|1] "B"  HVESP01
 SG_ HVESP01_Fes_jtag_fn_reset_8 : 10|1@0+ (1,0) [0|1] "B"  HVESP01
 SG_ HVESP01_Fes_fccu_soft_reset_8 : 11|1@0+ (1,0) [0|1] "B"  HVESP01
 SG_ HVESP01_Fes_fccu_hard_reset_8 : 12|1@0+ (1,0) [0|1] "B"  HVESP01
 SG_ HVESP01_Fes_external_reset_8 : 13|1@0+ (1,0) [0|1] "B"  HVESP01
 SG_ HVESP01_Fes_software_fn_reset_8 : 14|1@0+ (1,0) [0|1] "B"  HVESP01
 SG_ HVESP01_Fes_self_test_done__0006 : 15|1@0+ (1,0) [0|1] "B"  HVESP01

BO_ 2499795813 HVESP01_FC_Voltage_1: 6 HVESP01
 SG_ HVESP01_VFC_1 : 32|16@1- (0.02,0) [-655.36|655.34] "v"  HVESP01
 SG_ HVESP01_diagVFCPos_1 : 16|16@1- (0.02,0) [-655.36|655.34] "v"  HVESP01
 SG_ HVESP01_diagVFCNeg_1 : 0|16@1- (0.02,0) [-655.36|655.34] "v"  HVESP01

BO_ 2499795814 HVESP01_FC_Voltage_2: 6 HVESP01
 SG_ HVESP01_VFC_2 : 32|16@1- (0.02,0) [-655.36|655.34] "v"  HVESP01
 SG_ HVESP01_diagVFCPos_2 : 16|16@1- (0.02,0) [-655.36|655.34] "v"  HVESP01
 SG_ HVESP01_diagVFCNeg_2 : 0|16@1- (0.02,0) [-655.36|655.34] "v"  HVESP01

BO_ 2499795815 HVESP01_FC_Voltage_3: 6 HVESP01
 SG_ HVESP01_VFC_3 : 32|16@1- (0.02,0) [-655.36|655.34] "v"  HVESP01
 SG_ HVESP01_diagVFCPos_3 : 16|16@1- (0.02,0) [-655.36|655.34] "v"  HVESP01
 SG_ HVESP01_diagVFCNeg_3 : 0|16@1- (0.02,0) [-655.36|655.34] "v"  HVESP01

BO_ 2499795816 HVESP01_FC_Voltage_4: 6 HVESP01
 SG_ HVESP01_VFC_4 : 32|16@1- (0.02,0) [-655.36|655.34] "v"  HVESP01
 SG_ HVESP01_diagVFCPos_4 : 16|16@1- (0.02,0) [-655.36|655.34] "v"  HVESP01
 SG_ HVESP01_diagVFCNeg_4 : 0|16@1- (0.02,0) [-655.36|655.34] "v"  HVESP01

BO_ 2499795817 HVESP01_FC_Voltage_5: 6 HVESP01
 SG_ HVESP01_VFC_5 : 32|16@1- (0.02,0) [-655.36|655.34] "v"  HVESP01
 SG_ HVESP01_diagVFCPos_5 : 16|16@1- (0.02,0) [-655.36|655.34] "v"  HVESP01
 SG_ HVESP01_diagVFCNeg_5 : 0|16@1- (0.02,0) [-655.36|655.34] "v"  HVESP01

BO_ 2499795818 HVESP01_FC_Voltage_6: 6 HVESP01
 SG_ HVESP01_VFC_6 : 32|16@1- (0.02,0) [-655.36|655.34] "v"  HVESP01
 SG_ HVESP01_diagVFCPos_6 : 16|16@1- (0.02,0) [-655.36|655.34] "v"  HVESP01
 SG_ HVESP01_diagVFCNeg_6 : 0|16@1- (0.02,0) [-655.36|655.34] "v"  HVESP01

BO_ 2499795819 HVESP01_FC_Voltage_7: 6 HVESP01
 SG_ HVESP01_VFC_7 : 32|16@1- (0.02,0) [-655.36|655.34] "v"  HVESP01
 SG_ HVESP01_diagVFCPos_7 : 16|16@1- (0.02,0) [-655.36|655.34] "v"  HVESP01
 SG_ HVESP01_diagVFCNeg_7 : 0|16@1- (0.02,0) [-655.36|655.34] "v"  HVESP01

BO_ 2499795820 HVESP01_FC_Voltage_8: 6 HVESP01
 SG_ HVESP01_VFC_8 : 32|16@1- (0.02,0) [-655.36|655.34] "v"  HVESP01
 SG_ HVESP01_diagVFCPos_8 : 16|16@1- (0.02,0) [-655.36|655.34] "v"  HVESP01
 SG_ HVESP01_diagVFCNeg_8 : 0|16@1- (0.02,0) [-655.36|655.34] "v"  HVESP01

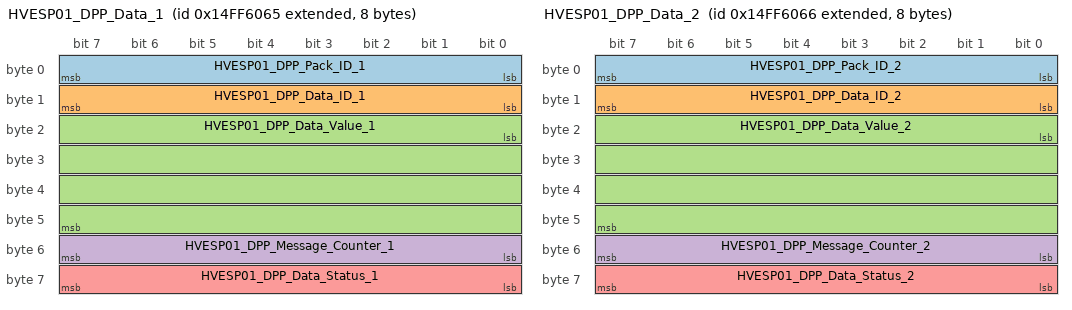
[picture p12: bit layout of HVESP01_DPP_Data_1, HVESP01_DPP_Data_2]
BO_ 2499764325 HVESP01_DPP_Data_1: 8 HVESP01
 SG_ HVESP01_DPP_Pack_ID_1 : 0|8@1+ (1,0) [1|8] ""  HVESS
 SG_ HVESP01_DPP_Data_ID_1 : 8|8@1+ (1,0) [1|20] ""  HVESS
 SG_ HVESP01_DPP_Data_Value_1 : 16|32@1+ (1,0) [0|4294967295] "Depends on Data_ID"  HVESS
 SG_ HVESP01_DPP_Message_Counter_1 : 48|8@1+ (1,0) [0|255] ""  HVESS
 SG_ HVESP01_DPP_Data_Status_1 : 56|8@1+ (1,0) [0|1] ""  HVESS

BO_ 2499764581 HVESP01_DPP_Identifier_1: 8 HVESP01
 SG_ HVESP01_DPP_Pack_ID_1 : 0|8@1+ (1,0) [1|8] ""  HVESS
 SG_ HVESP01_Segment_ID_1 : 8|8@1+ (1,0) [0|255] ""  HVESS
 SG_ HVESP01_DPP_Info_1 : 16|48@1+ (1,0) [0|281474976710655] ""  HVESS

BO_ 2499764326 HVESP01_DPP_Data_2: 8 HVESP01
 SG_ HVESP01_DPP_Pack_ID_2 : 0|8@1+ (1,0) [1|8] ""  HVESS
 SG_ HVESP01_DPP_Data_ID_2 : 8|8@1+ (1,0) [1|20] ""  HVESS
 SG_ HVESP01_DPP_Data_Value_2 : 16|32@1+ (1,0) [0|4294967295] "Depends on Data_ID"  HVESS
 SG_ HVESP01_DPP_Message_Counter_2 : 48|8@1+ (1,0) [0|255] ""  HVESS
 SG_ HVESP01_DPP_Data_Status_2 : 56|8@1+ (1,0) [0|1] ""  HVESS

BO_ 2499764582 HVESP01_DPP_Identifier_2: 8 HVESP01
 SG_ HVESP01_DPP_Pack_ID_2 : 0|8@1+ (1,0) [1|8] ""  HVESS
 SG_ HVESP01_Segment_ID_2 : 8|8@1+ (1,0) [0|255] ""  HVESS
 SG_ HVESP01_DPP_Info_2 : 16|48@1+ (1,0) [0|281474976710655] ""  HVESS

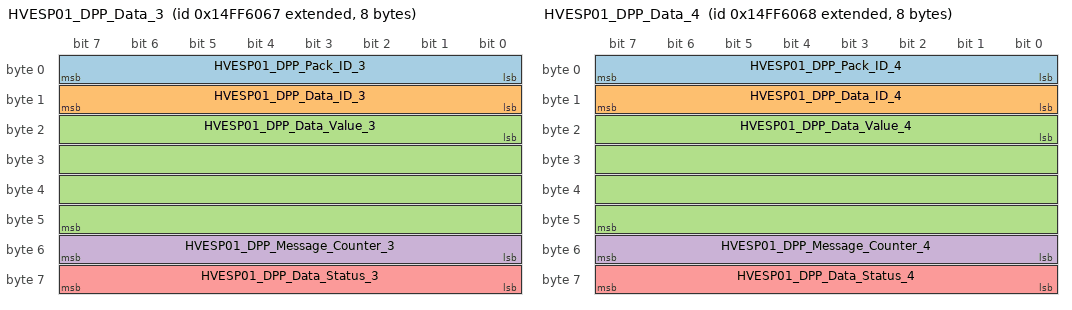
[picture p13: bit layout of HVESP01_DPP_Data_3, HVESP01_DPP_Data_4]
BO_ 2499764327 HVESP01_DPP_Data_3: 8 HVESP01
 SG_ HVESP01_DPP_Pack_ID_3 : 0|8@1+ (1,0) [1|8] ""  HVESS
 SG_ HVESP01_DPP_Data_ID_3 : 8|8@1+ (1,0) [1|20] ""  HVESS
 SG_ HVESP01_DPP_Data_Value_3 : 16|32@1+ (1,0) [0|4294967295] "Depends on Data_ID"  HVESS
 SG_ HVESP01_DPP_Message_Counter_3 : 48|8@1+ (1,0) [0|255] ""  HVESS
 SG_ HVESP01_DPP_Data_Status_3 : 56|8@1+ (1,0) [0|1] ""  HVESS

BO_ 2499764583 HVESP01_DPP_Identifier_3: 8 HVESP01
 SG_ HVESP01_DPP_Pack_ID_3 : 0|8@1+ (1,0) [1|8] ""  HVESS
 SG_ HVESP01_Segment_ID_3 : 8|8@1+ (1,0) [0|255] ""  HVESS
 SG_ HVESP01_DPP_Info_3 : 16|48@1+ (1,0) [0|281474976710655] ""  HVESS

BO_ 2499764328 HVESP01_DPP_Data_4: 8 HVESP01
 SG_ HVESP01_DPP_Pack_ID_4 : 0|8@1+ (1,0) [1|8] ""  HVESS
 SG_ HVESP01_DPP_Data_ID_4 : 8|8@1+ (1,0) [1|20] ""  HVESS
 SG_ HVESP01_DPP_Data_Value_4 : 16|32@1+ (1,0) [0|4294967295] "Depends on Data_ID"  HVESS
 SG_ HVESP01_DPP_Message_Counter_4 : 48|8@1+ (1,0) [0|255] ""  HVESS
 SG_ HVESP01_DPP_Data_Status_4 : 56|8@1+ (1,0) [0|1] ""  HVESS

BO_ 2499764584 HVESP01_DPP_Identifier_4: 8 HVESP01
 SG_ HVESP01_DPP_Pack_ID_4 : 0|8@1+ (1,0) [1|8] ""  HVESS
 SG_ HVESP01_Segment_ID_4 : 8|8@1+ (1,0) [0|255] ""  HVESS
 SG_ HVESP01_DPP_Info_4 : 16|48@1+ (1,0) [0|281474976710655] ""  HVESS

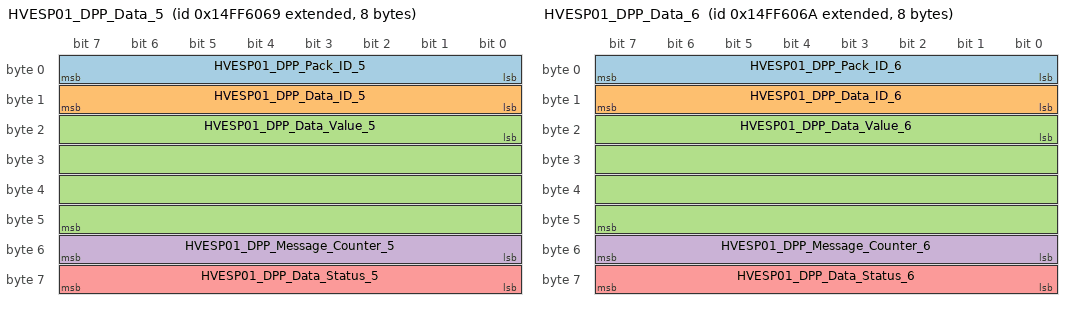
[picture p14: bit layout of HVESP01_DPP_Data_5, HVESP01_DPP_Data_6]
BO_ 2499764329 HVESP01_DPP_Data_5: 8 HVESP01
 SG_ HVESP01_DPP_Pack_ID_5 : 0|8@1+ (1,0) [1|8] ""  HVESS
 SG_ HVESP01_DPP_Data_ID_5 : 8|8@1+ (1,0) [1|20] ""  HVESS
 SG_ HVESP01_DPP_Data_Value_5 : 16|32@1+ (1,0) [0|4294967295] "Depends on Data_ID"  HVESS
 SG_ HVESP01_DPP_Message_Counter_5 : 48|8@1+ (1,0) [0|255] ""  HVESS
 SG_ HVESP01_DPP_Data_Status_5 : 56|8@1+ (1,0) [0|1] ""  HVESS

BO_ 2499764330 HVESP01_DPP_Data_6: 8 HVESP01
 SG_ HVESP01_DPP_Pack_ID_6 : 0|8@1+ (1,0) [1|8] ""  HVESS
 SG_ HVESP01_DPP_Data_ID_6 : 8|8@1+ (1,0) [1|20] ""  HVESS
 SG_ HVESP01_DPP_Data_Value_6 : 16|32@1+ (1,0) [0|4294967295] "Depends on Data_ID"  HVESS
 SG_ HVESP01_DPP_Message_Counter_6 : 48|8@1+ (1,0) [0|255] ""  HVESS
 SG_ HVESP01_DPP_Data_Status_6 : 56|8@1+ (1,0) [0|1] ""  HVESS

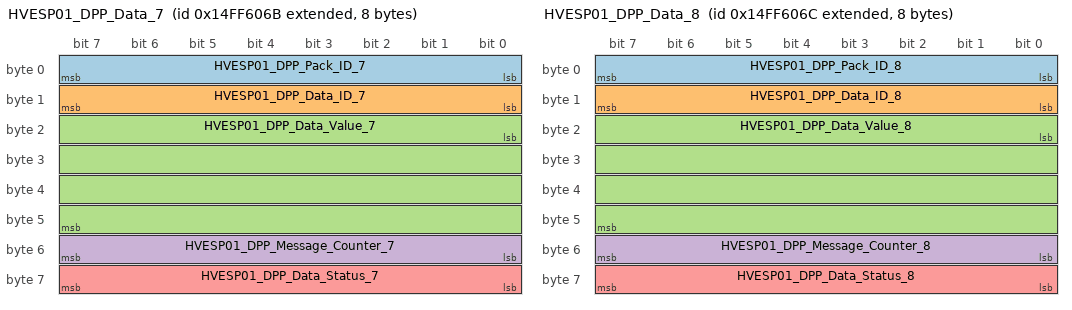
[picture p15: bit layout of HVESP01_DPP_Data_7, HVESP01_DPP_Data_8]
BO_ 2499764331 HVESP01_DPP_Data_7: 8 HVESP01
 SG_ HVESP01_DPP_Pack_ID_7 : 0|8@1+ (1,0) [1|8] ""  HVESS
 SG_ HVESP01_DPP_Data_ID_7 : 8|8@1+ (1,0) [1|20] ""  HVESS
 SG_ HVESP01_DPP_Data_Value_7 : 16|32@1+ (1,0) [0|4294967295] "Depends on Data_ID"  HVESS
 SG_ HVESP01_DPP_Message_Counter_7 : 48|8@1+ (1,0) [0|255] ""  HVESS
 SG_ HVESP01_DPP_Data_Status_7 : 56|8@1+ (1,0) [0|1] ""  HVESS

BO_ 2499764332 HVESP01_DPP_Data_8: 8 HVESP01
 SG_ HVESP01_DPP_Pack_ID_8 : 0|8@1+ (1,0) [1|8] ""  HVESS
 SG_ HVESP01_DPP_Data_ID_8 : 8|8@1+ (1,0) [1|20] ""  HVESS
 SG_ HVESP01_DPP_Data_Value_8 : 16|32@1+ (1,0) [0|4294967295] "Depends on Data_ID"  HVESS
 SG_ HVESP01_DPP_Message_Counter_8 : 48|8@1+ (1,0) [0|255] ""  HVESS
 SG_ HVESP01_DPP_Data_Status_8 : 56|8@1+ (1,0) [0|1] ""  HVESS

BO_ 2499764585 HVESP01_DPP_Identifier_5: 8 HVESP01
 SG_ HVESP01_DPP_Pack_ID_5 : 0|8@1+ (1,0) [1|8] ""  HVESS
 SG_ HVESP01_Segment_ID_5 : 8|8@1+ (1,0) [0|255] ""  HVESS
 SG_ HVESP01_DPP_Info_5 : 16|48@1+ (1,0) [0|281474976710655] ""  HVESS

BO_ 2499764586 HVESP01_DPP_Identifier_6: 8 HVESP01
 SG_ HVESP01_DPP_Pack_ID_6 : 0|8@1+ (1,0) [1|8] ""  HVESS
 SG_ HVESP01_Segment_ID_6 : 8|8@1+ (1,0) [0|255] ""  HVESS
 SG_ HVESP01_DPP_Info_6 : 16|48@1+ (1,0) [0|281474976710655] ""  HVESS

BO_ 2499764587 HVESP01_DPP_Identifier_7: 8 HVESP01
 SG_ HVESP01_DPP_Pack_ID_7 : 0|8@1+ (1,0) [1|8] ""  HVESS
 SG_ HVESP01_Segment_ID_7 : 8|8@1+ (1,0) [0|255] ""  HVESS
 SG_ HVESP01_DPP_Info_7 : 16|48@1+ (1,0) [0|281474976710655] ""  HVESS

BO_ 2499764588 HVESP01_DPP_Identifier_8: 8 HVESP01
 SG_ HVESP01_DPP_Pack_ID_8 : 0|8@1+ (1,0) [1|8] ""  HVESS
 SG_ HVESP01_Segment_ID_8 : 8|8@1+ (1,0) [0|255] ""  HVESS
 SG_ HVESP01_DPP_Info_8 : 16|48@1+ (1,0) [0|281474976710655] ""  HVESS

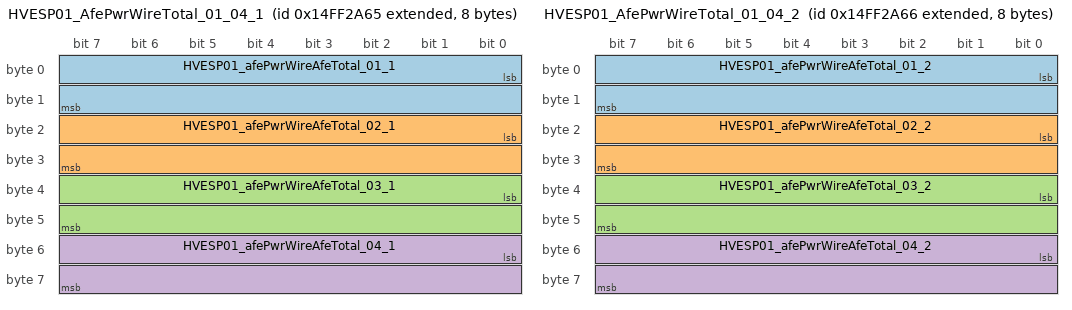
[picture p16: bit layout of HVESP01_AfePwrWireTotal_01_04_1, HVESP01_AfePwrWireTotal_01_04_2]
BO_ 2499750501 HVESP01_AfePwrWireTotal_01_04_1: 8 HVESP01
 SG_ HVESP01_afePwrWireAfeTotal_01_1 : 0|16@1+ (0.01,0) [0|655.34] "V"  HVESP01
 SG_ HVESP01_afePwrWireAfeTotal_02_1 : 16|16@1+ (0.01,0) [0|655.34] "V"  HVESP01
 SG_ HVESP01_afePwrWireAfeTotal_03_1 : 32|16@1+ (0.01,0) [0|655.34] "V"  HVESP01
 SG_ HVESP01_afePwrWireAfeTotal_04_1 : 48|16@1+ (0.01,0) [0|655.34] "V"  HVESP01

BO_ 2499750502 HVESP01_AfePwrWireTotal_01_04_2: 8 HVESP01
 SG_ HVESP01_afePwrWireAfeTotal_01_2 : 0|16@1+ (0.01,0) [0|655.34] "V"  HVESP01
 SG_ HVESP01_afePwrWireAfeTotal_02_2 : 16|16@1+ (0.01,0) [0|655.34] "V"  HVESP01
 SG_ HVESP01_afePwrWireAfeTotal_03_2 : 32|16@1+ (0.01,0) [0|655.34] "V"  HVESP01
 SG_ HVESP01_afePwrWireAfeTotal_04_2 : 48|16@1+ (0.01,0) [0|655.34] "V"  HVESP01

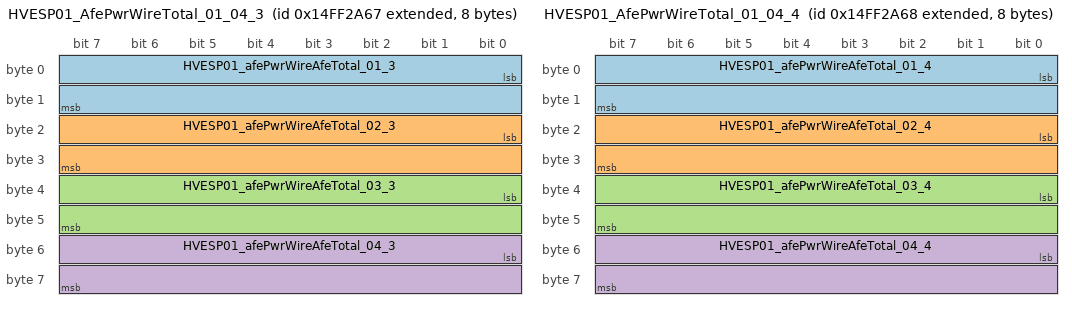
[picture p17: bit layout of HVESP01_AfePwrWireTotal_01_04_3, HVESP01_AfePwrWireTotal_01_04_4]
BO_ 2499750503 HVESP01_AfePwrWireTotal_01_04_3: 8 HVESP01
 SG_ HVESP01_afePwrWireAfeTotal_01_3 : 0|16@1+ (0.01,0) [0|655.34] "V"  HVESP01
 SG_ HVESP01_afePwrWireAfeTotal_02_3 : 16|16@1+ (0.01,0) [0|655.34] "V"  HVESP01
 SG_ HVESP01_afePwrWireAfeTotal_03_3 : 32|16@1+ (0.01,0) [0|655.34] "V"  HVESP01
 SG_ HVESP01_afePwrWireAfeTotal_04_3 : 48|16@1+ (0.01,0) [0|655.34] "V"  HVESP01

BO_ 2499750504 HVESP01_AfePwrWireTotal_01_04_4: 8 HVESP01
 SG_ HVESP01_afePwrWireAfeTotal_01_4 : 0|16@1+ (0.01,0) [0|655.34] "V"  HVESP01
 SG_ HVESP01_afePwrWireAfeTotal_02_4 : 16|16@1+ (0.01,0) [0|655.34] "V"  HVESP01
 SG_ HVESP01_afePwrWireAfeTotal_03_4 : 32|16@1+ (0.01,0) [0|655.34] "V"  HVESP01
 SG_ HVESP01_afePwrWireAfeTotal_04_4 : 48|16@1+ (0.01,0) [0|655.34] "V"  HVESP01

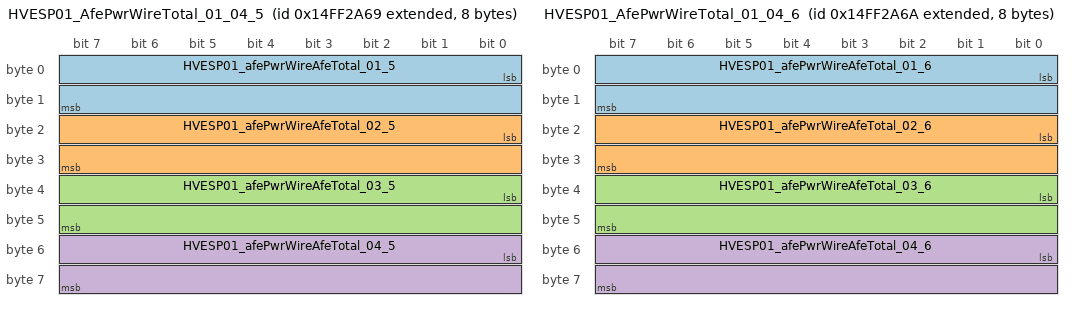
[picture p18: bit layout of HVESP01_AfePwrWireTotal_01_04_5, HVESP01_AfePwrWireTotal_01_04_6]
BO_ 2499750505 HVESP01_AfePwrWireTotal_01_04_5: 8 HVESP01
 SG_ HVESP01_afePwrWireAfeTotal_01_5 : 0|16@1+ (0.01,0) [0|655.34] "V"  HVESP01
 SG_ HVESP01_afePwrWireAfeTotal_02_5 : 16|16@1+ (0.01,0) [0|655.34] "V"  HVESP01
 SG_ HVESP01_afePwrWireAfeTotal_03_5 : 32|16@1+ (0.01,0) [0|655.34] "V"  HVESP01
 SG_ HVESP01_afePwrWireAfeTotal_04_5 : 48|16@1+ (0.01,0) [0|655.34] "V"  HVESP01

BO_ 2499750506 HVESP01_AfePwrWireTotal_01_04_6: 8 HVESP01
 SG_ HVESP01_afePwrWireAfeTotal_01_6 : 0|16@1+ (0.01,0) [0|655.34] "V"  HVESP01
 SG_ HVESP01_afePwrWireAfeTotal_02_6 : 16|16@1+ (0.01,0) [0|655.34] "V"  HVESP01
 SG_ HVESP01_afePwrWireAfeTotal_03_6 : 32|16@1+ (0.01,0) [0|655.34] "V"  HVESP01
 SG_ HVESP01_afePwrWireAfeTotal_04_6 : 48|16@1+ (0.01,0) [0|655.34] "V"  HVESP01

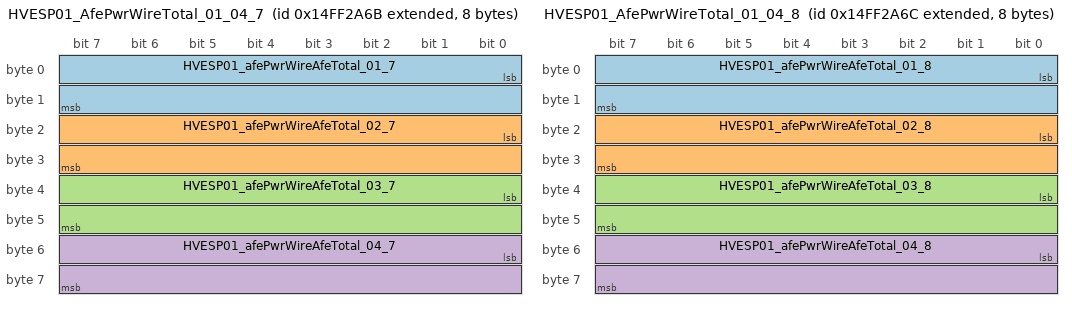
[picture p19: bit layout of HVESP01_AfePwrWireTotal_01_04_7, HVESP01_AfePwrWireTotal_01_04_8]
BO_ 2499750507 HVESP01_AfePwrWireTotal_01_04_7: 8 HVESP01
 SG_ HVESP01_afePwrWireAfeTotal_01_7 : 0|16@1+ (0.01,0) [0|655.34] "V"  HVESP01
 SG_ HVESP01_afePwrWireAfeTotal_02_7 : 16|16@1+ (0.01,0) [0|655.34] "V"  HVESP01
 SG_ HVESP01_afePwrWireAfeTotal_03_7 : 32|16@1+ (0.01,0) [0|655.34] "V"  HVESP01
 SG_ HVESP01_afePwrWireAfeTotal_04_7 : 48|16@1+ (0.01,0) [0|655.34] "V"  HVESP01

BO_ 2499750508 HVESP01_AfePwrWireTotal_01_04_8: 8 HVESP01
 SG_ HVESP01_afePwrWireAfeTotal_01_8 : 0|16@1+ (0.01,0) [0|655.34] "V"  HVESP01
 SG_ HVESP01_afePwrWireAfeTotal_02_8 : 16|16@1+ (0.01,0) [0|655.34] "V"  HVESP01
 SG_ HVESP01_afePwrWireAfeTotal_03_8 : 32|16@1+ (0.01,0) [0|655.34] "V"  HVESP01
 SG_ HVESP01_afePwrWireAfeTotal_04_8 : 48|16@1+ (0.01,0) [0|655.34] "V"  HVESP01

BO_ 2499750757 HVESP01_AfePwrWireTotal_05_08_1: 8 HVESP01
 SG_ HVESP01_afePwrWireAfeTotal_05_1 : 0|16@1+ (0.01,0) [0|655.34] "V"  HVESP01
 SG_ HVESP01_afePwrWireAfeTotal_06_1 : 16|16@1+ (0.01,0) [0|655.34] "V"  HVESP01
 SG_ HVESP01_afePwrWireAfeTotal_07_1 : 32|16@1+ (0.01,0) [0|655.34] "V"  HVESP01
 SG_ HVESP01_afePwrWireAfeTotal_08_1 : 48|16@1+ (0.01,0) [0|655.34] "V"  HVESP01

BO_ 2499750758 HVESP01_AfePwrWireTotal_05_08_2: 8 HVESP01
 SG_ HVESP01_afePwrWireAfeTotal_05_2 : 0|16@1+ (0.01,0) [0|655.34] "V"  HVESP01
 SG_ HVESP01_afePwrWireAfeTotal_06_2 : 16|16@1+ (0.01,0) [0|655.34] "V"  HVESP01
 SG_ HVESP01_afePwrWireAfeTotal_07_2 : 32|16@1+ (0.01,0) [0|655.34] "V"  HVESP01
 SG_ HVESP01_afePwrWireAfeTotal_08_2 : 48|16@1+ (0.01,0) [0|655.34] "V"  HVESP01

BO_ 2499750759 HVESP01_AfePwrWireTotal_05_08_3: 8 HVESP01
 SG_ HVESP01_afePwrWireAfeTotal_05_3 : 0|16@1+ (0.01,0) [0|655.34] "V"  HVESP01
 SG_ HVESP01_afePwrWireAfeTotal_06_3 : 16|16@1+ (0.01,0) [0|655.34] "V"  HVESP01
 SG_ HVESP01_afePwrWireAfeTotal_07_3 : 32|16@1+ (0.01,0) [0|655.34] "V"  HVESP01
 SG_ HVESP01_afePwrWireAfeTotal_08_3 : 48|16@1+ (0.01,0) [0|655.34] "V"  HVESP01

BO_ 2499750760 HVESP01_AfePwrWireTotal_05_08_4: 8 HVESP01
 SG_ HVESP01_afePwrWireAfeTotal_05_4 : 0|16@1+ (0.01,0) [0|655.34] "V"  HVESP01
 SG_ HVESP01_afePwrWireAfeTotal_06_4 : 16|16@1+ (0.01,0) [0|655.34] "V"  HVESP01
 SG_ HVESP01_afePwrWireAfeTotal_07_4 : 32|16@1+ (0.01,0) [0|655.34] "V"  HVESP01
 SG_ HVESP01_afePwrWireAfeTotal_08_4 : 48|16@1+ (0.01,0) [0|655.34] "V"  HVESP01

BO_ 2499750761 HVESP01_AfePwrWireTotal_05_08_5: 8 HVESP01
 SG_ HVESP01_afePwrWireAfeTotal_05_5 : 0|16@1+ (0.01,0) [0|655.34] "V"  HVESP01
 SG_ HVESP01_afePwrWireAfeTotal_06_5 : 16|16@1+ (0.01,0) [0|655.34] "V"  HVESP01
 SG_ HVESP01_afePwrWireAfeTotal_07_5 : 32|16@1+ (0.01,0) [0|655.34] "V"  HVESP01
 SG_ HVESP01_afePwrWireAfeTotal_08_5 : 48|16@1+ (0.01,0) [0|655.34] "V"  HVESP01

BO_ 2499750762 HVESP01_AfePwrWireTotal_05_08_6: 8 HVESP01
 SG_ HVESP01_afePwrWireAfeTotal_05_6 : 0|16@1+ (0.01,0) [0|655.34] "V"  HVESP01
 SG_ HVESP01_afePwrWireAfeTotal_06_6 : 16|16@1+ (0.01,0) [0|655.34] "V"  HVESP01
 SG_ HVESP01_afePwrWireAfeTotal_07_6 : 32|16@1+ (0.01,0) [0|655.34] "V"  HVESP01
 SG_ HVESP01_afePwrWireAfeTotal_08_6 : 48|16@1+ (0.01,0) [0|655.34] "V"  HVESP01

BO_ 2499750763 HVESP01_AfePwrWireTotal_05_08_7: 8 HVESP01
 SG_ HVESP01_afePwrWireAfeTotal_05_7 : 0|16@1+ (0.01,0) [0|655.34] "V"  HVESP01
 SG_ HVESP01_afePwrWireAfeTotal_06_7 : 16|16@1+ (0.01,0) [0|655.34] "V"  HVESP01
 SG_ HVESP01_afePwrWireAfeTotal_07_7 : 32|16@1+ (0.01,0) [0|655.34] "V"  HVESP01
 SG_ HVESP01_afePwrWireAfeTotal_08_7 : 48|16@1+ (0.01,0) [0|655.34] "V"  HVESP01

BO_ 2499750764 HVESP01_AfePwrWireTotal_05_08_8: 8 HVESP01
 SG_ HVESP01_afePwrWireAfeTotal_05_8 : 0|16@1+ (0.01,0) [0|655.34] "V"  HVESP01
 SG_ HVESP01_afePwrWireAfeTotal_06_8 : 16|16@1+ (0.01,0) [0|655.34] "V"  HVESP01
 SG_ HVESP01_afePwrWireAfeTotal_07_8 : 32|16@1+ (0.01,0) [0|655.34] "V"  HVESP01
 SG_ HVESP01_afePwrWireAfeTotal_08_8 : 48|16@1+ (0.01,0) [0|655.34] "V"  HVESP01

BO_ 2499751013 HVESP01_AfePwrWireTotal_09_12_1: 8 HVESP01
 SG_ HVESP01_afePwrWireAfeTotal_09_1 : 0|16@1+ (0.01,0) [0|655.34] "V"  HVESP01
 SG_ HVESP01_afePwrWireAfeTotal_10_1 : 16|16@1+ (0.01,0) [0|655.34] "V"  HVESP01
 SG_ HVESP01_afePwrWireAfeTotal_11_1 : 32|16@1+ (0.01,0) [0|655.34] "V"  HVESP01
 SG_ HVESP01_afePwrWireAfeTotal_12_1 : 48|16@1+ (0.01,0) [0|655.34] "V"  HVESP01

BO_ 2499751014 HVESP01_AfePwrWireTotal_09_12_2: 8 HVESP01
 SG_ HVESP01_afePwrWireAfeTotal_09_2 : 0|16@1+ (0.01,0) [0|655.34] "V"  HVESP01
 SG_ HVESP01_afePwrWireAfeTotal_10_2 : 16|16@1+ (0.01,0) [0|655.34] "V"  HVESP01
 SG_ HVESP01_afePwrWireAfeTotal_11_2 : 32|16@1+ (0.01,0) [0|655.34] "V"  HVESP01
 SG_ HVESP01_afePwrWireAfeTotal_12_2 : 48|16@1+ (0.01,0) [0|655.34] "V"  HVESP01

BO_ 2499751015 HVESP01_AfePwrWireTotal_09_12_3: 8 HVESP01
 SG_ HVESP01_afePwrWireAfeTotal_09_3 : 0|16@1+ (0.01,0) [0|655.34] "V"  HVESP01
 SG_ HVESP01_afePwrWireAfeTotal_10_3 : 16|16@1+ (0.01,0) [0|655.34] "V"  HVESP01
 SG_ HVESP01_afePwrWireAfeTotal_11_3 : 32|16@1+ (0.01,0) [0|655.34] "V"  HVESP01
 SG_ HVESP01_afePwrWireAfeTotal_12_3 : 48|16@1+ (0.01,0) [0|655.34] "V"  HVESP01

BO_ 2499751016 HVESP01_AfePwrWireTotal_09_12_4: 8 HVESP01
 SG_ HVESP01_afePwrWireAfeTotal_09_4 : 0|16@1+ (0.01,0) [0|655.34] "V"  HVESP01
 SG_ HVESP01_afePwrWireAfeTotal_10_4 : 16|16@1+ (0.01,0) [0|655.34] "V"  HVESP01
 SG_ HVESP01_afePwrWireAfeTotal_11_4 : 32|16@1+ (0.01,0) [0|655.34] "V"  HVESP01
 SG_ HVESP01_afePwrWireAfeTotal_12_4 : 48|16@1+ (0.01,0) [0|655.34] "V"  HVESP01

BO_ 2499751017 HVESP01_AfePwrWireTotal_09_12_5: 8 HVESP01
 SG_ HVESP01_afePwrWireAfeTotal_09_5 : 0|16@1+ (0.01,0) [0|655.34] "V"  HVESP01
 SG_ HVESP01_afePwrWireAfeTotal_10_5 : 16|16@1+ (0.01,0) [0|655.34] "V"  HVESP01
 SG_ HVESP01_afePwrWireAfeTotal_11_5 : 32|16@1+ (0.01,0) [0|655.34] "V"  HVESP01
 SG_ HVESP01_afePwrWireAfeTotal_12_5 : 48|16@1+ (0.01,0) [0|655.34] "V"  HVESP01

BO_ 2499751018 HVESP01_AfePwrWireTotal_09_12_6: 8 HVESP01
 SG_ HVESP01_afePwrWireAfeTotal_09_6 : 0|16@1+ (0.01,0) [0|655.34] "V"  HVESP01
 SG_ HVESP01_afePwrWireAfeTotal_10_6 : 16|16@1+ (0.01,0) [0|655.34] "V"  HVESP01
 SG_ HVESP01_afePwrWireAfeTotal_11_6 : 32|16@1+ (0.01,0) [0|655.34] "V"  HVESP01
 SG_ HVESP01_afePwrWireAfeTotal_12_6 : 48|16@1+ (0.01,0) [0|655.34] "V"  HVESP01

BO_ 2499751019 HVESP01_AfePwrWireTotal_09_12_7: 8 HVESP01
 SG_ HVESP01_afePwrWireAfeTotal_09_7 : 0|16@1+ (0.01,0) [0|655.34] "V"  HVESP01
 SG_ HVESP01_afePwrWireAfeTotal_10_7 : 16|16@1+ (0.01,0) [0|655.34] "V"  HVESP01
 SG_ HVESP01_afePwrWireAfeTotal_11_7 : 32|16@1+ (0.01,0) [0|655.34] "V"  HVESP01
 SG_ HVESP01_afePwrWireAfeTotal_12_7 : 48|16@1+ (0.01,0) [0|655.34] "V"  HVESP01

BO_ 2499751020 HVESP01_AfePwrWireTotal_09_12_8: 8 HVESP01
 SG_ HVESP01_afePwrWireAfeTotal_09_8 : 0|16@1+ (0.01,0) [0|655.34] "V"  HVESP01
 SG_ HVESP01_afePwrWireAfeTotal_10_8 : 16|16@1+ (0.01,0) [0|655.34] "V"  HVESP01
 SG_ HVESP01_afePwrWireAfeTotal_11_8 : 32|16@1+ (0.01,0) [0|655.34] "V"  HVESP01
 SG_ HVESP01_afePwrWireAfeTotal_12_8 : 48|16@1+ (0.01,0) [0|655.34] "V"  HVESP01

BO_ 2499751269 HVESP01_AfePwrWireTotal_13_16_1: 8 HVESP01
 SG_ HVESP01_afePwrWireAfeTotal_13_1 : 0|16@1+ (0.01,0) [0|655.34] "V"  HVESP01
 SG_ HVESP01_afePwrWireAfeTotal_14_1 : 16|16@1+ (0.01,0) [0|655.34] "V"  HVESP01
 SG_ HVESP01_afePwrWireAfeTotal_15_1 : 32|16@1+ (0.01,0) [0|655.34] "V"  HVESP01
 SG_ HVESP01_afePwrWireAfeTotal_16_1 : 48|16@1+ (0.01,0) [0|655.34] "V"  HVESP01

BO_ 2499751270 HVESP01_AfePwrWireTotal_13_16_2: 8 HVESP01
 SG_ HVESP01_afePwrWireAfeTotal_13_2 : 0|16@1+ (0.01,0) [0|655.34] "V"  HVESP01
 SG_ HVESP01_afePwrWireAfeTotal_14_2 : 16|16@1+ (0.01,0) [0|655.34] "V"  HVESP01
 SG_ HVESP01_afePwrWireAfeTotal_15_2 : 32|16@1+ (0.01,0) [0|655.34] "V"  HVESP01
 SG_ HVESP01_afePwrWireAfeTotal_16_2 : 48|16@1+ (0.01,0) [0|655.34] "V"  HVESP01

BO_ 2499751271 HVESP01_AfePwrWireTotal_13_16_3: 8 HVESP01
 SG_ HVESP01_afePwrWireAfeTotal_13_3 : 0|16@1+ (0.01,0) [0|655.34] "V"  HVESP01
 SG_ HVESP01_afePwrWireAfeTotal_14_3 : 16|16@1+ (0.01,0) [0|655.34] "V"  HVESP01
 SG_ HVESP01_afePwrWireAfeTotal_15_3 : 32|16@1+ (0.01,0) [0|655.34] "V"  HVESP01
 SG_ HVESP01_afePwrWireAfeTotal_16_3 : 48|16@1+ (0.01,0) [0|655.34] "V"  HVESP01

BO_ 2499751272 HVESP01_AfePwrWireTotal_13_16_4: 8 HVESP01
 SG_ HVESP01_afePwrWireAfeTotal_13_4 : 0|16@1+ (0.01,0) [0|655.34] "V"  HVESP01
 SG_ HVESP01_afePwrWireAfeTotal_14_4 : 16|16@1+ (0.01,0) [0|655.34] "V"  HVESP01
 SG_ HVESP01_afePwrWireAfeTotal_15_4 : 32|16@1+ (0.01,0) [0|655.34] "V"  HVESP01
 SG_ HVESP01_afePwrWireAfeTotal_16_4 : 48|16@1+ (0.01,0) [0|655.34] "V"  HVESP01

BO_ 2499751273 HVESP01_AfePwrWireTotal_13_16_5: 8 HVESP01
 SG_ HVESP01_afePwrWireAfeTotal_13_5 : 0|16@1+ (0.01,0) [0|655.34] "V"  HVESP01
 SG_ HVESP01_afePwrWireAfeTotal_14_5 : 16|16@1+ (0.01,0) [0|655.34] "V"  HVESP01
 SG_ HVESP01_afePwrWireAfeTotal_15_5 : 32|16@1+ (0.01,0) [0|655.34] "V"  HVESP01
 SG_ HVESP01_afePwrWireAfeTotal_16_5 : 48|16@1+ (0.01,0) [0|655.34] "V"  HVESP01

BO_ 2499751274 HVESP01_AfePwrWireTotal_13_16_6: 8 HVESP01
 SG_ HVESP01_afePwrWireAfeTotal_13_6 : 0|16@1+ (0.01,0) [0|655.34] "V"  HVESP01
 SG_ HVESP01_afePwrWireAfeTotal_14_6 : 16|16@1+ (0.01,0) [0|655.34] "V"  HVESP01
 SG_ HVESP01_afePwrWireAfeTotal_15_6 : 32|16@1+ (0.01,0) [0|655.34] "V"  HVESP01
 SG_ HVESP01_afePwrWireAfeTotal_16_6 : 48|16@1+ (0.01,0) [0|655.34] "V"  HVESP01

BO_ 2499751275 HVESP01_AfePwrWireTotal_13_16_7: 8 HVESP01
 SG_ HVESP01_afePwrWireAfeTotal_13_7 : 0|16@1+ (0.01,0) [0|655.34] "V"  HVESP01
 SG_ HVESP01_afePwrWireAfeTotal_14_7 : 16|16@1+ (0.01,0) [0|655.34] "V"  HVESP01
 SG_ HVESP01_afePwrWireAfeTotal_15_7 : 32|16@1+ (0.01,0) [0|655.34] "V"  HVESP01
 SG_ HVESP01_afePwrWireAfeTotal_16_7 : 48|16@1+ (0.01,0) [0|655.34] "V"  HVESP01

BO_ 2499751276 HVESP01_AfePwrWireTotal_13_16_8: 8 HVESP01
 SG_ HVESP01_afePwrWireAfeTotal_13_8 : 0|16@1+ (0.01,0) [0|655.34] "V"  HVESP01
 SG_ HVESP01_afePwrWireAfeTotal_14_8 : 16|16@1+ (0.01,0) [0|655.34] "V"  HVESP01
 SG_ HVESP01_afePwrWireAfeTotal_15_8 : 32|16@1+ (0.01,0) [0|655.34] "V"  HVESP01
 SG_ HVESP01_afePwrWireAfeTotal_16_8 : 48|16@1+ (0.01,0) [0|655.34] "V"  HVESP01

BO_ 2499751525 HVESP01_AfePwrWireTotal_17_20_1: 8 HVESP01
 SG_ HVESP01_afePwrWireAfeTotal_17_1 : 0|16@1+ (0.01,0) [0|655.34] "V"  HVESP01
 SG_ HVESP01_afePwrWireAfeTotal_18_1 : 16|16@1+ (0.01,0) [0|655.34] "V"  HVESP01
 SG_ HVESP01_afePwrWireAfeTotal_19_1 : 32|16@1+ (0.01,0) [0|655.34] "V"  HVESP01
 SG_ HVESP01_afePwrWireAfeTotal_20_1 : 48|16@1+ (0.01,0) [0|655.34] "V"  HVESP01

BO_ 2499751526 HVESP01_AfePwrWireTotal_17_20_2: 8 HVESP01
 SG_ HVESP01_afePwrWireAfeTotal_17_2 : 0|16@1+ (0.01,0) [0|655.34] "V"  HVESP01
 SG_ HVESP01_afePwrWireAfeTotal_18_2 : 16|16@1+ (0.01,0) [0|655.34] "V"  HVESP01
 SG_ HVESP01_afePwrWireAfeTotal_19_2 : 32|16@1+ (0.01,0) [0|655.34] "V"  HVESP01
 SG_ HVESP01_afePwrWireAfeTotal_20_2 : 48|16@1+ (0.01,0) [0|655.34] "V"  HVESP01

BO_ 2499751527 HVESP01_AfePwrWireTotal_17_20_3: 8 HVESP01
 SG_ HVESP01_afePwrWireAfeTotal_17_3 : 0|16@1+ (0.01,0) [0|655.34] "V"  HVESP01
 SG_ HVESP01_afePwrWireAfeTotal_18_3 : 16|16@1+ (0.01,0) [0|655.34] "V"  HVESP01
 SG_ HVESP01_afePwrWireAfeTotal_19_3 : 32|16@1+ (0.01,0) [0|655.34] "V"  HVESP01
 SG_ HVESP01_afePwrWireAfeTotal_20_3 : 48|16@1+ (0.01,0) [0|655.34] "V"  HVESP01

BO_ 2499751528 HVESP01_AfePwrWireTotal_17_20_4: 8 HVESP01
 SG_ HVESP01_afePwrWireAfeTotal_17_4 : 0|16@1+ (0.01,0) [0|655.34] "V"  HVESP01
 SG_ HVESP01_afePwrWireAfeTotal_18_4 : 16|16@1+ (0.01,0) [0|655.34] "V"  HVESP01
 SG_ HVESP01_afePwrWireAfeTotal_19_4 : 32|16@1+ (0.01,0) [0|655.34] "V"  HVESP01
 SG_ HVESP01_afePwrWireAfeTotal_20_4 : 48|16@1+ (0.01,0) [0|655.34] "V"  HVESP01

BO_ 2499751529 HVESP01_AfePwrWireTotal_17_20_5: 8 HVESP01
 SG_ HVESP01_afePwrWireAfeTotal_17_5 : 0|16@1+ (0.01,0) [0|655.34] "V"  HVESP01
 SG_ HVESP01_afePwrWireAfeTotal_18_5 : 16|16@1+ (0.01,0) [0|655.34] "V"  HVESP01
 SG_ HVESP01_afePwrWireAfeTotal_19_5 : 32|16@1+ (0.01,0) [0|655.34] "V"  HVESP01
 SG_ HVESP01_afePwrWireAfeTotal_20_5 : 48|16@1+ (0.01,0) [0|655.34] "V"  HVESP01

BO_ 2499751530 HVESP01_AfePwrWireTotal_17_20_6: 8 HVESP01
 SG_ HVESP01_afePwrWireAfeTotal_17_6 : 0|16@1+ (0.01,0) [0|655.34] "V"  HVESP01
 SG_ HVESP01_afePwrWireAfeTotal_18_6 : 16|16@1+ (0.01,0) [0|655.34] "V"  HVESP01
 SG_ HVESP01_afePwrWireAfeTotal_19_6 : 32|16@1+ (0.01,0) [0|655.34] "V"  HVESP01
 SG_ HVESP01_afePwrWireAfeTotal_20_6 : 48|16@1+ (0.01,0) [0|655.34] "V"  HVESP01

BO_ 2499751531 HVESP01_AfePwrWireTotal_17_20_7: 8 HVESP01
 SG_ HVESP01_afePwrWireAfeTotal_17_7 : 0|16@1+ (0.01,0) [0|655.34] "V"  HVESP01
 SG_ HVESP01_afePwrWireAfeTotal_18_7 : 16|16@1+ (0.01,0) [0|655.34] "V"  HVESP01
 SG_ HVESP01_afePwrWireAfeTotal_19_7 : 32|16@1+ (0.01,0) [0|655.34] "V"  HVESP01
 SG_ HVESP01_afePwrWireAfeTotal_20_7 : 48|16@1+ (0.01,0) [0|655.34] "V"  HVESP01

BO_ 2499751532 HVESP01_AfePwrWireTotal_17_20_8: 8 HVESP01
 SG_ HVESP01_afePwrWireAfeTotal_17_8 : 0|16@1+ (0.01,0) [0|655.34] "V"  HVESP01
 SG_ HVESP01_afePwrWireAfeTotal_18_8 : 16|16@1+ (0.01,0) [0|655.34] "V"  HVESP01
 SG_ HVESP01_afePwrWireAfeTotal_19_8 : 32|16@1+ (0.01,0) [0|655.34] "V"  HVESP01
 SG_ HVESP01_afePwrWireAfeTotal_20_8 : 48|16@1+ (0.01,0) [0|655.34] "V"  HVESP01

BO_ 2499751781 HVESP01_AfePwrWireTotal_21_22_1: 8 HVESP01
 SG_ HVESP01_afePwrWireAfeTotal_21_1 : 0|16@1+ (0.01,0) [0|655.34] "V"  HVESP01
 SG_ HVESP01_afePwrWireAfeTotal_22_1 : 16|16@1+ (0.01,0) [0|655.34] "V"  HVESP01

BO_ 2499751782 HVESP01_AfePwrWireTotal_21_22_2: 8 HVESP01
 SG_ HVESP01_afePwrWireAfeTotal_21_2 : 0|16@1+ (0.01,0) [0|655.34] "V"  HVESP01
 SG_ HVESP01_afePwrWireAfeTotal_22_2 : 16|16@1+ (0.01,0) [0|655.34] "V"  HVESP01

BO_ 2499751783 HVESP01_AfePwrWireTotal_21_22_3: 8 HVESP01
 SG_ HVESP01_afePwrWireAfeTotal_21_3 : 0|16@1+ (0.01,0) [0|655.34] "V"  HVESP01
 SG_ HVESP01_afePwrWireAfeTotal_22_3 : 16|16@1+ (0.01,0) [0|655.34] "V"  HVESP01

BO_ 2499751784 HVESP01_AfePwrWireTotal_21_22_4: 8 HVESP01
 SG_ HVESP01_afePwrWireAfeTotal_21_4 : 0|16@1+ (0.01,0) [0|655.34] "V"  HVESP01
 SG_ HVESP01_afePwrWireAfeTotal_22_4 : 16|16@1+ (0.01,0) [0|655.34] "V"  HVESP01

BO_ 2499751785 HVESP01_AfePwrWireTotal_21_22_5: 8 HVESP01
 SG_ HVESP01_afePwrWireAfeTotal_21_5 : 0|16@1+ (0.01,0) [0|655.34] "V"  HVESP01
 SG_ HVESP01_afePwrWireAfeTotal_22_5 : 16|16@1+ (0.01,0) [0|655.34] "V"  HVESP01

BO_ 2499751786 HVESP01_AfePwrWireTotal_21_22_6: 8 HVESP01
 SG_ HVESP01_afePwrWireAfeTotal_21_6 : 0|16@1+ (0.01,0) [0|655.34] "V"  HVESP01
 SG_ HVESP01_afePwrWireAfeTotal_22_6 : 16|16@1+ (0.01,0) [0|655.34] "V"  HVESP01

BO_ 2499751787 HVESP01_AfePwrWireTotal_21_22_7: 8 HVESP01
 SG_ HVESP01_afePwrWireAfeTotal_21_7 : 0|16@1+ (0.01,0) [0|655.34] "V"  HVESP01
 SG_ HVESP01_afePwrWireAfeTotal_22_7 : 16|16@1+ (0.01,0) [0|655.34] "V"  HVESP01

BO_ 2499751788 HVESP01_AfePwrWireTotal_21_22_8: 8 HVESP01
 SG_ HVESP01_afePwrWireAfeTotal_21_8 : 0|16@1+ (0.01,0) [0|655.34] "V"  HVESP01
 SG_ HVESP01_afePwrWireAfeTotal_22_8 : 16|16@1+ (0.01,0) [0|655.34] "V"  HVESP01

BO_ 2499752037 HVESP01_AfePwrWireCellSum_01_04_: 8 HVESP01
 SG_ HVESP01_afePwrWireCellSum_01_1 : 0|16@1+ (0.01,0) [0|655.34] "V"  HVESP01
 SG_ HVESP01_afePwrWireCellSum_02_1 : 16|16@1+ (0.01,0) [0|655.34] "V"  HVESP01
 SG_ HVESP01_afePwrWireCellSum_03_1 : 32|16@1+ (0.01,0) [0|655.34] "V"  HVESP01
 SG_ HVESP01_afePwrWireCellSum_04_1 : 48|16@1+ (0.01,0) [0|655.34] "V"  HVESP01

BO_ 2499752038 HVESP01_AfePwrWireCellSum_0_0000: 8 HVESP01
 SG_ HVESP01_afePwrWireCellSum_01_2 : 0|16@1+ (0.01,0) [0|655.34] "V"  HVESP01
 SG_ HVESP01_afePwrWireCellSum_02_2 : 16|16@1+ (0.01,0) [0|655.34] "V"  HVESP01
 SG_ HVESP01_afePwrWireCellSum_03_2 : 32|16@1+ (0.01,0) [0|655.34] "V"  HVESP01
 SG_ HVESP01_afePwrWireCellSum_04_2 : 48|16@1+ (0.01,0) [0|655.34] "V"  HVESP01

BO_ 2499752039 HVESP01_AfePwrWireCellSum_0_0001: 8 HVESP01
 SG_ HVESP01_afePwrWireCellSum_01_3 : 0|16@1+ (0.01,0) [0|655.34] "V"  HVESP01
 SG_ HVESP01_afePwrWireCellSum_02_3 : 16|16@1+ (0.01,0) [0|655.34] "V"  HVESP01
 SG_ HVESP01_afePwrWireCellSum_03_3 : 32|16@1+ (0.01,0) [0|655.34] "V"  HVESP01
 SG_ HVESP01_afePwrWireCellSum_04_3 : 48|16@1+ (0.01,0) [0|655.34] "V"  HVESP01

BO_ 2499752040 HVESP01_AfePwrWireCellSum_0_0002: 8 HVESP01
 SG_ HVESP01_afePwrWireCellSum_01_4 : 0|16@1+ (0.01,0) [0|655.34] "V"  HVESP01
 SG_ HVESP01_afePwrWireCellSum_02_4 : 16|16@1+ (0.01,0) [0|655.34] "V"  HVESP01
 SG_ HVESP01_afePwrWireCellSum_03_4 : 32|16@1+ (0.01,0) [0|655.34] "V"  HVESP01
 SG_ HVESP01_afePwrWireCellSum_04_4 : 48|16@1+ (0.01,0) [0|655.34] "V"  HVESP01

BO_ 2499752041 HVESP01_AfePwrWireCellSum_0_0003: 8 HVESP01
 SG_ HVESP01_afePwrWireCellSum_01_5 : 0|16@1+ (0.01,0) [0|655.34] "V"  HVESP01
 SG_ HVESP01_afePwrWireCellSum_02_5 : 16|16@1+ (0.01,0) [0|655.34] "V"  HVESP01
 SG_ HVESP01_afePwrWireCellSum_03_5 : 32|16@1+ (0.01,0) [0|655.34] "V"  HVESP01
 SG_ HVESP01_afePwrWireCellSum_04_5 : 48|16@1+ (0.01,0) [0|655.34] "V"  HVESP01

BO_ 2499752042 HVESP01_AfePwrWireCellSum_0_0004: 8 HVESP01
 SG_ HVESP01_afePwrWireCellSum_01_6 : 0|16@1+ (0.01,0) [0|655.34] "V"  HVESP01
 SG_ HVESP01_afePwrWireCellSum_02_6 : 16|16@1+ (0.01,0) [0|655.34] "V"  HVESP01
 SG_ HVESP01_afePwrWireCellSum_03_6 : 32|16@1+ (0.01,0) [0|655.34] "V"  HVESP01
 SG_ HVESP01_afePwrWireCellSum_04_6 : 48|16@1+ (0.01,0) [0|655.34] "V"  HVESP01

BO_ 2499752043 HVESP01_AfePwrWireCellSum_0_0005: 8 HVESP01
 SG_ HVESP01_afePwrWireCellSum_01_7 : 0|16@1+ (0.01,0) [0|655.34] "V"  HVESP01
 SG_ HVESP01_afePwrWireCellSum_02_7 : 16|16@1+ (0.01,0) [0|655.34] "V"  HVESP01
 SG_ HVESP01_afePwrWireCellSum_03_7 : 32|16@1+ (0.01,0) [0|655.34] "V"  HVESP01
 SG_ HVESP01_afePwrWireCellSum_04_7 : 48|16@1+ (0.01,0) [0|655.34] "V"  HVESP01

BO_ 2499752044 HVESP01_AfePwrWireCellSum_0_0006: 8 HVESP01
 SG_ HVESP01_afePwrWireCellSum_01_8 : 0|16@1+ (0.01,0) [0|655.34] "V"  HVESP01
 SG_ HVESP01_afePwrWireCellSum_02_8 : 16|16@1+ (0.01,0) [0|655.34] "V"  HVESP01
 SG_ HVESP01_afePwrWireCellSum_03_8 : 32|16@1+ (0.01,0) [0|655.34] "V"  HVESP01
 SG_ HVESP01_afePwrWireCellSum_04_8 : 48|16@1+ (0.01,0) [0|655.34] "V"  HVESP01

BO_ 2499752293 HVESP01_AfePwrWireCellSum_05_08_: 8 HVESP01
 SG_ HVESP01_afePwrWireCellSum_05_1 : 0|16@1+ (0.01,0) [0|655.34] "V"  HVESP01
 SG_ HVESP01_afePwrWireCellSum_06_1 : 16|16@1+ (0.01,0) [0|655.34] "V"  HVESP01
 SG_ HVESP01_afePwrWireCellSum_07_1 : 32|16@1+ (0.01,0) [0|655.34] "V"  HVESP01
 SG_ HVESP01_afePwrWireCellSum_08_1 : 48|16@1+ (0.01,0) [0|655.34] "V"  HVESP01

BO_ 2499752294 HVESP01_AfePwrWireCellSum_0_0007: 8 HVESP01
 SG_ HVESP01_afePwrWireCellSum_05_2 : 0|16@1+ (0.01,0) [0|655.34] "V"  HVESP01
 SG_ HVESP01_afePwrWireCellSum_06_2 : 16|16@1+ (0.01,0) [0|655.34] "V"  HVESP01
 SG_ HVESP01_afePwrWireCellSum_07_2 : 32|16@1+ (0.01,0) [0|655.34] "V"  HVESP01
 SG_ HVESP01_afePwrWireCellSum_08_2 : 48|16@1+ (0.01,0) [0|655.34] "V"  HVESP01

BO_ 2499752295 HVESP01_AfePwrWireCellSum_0_0008: 8 HVESP01
 SG_ HVESP01_afePwrWireCellSum_05_3 : 0|16@1+ (0.01,0) [0|655.34] "V"  HVESP01
 SG_ HVESP01_afePwrWireCellSum_06_3 : 16|16@1+ (0.01,0) [0|655.34] "V"  HVESP01
 SG_ HVESP01_afePwrWireCellSum_07_3 : 32|16@1+ (0.01,0) [0|655.34] "V"  HVESP01
 SG_ HVESP01_afePwrWireCellSum_08_3 : 48|16@1+ (0.01,0) [0|655.34] "V"  HVESP01

BO_ 2499752296 HVESP01_AfePwrWireCellSum_0_0009: 8 HVESP01
 SG_ HVESP01_afePwrWireCellSum_05_4 : 0|16@1+ (0.01,0) [0|655.34] "V"  HVESP01
 SG_ HVESP01_afePwrWireCellSum_06_4 : 16|16@1+ (0.01,0) [0|655.34] "V"  HVESP01
 SG_ HVESP01_afePwrWireCellSum_07_4 : 32|16@1+ (0.01,0) [0|655.34] "V"  HVESP01
 SG_ HVESP01_afePwrWireCellSum_08_4 : 48|16@1+ (0.01,0) [0|655.34] "V"  HVESP01

BO_ 2499752297 HVESP01_AfePwrWireCellSum_0_0010: 8 HVESP01
 SG_ HVESP01_afePwrWireCellSum_05_5 : 0|16@1+ (0.01,0) [0|655.34] "V"  HVESP01
 SG_ HVESP01_afePwrWireCellSum_06_5 : 16|16@1+ (0.01,0) [0|655.34] "V"  HVESP01
 SG_ HVESP01_afePwrWireCellSum_07_5 : 32|16@1+ (0.01,0) [0|655.34] "V"  HVESP01
 SG_ HVESP01_afePwrWireCellSum_08_5 : 48|16@1+ (0.01,0) [0|655.34] "V"  HVESP01

BO_ 2499752298 HVESP01_AfePwrWireCellSum_0_0011: 8 HVESP01
 SG_ HVESP01_afePwrWireCellSum_05_6 : 0|16@1+ (0.01,0) [0|655.34] "V"  HVESP01
 SG_ HVESP01_afePwrWireCellSum_06_6 : 16|16@1+ (0.01,0) [0|655.34] "V"  HVESP01
 SG_ HVESP01_afePwrWireCellSum_07_6 : 32|16@1+ (0.01,0) [0|655.34] "V"  HVESP01
 SG_ HVESP01_afePwrWireCellSum_08_6 : 48|16@1+ (0.01,0) [0|655.34] "V"  HVESP01

BO_ 2499752299 HVESP01_AfePwrWireCellSum_0_0012: 8 HVESP01
 SG_ HVESP01_afePwrWireCellSum_05_7 : 0|16@1+ (0.01,0) [0|655.34] "V"  HVESP01
 SG_ HVESP01_afePwrWireCellSum_06_7 : 16|16@1+ (0.01,0) [0|655.34] "V"  HVESP01
 SG_ HVESP01_afePwrWireCellSum_07_7 : 32|16@1+ (0.01,0) [0|655.34] "V"  HVESP01
 SG_ HVESP01_afePwrWireCellSum_08_7 : 48|16@1+ (0.01,0) [0|655.34] "V"  HVESP01

BO_ 2499752300 HVESP01_AfePwrWireCellSum_0_0013: 8 HVESP01
 SG_ HVESP01_afePwrWireCellSum_05_8 : 0|16@1+ (0.01,0) [0|655.34] "V"  HVESP01
 SG_ HVESP01_afePwrWireCellSum_06_8 : 16|16@1+ (0.01,0) [0|655.34] "V"  HVESP01
 SG_ HVESP01_afePwrWireCellSum_07_8 : 32|16@1+ (0.01,0) [0|655.34] "V"  HVESP01
 SG_ HVESP01_afePwrWireCellSum_08_8 : 48|16@1+ (0.01,0) [0|655.34] "V"  HVESP01

BO_ 2499752549 HVESP01_AfePwrWireCellSum_09_12_: 8 HVESP01
 SG_ HVESP01_afePwrWireCellSum_09_1 : 0|16@1+ (0.01,0) [0|655.34] "V"  HVESP01
 SG_ HVESP01_afePwrWireCellSum_10_1 : 16|16@1+ (0.01,0) [0|655.34] "V"  HVESP01
 SG_ HVESP01_afePwrWireCellSum_11_1 : 32|16@1+ (0.01,0) [0|655.34] "V"  HVESP01
 SG_ HVESP01_afePwrWireCellSum_12_1 : 48|16@1+ (0.01,0) [0|655.34] "V"  HVESP01

BO_ 2499752550 HVESP01_AfePwrWireCellSum_0_0014: 8 HVESP01
 SG_ HVESP01_afePwrWireCellSum_09_2 : 0|16@1+ (0.01,0) [0|655.34] "V"  HVESP01
 SG_ HVESP01_afePwrWireCellSum_10_2 : 16|16@1+ (0.01,0) [0|655.34] "V"  HVESP01
 SG_ HVESP01_afePwrWireCellSum_11_2 : 32|16@1+ (0.01,0) [0|655.34] "V"  HVESP01
 SG_ HVESP01_afePwrWireCellSum_12_2 : 48|16@1+ (0.01,0) [0|655.34] "V"  HVESP01

BO_ 2499752551 HVESP01_AfePwrWireCellSum_0_0015: 8 HVESP01
 SG_ HVESP01_afePwrWireCellSum_09_3 : 0|16@1+ (0.01,0) [0|655.34] "V"  HVESP01
 SG_ HVESP01_afePwrWireCellSum_10_3 : 16|16@1+ (0.01,0) [0|655.34] "V"  HVESP01
 SG_ HVESP01_afePwrWireCellSum_11_3 : 32|16@1+ (0.01,0) [0|655.34] "V"  HVESP01
 SG_ HVESP01_afePwrWireCellSum_12_3 : 48|16@1+ (0.01,0) [0|655.34] "V"  HVESP01

BO_ 2499752552 HVESP01_AfePwrWireCellSum_0_0016: 8 HVESP01
 SG_ HVESP01_afePwrWireCellSum_09_4 : 0|16@1+ (0.01,0) [0|655.34] "V"  HVESP01
 SG_ HVESP01_afePwrWireCellSum_10_4 : 16|16@1+ (0.01,0) [0|655.34] "V"  HVESP01
 SG_ HVESP01_afePwrWireCellSum_11_4 : 32|16@1+ (0.01,0) [0|655.34] "V"  HVESP01
 SG_ HVESP01_afePwrWireCellSum_12_4 : 48|16@1+ (0.01,0) [0|655.34] "V"  HVESP01

BO_ 2499752553 HVESP01_AfePwrWireCellSum_0_0017: 8 HVESP01
 SG_ HVESP01_afePwrWireCellSum_09_5 : 0|16@1+ (0.01,0) [0|655.34] "V"  HVESP01
 SG_ HVESP01_afePwrWireCellSum_10_5 : 16|16@1+ (0.01,0) [0|655.34] "V"  HVESP01
 SG_ HVESP01_afePwrWireCellSum_11_5 : 32|16@1+ (0.01,0) [0|655.34] "V"  HVESP01
 SG_ HVESP01_afePwrWireCellSum_12_5 : 48|16@1+ (0.01,0) [0|655.34] "V"  HVESP01

BO_ 2499752554 HVESP01_AfePwrWireCellSum_0_0018: 8 HVESP01
 SG_ HVESP01_afePwrWireCellSum_09_6 : 0|16@1+ (0.01,0) [0|655.34] "V"  HVESP01
 SG_ HVESP01_afePwrWireCellSum_10_6 : 16|16@1+ (0.01,0) [0|655.34] "V"  HVESP01
 SG_ HVESP01_afePwrWireCellSum_11_6 : 32|16@1+ (0.01,0) [0|655.34] "V"  HVESP01
 SG_ HVESP01_afePwrWireCellSum_12_6 : 48|16@1+ (0.01,0) [0|655.34] "V"  HVESP01

BO_ 2499752555 HVESP01_AfePwrWireCellSum_0_0019: 8 HVESP01
 SG_ HVESP01_afePwrWireCellSum_09_7 : 0|16@1+ (0.01,0) [0|655.34] "V"  HVESP01
 SG_ HVESP01_afePwrWireCellSum_10_7 : 16|16@1+ (0.01,0) [0|655.34] "V"  HVESP01
 SG_ HVESP01_afePwrWireCellSum_11_7 : 32|16@1+ (0.01,0) [0|655.34] "V"  HVESP01
 SG_ HVESP01_afePwrWireCellSum_12_7 : 48|16@1+ (0.01,0) [0|655.34] "V"  HVESP01

BO_ 2499752556 HVESP01_AfePwrWireCellSum_0_0020: 8 HVESP01
 SG_ HVESP01_afePwrWireCellSum_09_8 : 0|16@1+ (0.01,0) [0|655.34] "V"  HVESP01
 SG_ HVESP01_afePwrWireCellSum_10_8 : 16|16@1+ (0.01,0) [0|655.34] "V"  HVESP01
 SG_ HVESP01_afePwrWireCellSum_11_8 : 32|16@1+ (0.01,0) [0|655.34] "V"  HVESP01
 SG_ HVESP01_afePwrWireCellSum_12_8 : 48|16@1+ (0.01,0) [0|655.34] "V"  HVESP01

BO_ 2499752805 HVESP01_AfePwrWireCellSum_13_16_: 8 HVESP01
 SG_ HVESP01_afePwrWireCellSum_13_1 : 0|16@1+ (0.01,0) [0|655.34] "V"  HVESP01
 SG_ HVESP01_afePwrWireCellSum_14_1 : 16|16@1+ (0.01,0) [0|655.34] "V"  HVESP01
 SG_ HVESP01_afePwrWireCellSum_15_1 : 32|16@1+ (0.01,0) [0|655.34] "V"  HVESP01
 SG_ HVESP01_afePwrWireCellSum_16_1 : 48|16@1+ (0.01,0) [0|655.34] "V"  HVESP01

BO_ 2499752806 HVESP01_AfePwrWireCellSum_1_0000: 8 HVESP01
 SG_ HVESP01_afePwrWireCellSum_13_2 : 0|16@1+ (0.01,0) [0|655.34] "V"  HVESP01
 SG_ HVESP01_afePwrWireCellSum_14_2 : 16|16@1+ (0.01,0) [0|655.34] "V"  HVESP01
 SG_ HVESP01_afePwrWireCellSum_15_2 : 32|16@1+ (0.01,0) [0|655.34] "V"  HVESP01
 SG_ HVESP01_afePwrWireCellSum_16_2 : 48|16@1+ (0.01,0) [0|655.34] "V"  HVESP01

BO_ 2499752807 HVESP01_AfePwrWireCellSum_1_0001: 8 HVESP01
 SG_ HVESP01_afePwrWireCellSum_13_3 : 0|16@1+ (0.01,0) [0|655.34] "V"  HVESP01
 SG_ HVESP01_afePwrWireCellSum_14_3 : 16|16@1+ (0.01,0) [0|655.34] "V"  HVESP01
 SG_ HVESP01_afePwrWireCellSum_15_3 : 32|16@1+ (0.01,0) [0|655.34] "V"  HVESP01
 SG_ HVESP01_afePwrWireCellSum_16_3 : 48|16@1+ (0.01,0) [0|655.34] "V"  HVESP01

BO_ 2499752808 HVESP01_AfePwrWireCellSum_1_0002: 8 HVESP01
 SG_ HVESP01_afePwrWireCellSum_13_4 : 0|16@1+ (0.01,0) [0|655.34] "V"  HVESP01
 SG_ HVESP01_afePwrWireCellSum_14_4 : 16|16@1+ (0.01,0) [0|655.34] "V"  HVESP01
 SG_ HVESP01_afePwrWireCellSum_15_4 : 32|16@1+ (0.01,0) [0|655.34] "V"  HVESP01
 SG_ HVESP01_afePwrWireCellSum_16_4 : 48|16@1+ (0.01,0) [0|655.34] "V"  HVESP01

BO_ 2499752809 HVESP01_AfePwrWireCellSum_1_0003: 8 HVESP01
 SG_ HVESP01_afePwrWireCellSum_13_5 : 0|16@1+ (0.01,0) [0|655.34] "V"  HVESP01
 SG_ HVESP01_afePwrWireCellSum_14_5 : 16|16@1+ (0.01,0) [0|655.34] "V"  HVESP01
 SG_ HVESP01_afePwrWireCellSum_15_5 : 32|16@1+ (0.01,0) [0|655.34] "V"  HVESP01
 SG_ HVESP01_afePwrWireCellSum_16_5 : 48|16@1+ (0.01,0) [0|655.34] "V"  HVESP01

BO_ 2499752810 HVESP01_AfePwrWireCellSum_1_0004: 8 HVESP01
 SG_ HVESP01_afePwrWireCellSum_13_6 : 0|16@1+ (0.01,0) [0|655.34] "V"  HVESP01
 SG_ HVESP01_afePwrWireCellSum_14_6 : 16|16@1+ (0.01,0) [0|655.34] "V"  HVESP01
 SG_ HVESP01_afePwrWireCellSum_15_6 : 32|16@1+ (0.01,0) [0|655.34] "V"  HVESP01
 SG_ HVESP01_afePwrWireCellSum_16_6 : 48|16@1+ (0.01,0) [0|655.34] "V"  HVESP01

BO_ 2499752811 HVESP01_AfePwrWireCellSum_1_0005: 8 HVESP01
 SG_ HVESP01_afePwrWireCellSum_13_7 : 0|16@1+ (0.01,0) [0|655.34] "V"  HVESP01
 SG_ HVESP01_afePwrWireCellSum_14_7 : 16|16@1+ (0.01,0) [0|655.34] "V"  HVESP01
 SG_ HVESP01_afePwrWireCellSum_15_7 : 32|16@1+ (0.01,0) [0|655.34] "V"  HVESP01
 SG_ HVESP01_afePwrWireCellSum_16_7 : 48|16@1+ (0.01,0) [0|655.34] "V"  HVESP01

BO_ 2499752812 HVESP01_AfePwrWireCellSum_1_0006: 8 HVESP01
 SG_ HVESP01_afePwrWireCellSum_13_8 : 0|16@1+ (0.01,0) [0|655.34] "V"  HVESP01
 SG_ HVESP01_afePwrWireCellSum_14_8 : 16|16@1+ (0.01,0) [0|655.34] "V"  HVESP01
 SG_ HVESP01_afePwrWireCellSum_15_8 : 32|16@1+ (0.01,0) [0|655.34] "V"  HVESP01
 SG_ HVESP01_afePwrWireCellSum_16_8 : 48|16@1+ (0.01,0) [0|655.34] "V"  HVESP01

BO_ 2499753061 HVESP01_AfePwrWireCellSum_17_20_: 8 HVESP01
 SG_ HVESP01_afePwrWireCellSum_17_1 : 0|16@1+ (0.01,0) [0|655.34] "V"  HVESP01
 SG_ HVESP01_afePwrWireCellSum_18_1 : 16|16@1+ (0.01,0) [0|655.34] "V"  HVESP01
 SG_ HVESP01_afePwrWireCellSum_19_1 : 32|16@1+ (0.01,0) [0|655.34] "V"  HVESP01
 SG_ HVESP01_afePwrWireCellSum_20_1 : 48|16@1+ (0.01,0) [0|655.34] "V"  HVESP01

BO_ 2499753062 HVESP01_AfePwrWireCellSum_1_0007: 8 HVESP01
 SG_ HVESP01_afePwrWireCellSum_17_2 : 0|16@1+ (0.01,0) [0|655.34] "V"  HVESP01
 SG_ HVESP01_afePwrWireCellSum_18_2 : 16|16@1+ (0.01,0) [0|655.34] "V"  HVESP01
 SG_ HVESP01_afePwrWireCellSum_19_2 : 32|16@1+ (0.01,0) [0|655.34] "V"  HVESP01
 SG_ HVESP01_afePwrWireCellSum_20_2 : 48|16@1+ (0.01,0) [0|655.34] "V"  HVESP01

BO_ 2499753063 HVESP01_AfePwrWireCellSum_1_0008: 8 HVESP01
 SG_ HVESP01_afePwrWireCellSum_17_3 : 0|16@1+ (0.01,0) [0|655.34] "V"  HVESP01
 SG_ HVESP01_afePwrWireCellSum_18_3 : 16|16@1+ (0.01,0) [0|655.34] "V"  HVESP01
 SG_ HVESP01_afePwrWireCellSum_19_3 : 32|16@1+ (0.01,0) [0|655.34] "V"  HVESP01
 SG_ HVESP01_afePwrWireCellSum_20_3 : 48|16@1+ (0.01,0) [0|655.34] "V"  HVESP01

BO_ 2499753064 HVESP01_AfePwrWireCellSum_1_0009: 8 HVESP01
 SG_ HVESP01_afePwrWireCellSum_17_4 : 0|16@1+ (0.01,0) [0|655.34] "V"  HVESP01
 SG_ HVESP01_afePwrWireCellSum_18_4 : 16|16@1+ (0.01,0) [0|655.34] "V"  HVESP01
 SG_ HVESP01_afePwrWireCellSum_19_4 : 32|16@1+ (0.01,0) [0|655.34] "V"  HVESP01
 SG_ HVESP01_afePwrWireCellSum_20_4 : 48|16@1+ (0.01,0) [0|655.34] "V"  HVESP01

BO_ 2499753065 HVESP01_AfePwrWireCellSum_1_0010: 8 HVESP01
 SG_ HVESP01_afePwrWireCellSum_17_5 : 0|16@1+ (0.01,0) [0|655.34] "V"  HVESP01
 SG_ HVESP01_afePwrWireCellSum_18_5 : 16|16@1+ (0.01,0) [0|655.34] "V"  HVESP01
 SG_ HVESP01_afePwrWireCellSum_19_5 : 32|16@1+ (0.01,0) [0|655.34] "V"  HVESP01
 SG_ HVESP01_afePwrWireCellSum_20_5 : 48|16@1+ (0.01,0) [0|655.34] "V"  HVESP01

BO_ 2499753066 HVESP01_AfePwrWireCellSum_1_0011: 8 HVESP01
 SG_ HVESP01_afePwrWireCellSum_17_6 : 0|16@1+ (0.01,0) [0|655.34] "V"  HVESP01
 SG_ HVESP01_afePwrWireCellSum_18_6 : 16|16@1+ (0.01,0) [0|655.34] "V"  HVESP01
 SG_ HVESP01_afePwrWireCellSum_19_6 : 32|16@1+ (0.01,0) [0|655.34] "V"  HVESP01
 SG_ HVESP01_afePwrWireCellSum_20_6 : 48|16@1+ (0.01,0) [0|655.34] "V"  HVESP01

BO_ 2499753067 HVESP01_AfePwrWireCellSum_1_0012: 8 HVESP01
 SG_ HVESP01_afePwrWireCellSum_17_7 : 0|16@1+ (0.01,0) [0|655.34] "V"  HVESP01
 SG_ HVESP01_afePwrWireCellSum_18_7 : 16|16@1+ (0.01,0) [0|655.34] "V"  HVESP01
 SG_ HVESP01_afePwrWireCellSum_19_7 : 32|16@1+ (0.01,0) [0|655.34] "V"  HVESP01
 SG_ HVESP01_afePwrWireCellSum_20_7 : 48|16@1+ (0.01,0) [0|655.34] "V"  HVESP01

BO_ 2499753068 HVESP01_AfePwrWireCellSum_1_0013: 8 HVESP01
 SG_ HVESP01_afePwrWireCellSum_17_8 : 0|16@1+ (0.01,0) [0|655.34] "V"  HVESP01
 SG_ HVESP01_afePwrWireCellSum_18_8 : 16|16@1+ (0.01,0) [0|655.34] "V"  HVESP01
 SG_ HVESP01_afePwrWireCellSum_19_8 : 32|16@1+ (0.01,0) [0|655.34] "V"  HVESP01
 SG_ HVESP01_afePwrWireCellSum_20_8 : 48|16@1+ (0.01,0) [0|655.34] "V"  HVESP01

BO_ 2499753317 HVESP01_AfePwrWireCellSum_21_22_: 8 HVESP01
 SG_ HVESP01_afePwrWireCellSum_21_1 : 0|16@1+ (0.01,0) [0|655.34] "V"  HVESP01
 SG_ HVESP01_afePwrWireCellSum_22_1 : 16|16@1+ (0.01,0) [0|655.34] "V"  HVESP01

BO_ 2499753318 HVESP01_AfePwrWireCellSum_2_0000: 8 HVESP01
 SG_ HVESP01_afePwrWireCellSum_21_2 : 0|16@1+ (0.01,0) [0|655.34] "V"  HVESP01
 SG_ HVESP01_afePwrWireCellSum_22_2 : 16|16@1+ (0.01,0) [0|655.34] "V"  HVESP01

BO_ 2499753319 HVESP01_AfePwrWireCellSum_2_0001: 8 HVESP01
 SG_ HVESP01_afePwrWireCellSum_21_3 : 0|16@1+ (0.01,0) [0|655.34] "V"  HVESP01
 SG_ HVESP01_afePwrWireCellSum_22_3 : 16|16@1+ (0.01,0) [0|655.34] "V"  HVESP01

BO_ 2499753320 HVESP01_AfePwrWireCellSum_2_0002: 8 HVESP01
 SG_ HVESP01_afePwrWireCellSum_21_4 : 0|16@1+ (0.01,0) [0|655.34] "V"  HVESP01
 SG_ HVESP01_afePwrWireCellSum_22_4 : 16|16@1+ (0.01,0) [0|655.34] "V"  HVESP01

BO_ 2499753321 HVESP01_AfePwrWireCellSum_2_0003: 8 HVESP01
 SG_ HVESP01_afePwrWireCellSum_21_5 : 0|16@1+ (0.01,0) [0|655.34] "V"  HVESP01
 SG_ HVESP01_afePwrWireCellSum_22_5 : 16|16@1+ (0.01,0) [0|655.34] "V"  HVESP01

BO_ 2499753322 HVESP01_AfePwrWireCellSum_2_0004: 8 HVESP01
 SG_ HVESP01_afePwrWireCellSum_21_6 : 0|16@1+ (0.01,0) [0|655.34] "V"  HVESP01
 SG_ HVESP01_afePwrWireCellSum_22_6 : 16|16@1+ (0.01,0) [0|655.34] "V"  HVESP01

BO_ 2499753323 HVESP01_AfePwrWireCellSum_2_0005: 8 HVESP01
 SG_ HVESP01_afePwrWireCellSum_21_7 : 0|16@1+ (0.01,0) [0|655.34] "V"  HVESP01
 SG_ HVESP01_afePwrWireCellSum_22_7 : 16|16@1+ (0.01,0) [0|655.34] "V"  HVESP01

BO_ 2499753324 HVESP01_AfePwrWireCellSum_2_0006: 8 HVESP01
 SG_ HVESP01_afePwrWireCellSum_21_8 : 0|16@1+ (0.01,0) [0|655.34] "V"  HVESP01
 SG_ HVESP01_afePwrWireCellSum_22_8 : 16|16@1+ (0.01,0) [0|655.34] "V"  HVESP01

BO_ 2499753573 HVESP01_AfePwrWireDelta_01_04_1: 8 HVESP01
 SG_ HVESP01_afePwrWireDelta_01_1 : 0|16@1+ (0.01,0) [0|655.34] "V"  HVESP01
 SG_ HVESP01_afePwrWireDelta_02_1 : 16|16@1+ (0.01,0) [0|655.34] "V"  HVESP01
 SG_ HVESP01_afePwrWireDelta_03_1 : 32|16@1+ (0.01,0) [0|655.34] "V"  HVESP01
 SG_ HVESP01_afePwrWireDelta_04_1 : 48|16@1+ (0.01,0) [0|655.34] "V"  HVESP01

BO_ 2499753574 HVESP01_AfePwrWireDelta_01_04_2: 8 HVESP01
 SG_ HVESP01_afePwrWireDelta_01_2 : 0|16@1+ (0.01,0) [0|655.34] "V"  HVESP01
 SG_ HVESP01_afePwrWireDelta_02_2 : 16|16@1+ (0.01,0) [0|655.34] "V"  HVESP01
 SG_ HVESP01_afePwrWireDelta_03_2 : 32|16@1+ (0.01,0) [0|655.34] "V"  HVESP01
 SG_ HVESP01_afePwrWireDelta_04_2 : 48|16@1+ (0.01,0) [0|655.34] "V"  HVESP01

BO_ 2499753575 HVESP01_AfePwrWireDelta_01_04_3: 8 HVESP01
 SG_ HVESP01_afePwrWireDelta_01_3 : 0|16@1+ (0.01,0) [0|655.34] "V"  HVESP01
 SG_ HVESP01_afePwrWireDelta_02_3 : 16|16@1+ (0.01,0) [0|655.34] "V"  HVESP01
 SG_ HVESP01_afePwrWireDelta_03_3 : 32|16@1+ (0.01,0) [0|655.34] "V"  HVESP01
 SG_ HVESP01_afePwrWireDelta_04_3 : 48|16@1+ (0.01,0) [0|655.34] "V"  HVESP01

BO_ 2499753576 HVESP01_AfePwrWireDelta_01_04_4: 8 HVESP01
 SG_ HVESP01_afePwrWireDelta_01_4 : 0|16@1+ (0.01,0) [0|655.34] "V"  HVESP01
 SG_ HVESP01_afePwrWireDelta_02_4 : 16|16@1+ (0.01,0) [0|655.34] "V"  HVESP01
 SG_ HVESP01_afePwrWireDelta_03_4 : 32|16@1+ (0.01,0) [0|655.34] "V"  HVESP01
 SG_ HVESP01_afePwrWireDelta_04_4 : 48|16@1+ (0.01,0) [0|655.34] "V"  HVESP01

BO_ 2499753577 HVESP01_AfePwrWireDelta_01_04_5: 8 HVESP01
 SG_ HVESP01_afePwrWireDelta_01_5 : 0|16@1+ (0.01,0) [0|655.34] "V"  HVESP01
 SG_ HVESP01_afePwrWireDelta_02_5 : 16|16@1+ (0.01,0) [0|655.34] "V"  HVESP01
 SG_ HVESP01_afePwrWireDelta_03_5 : 32|16@1+ (0.01,0) [0|655.34] "V"  HVESP01
 SG_ HVESP01_afePwrWireDelta_04_5 : 48|16@1+ (0.01,0) [0|655.34] "V"  HVESP01

BO_ 2499753578 HVESP01_AfePwrWireDelta_01_04_6: 8 HVESP01
 SG_ HVESP01_afePwrWireDelta_01_6 : 0|16@1+ (0.01,0) [0|655.34] "V"  HVESP01
 SG_ HVESP01_afePwrWireDelta_02_6 : 16|16@1+ (0.01,0) [0|655.34] "V"  HVESP01
 SG_ HVESP01_afePwrWireDelta_03_6 : 32|16@1+ (0.01,0) [0|655.34] "V"  HVESP01
 SG_ HVESP01_afePwrWireDelta_04_6 : 48|16@1+ (0.01,0) [0|655.34] "V"  HVESP01

BO_ 2499753579 HVESP01_AfePwrWireDelta_01_04_7: 8 HVESP01
 SG_ HVESP01_afePwrWireDelta_01_7 : 0|16@1+ (0.01,0) [0|655.34] "V"  HVESP01
 SG_ HVESP01_afePwrWireDelta_02_7 : 16|16@1+ (0.01,0) [0|655.34] "V"  HVESP01
 SG_ HVESP01_afePwrWireDelta_03_7 : 32|16@1+ (0.01,0) [0|655.34] "V"  HVESP01
 SG_ HVESP01_afePwrWireDelta_04_7 : 48|16@1+ (0.01,0) [0|655.34] "V"  HVESP01

BO_ 2499753580 HVESP01_AfePwrWireDelta_01_04_8: 8 HVESP01
 SG_ HVESP01_afePwrWireDelta_01_8 : 0|16@1+ (0.01,0) [0|655.34] "V"  HVESP01
 SG_ HVESP01_afePwrWireDelta_02_8 : 16|16@1+ (0.01,0) [0|655.34] "V"  HVESP01
 SG_ HVESP01_afePwrWireDelta_03_8 : 32|16@1+ (0.01,0) [0|655.34] "V"  HVESP01
 SG_ HVESP01_afePwrWireDelta_04_8 : 48|16@1+ (0.01,0) [0|655.34] "V"  HVESP01

BO_ 2499753829 HVESP01_AfePwrWireDelta_05_08_1: 8 HVESP01
 SG_ HVESP01_afePwrWireDelta_05_1 : 0|16@1+ (0.01,0) [0|655.34] "V"  HVESP01
 SG_ HVESP01_afePwrWireDelta_06_1 : 16|16@1+ (0.01,0) [0|655.34] "V"  HVESP01
 SG_ HVESP01_afePwrWireDelta_07_1 : 32|16@1+ (0.01,0) [0|655.34] "V"  HVESP01
 SG_ HVESP01_afePwrWireDelta_08_1 : 48|16@1+ (0.01,0) [0|655.34] "V"  HVESP01

BO_ 2499753830 HVESP01_AfePwrWireDelta_05_08_2: 8 HVESP01
 SG_ HVESP01_afePwrWireDelta_05_2 : 0|16@1+ (0.01,0) [0|655.34] "V"  HVESP01
 SG_ HVESP01_afePwrWireDelta_06_2 : 16|16@1+ (0.01,0) [0|655.34] "V"  HVESP01
 SG_ HVESP01_afePwrWireDelta_07_2 : 32|16@1+ (0.01,0) [0|655.34] "V"  HVESP01
 SG_ HVESP01_afePwrWireDelta_08_2 : 48|16@1+ (0.01,0) [0|655.34] "V"  HVESP01

BO_ 2499753831 HVESP01_AfePwrWireDelta_05_08_3: 8 HVESP01
 SG_ HVESP01_afePwrWireDelta_05_3 : 0|16@1+ (0.01,0) [0|655.34] "V"  HVESP01
 SG_ HVESP01_afePwrWireDelta_06_3 : 16|16@1+ (0.01,0) [0|655.34] "V"  HVESP01
 SG_ HVESP01_afePwrWireDelta_07_3 : 32|16@1+ (0.01,0) [0|655.34] "V"  HVESP01
 SG_ HVESP01_afePwrWireDelta_08_3 : 48|16@1+ (0.01,0) [0|655.34] "V"  HVESP01

BO_ 2499753832 HVESP01_AfePwrWireDelta_05_08_4: 8 HVESP01
 SG_ HVESP01_afePwrWireDelta_05_4 : 0|16@1+ (0.01,0) [0|655.34] "V"  HVESP01
 SG_ HVESP01_afePwrWireDelta_06_4 : 16|16@1+ (0.01,0) [0|655.34] "V"  HVESP01
 SG_ HVESP01_afePwrWireDelta_07_4 : 32|16@1+ (0.01,0) [0|655.34] "V"  HVESP01
 SG_ HVESP01_afePwrWireDelta_08_4 : 48|16@1+ (0.01,0) [0|655.34] "V"  HVESP01

BO_ 2499753833 HVESP01_AfePwrWireDelta_05_08_5: 8 HVESP01
 SG_ HVESP01_afePwrWireDelta_05_5 : 0|16@1+ (0.01,0) [0|655.34] "V"  HVESP01
 SG_ HVESP01_afePwrWireDelta_06_5 : 16|16@1+ (0.01,0) [0|655.34] "V"  HVESP01
 SG_ HVESP01_afePwrWireDelta_07_5 : 32|16@1+ (0.01,0) [0|655.34] "V"  HVESP01
 SG_ HVESP01_afePwrWireDelta_08_5 : 48|16@1+ (0.01,0) [0|655.34] "V"  HVESP01

BO_ 2499753834 HVESP01_AfePwrWireDelta_05_08_6: 8 HVESP01
 SG_ HVESP01_afePwrWireDelta_05_6 : 0|16@1+ (0.01,0) [0|655.34] "V"  HVESP01
 SG_ HVESP01_afePwrWireDelta_06_6 : 16|16@1+ (0.01,0) [0|655.34] "V"  HVESP01
 SG_ HVESP01_afePwrWireDelta_07_6 : 32|16@1+ (0.01,0) [0|655.34] "V"  HVESP01
 SG_ HVESP01_afePwrWireDelta_08_6 : 48|16@1+ (0.01,0) [0|655.34] "V"  HVESP01

BO_ 2499753835 HVESP01_AfePwrWireDelta_05_08_7: 8 HVESP01
 SG_ HVESP01_afePwrWireDelta_05_7 : 0|16@1+ (0.01,0) [0|655.34] "V"  HVESP01
 SG_ HVESP01_afePwrWireDelta_06_7 : 16|16@1+ (0.01,0) [0|655.34] "V"  HVESP01
 SG_ HVESP01_afePwrWireDelta_07_7 : 32|16@1+ (0.01,0) [0|655.34] "V"  HVESP01
 SG_ HVESP01_afePwrWireDelta_08_7 : 48|16@1+ (0.01,0) [0|655.34] "V"  HVESP01

BO_ 2499753836 HVESP01_AfePwrWireDelta_05_08_8: 8 HVESP01
 SG_ HVESP01_afePwrWireDelta_05_8 : 0|16@1+ (0.01,0) [0|655.34] "V"  HVESP01
 SG_ HVESP01_afePwrWireDelta_06_8 : 16|16@1+ (0.01,0) [0|655.34] "V"  HVESP01
 SG_ HVESP01_afePwrWireDelta_07_8 : 32|16@1+ (0.01,0) [0|655.34] "V"  HVESP01
 SG_ HVESP01_afePwrWireDelta_08_8 : 48|16@1+ (0.01,0) [0|655.34] "V"  HVESP01

BO_ 2499754085 HVESP01_AfePwrWireDelta_09_12_1: 8 HVESP01
 SG_ HVESP01_afePwrWireDelta_09_1 : 0|16@1+ (0.01,0) [0|655.34] "V"  HVESP01
 SG_ HVESP01_afePwrWireDelta_10_1 : 16|16@1+ (0.01,0) [0|655.34] "V"  HVESP01
 SG_ HVESP01_afePwrWireDelta_11_1 : 32|16@1+ (0.01,0) [0|655.34] "V"  HVESP01
 SG_ HVESP01_afePwrWireDelta_12_1 : 48|16@1+ (0.01,0) [0|655.34] "V"  HVESP01

BO_ 2499754086 HVESP01_AfePwrWireDelta_09_12_2: 8 HVESP01
 SG_ HVESP01_afePwrWireDelta_09_2 : 0|16@1+ (0.01,0) [0|655.34] "V"  HVESP01
 SG_ HVESP01_afePwrWireDelta_10_2 : 16|16@1+ (0.01,0) [0|655.34] "V"  HVESP01
 SG_ HVESP01_afePwrWireDelta_11_2 : 32|16@1+ (0.01,0) [0|655.34] "V"  HVESP01
 SG_ HVESP01_afePwrWireDelta_12_2 : 48|16@1+ (0.01,0) [0|655.34] "V"  HVESP01

BO_ 2499754087 HVESP01_AfePwrWireDelta_09_12_3: 8 HVESP01
 SG_ HVESP01_afePwrWireDelta_09_3 : 0|16@1+ (0.01,0) [0|655.34] "V"  HVESP01
 SG_ HVESP01_afePwrWireDelta_10_3 : 16|16@1+ (0.01,0) [0|655.34] "V"  HVESP01
 SG_ HVESP01_afePwrWireDelta_11_3 : 32|16@1+ (0.01,0) [0|655.34] "V"  HVESP01
 SG_ HVESP01_afePwrWireDelta_12_3 : 48|16@1+ (0.01,0) [0|655.34] "V"  HVESP01

BO_ 2499754088 HVESP01_AfePwrWireDelta_09_12_4: 8 HVESP01
 SG_ HVESP01_afePwrWireDelta_09_4 : 0|16@1+ (0.01,0) [0|655.34] "V"  HVESP01
 SG_ HVESP01_afePwrWireDelta_10_4 : 16|16@1+ (0.01,0) [0|655.34] "V"  HVESP01
 SG_ HVESP01_afePwrWireDelta_11_4 : 32|16@1+ (0.01,0) [0|655.34] "V"  HVESP01
 SG_ HVESP01_afePwrWireDelta_12_4 : 48|16@1+ (0.01,0) [0|655.34] "V"  HVESP01

BO_ 2499754089 HVESP01_AfePwrWireDelta_09_12_5: 8 HVESP01
 SG_ HVESP01_afePwrWireDelta_09_5 : 0|16@1+ (0.01,0) [0|655.34] "V"  HVESP01
 SG_ HVESP01_afePwrWireDelta_10_5 : 16|16@1+ (0.01,0) [0|655.34] "V"  HVESP01
 SG_ HVESP01_afePwrWireDelta_11_5 : 32|16@1+ (0.01,0) [0|655.34] "V"  HVESP01
 SG_ HVESP01_afePwrWireDelta_12_5 : 48|16@1+ (0.01,0) [0|655.34] "V"  HVESP01

BO_ 2499754090 HVESP01_AfePwrWireDelta_09_12_6: 8 HVESP01
 SG_ HVESP01_afePwrWireDelta_09_6 : 0|16@1+ (0.01,0) [0|655.34] "V"  HVESP01
 SG_ HVESP01_afePwrWireDelta_10_6 : 16|16@1+ (0.01,0) [0|655.34] "V"  HVESP01
 SG_ HVESP01_afePwrWireDelta_11_6 : 32|16@1+ (0.01,0) [0|655.34] "V"  HVESP01
 SG_ HVESP01_afePwrWireDelta_12_6 : 48|16@1+ (0.01,0) [0|655.34] "V"  HVESP01

BO_ 2499754091 HVESP01_AfePwrWireDelta_09_12_7: 8 HVESP01
 SG_ HVESP01_afePwrWireDelta_09_7 : 0|16@1+ (0.01,0) [0|655.34] "V"  HVESP01
 SG_ HVESP01_afePwrWireDelta_10_7 : 16|16@1+ (0.01,0) [0|655.34] "V"  HVESP01
 SG_ HVESP01_afePwrWireDelta_11_7 : 32|16@1+ (0.01,0) [0|655.34] "V"  HVESP01
 SG_ HVESP01_afePwrWireDelta_12_7 : 48|16@1+ (0.01,0) [0|655.34] "V"  HVESP01

BO_ 2499754092 HVESP01_AfePwrWireDelta_09_12_8: 8 HVESP01
 SG_ HVESP01_afePwrWireDelta_09_8 : 0|16@1+ (0.01,0) [0|655.34] "V"  HVESP01
 SG_ HVESP01_afePwrWireDelta_10_8 : 16|16@1+ (0.01,0) [0|655.34] "V"  HVESP01
 SG_ HVESP01_afePwrWireDelta_11_8 : 32|16@1+ (0.01,0) [0|655.34] "V"  HVESP01
 SG_ HVESP01_afePwrWireDelta_12_8 : 48|16@1+ (0.01,0) [0|655.34] "V"  HVESP01

BO_ 2499754341 HVESP01_AfePwrWireDelta_13_16_1: 8 HVESP01
 SG_ HVESP01_afePwrWireDelta_13_1 : 0|16@1+ (0.01,0) [0|655.34] "V"  HVESP01
 SG_ HVESP01_afePwrWireDelta_14_1 : 16|16@1+ (0.01,0) [0|655.34] "V"  HVESP01
 SG_ HVESP01_afePwrWireDelta_15_1 : 32|16@1+ (0.01,0) [0|655.34] "V"  HVESP01
 SG_ HVESP01_afePwrWireDelta_16_1 : 48|16@1+ (0.01,0) [0|655.34] "V"  HVESP01

BO_ 2499754342 HVESP01_AfePwrWireDelta_13_16_2: 8 HVESP01
 SG_ HVESP01_afePwrWireDelta_13_2 : 0|16@1+ (0.01,0) [0|655.34] "V"  HVESP01
 SG_ HVESP01_afePwrWireDelta_14_2 : 16|16@1+ (0.01,0) [0|655.34] "V"  HVESP01
 SG_ HVESP01_afePwrWireDelta_15_2 : 32|16@1+ (0.01,0) [0|655.34] "V"  HVESP01
 SG_ HVESP01_afePwrWireDelta_16_2 : 48|16@1+ (0.01,0) [0|655.34] "V"  HVESP01

BO_ 2499754343 HVESP01_AfePwrWireDelta_13_16_3: 8 HVESP01
 SG_ HVESP01_afePwrWireDelta_13_3 : 0|16@1+ (0.01,0) [0|655.34] "V"  HVESP01
 SG_ HVESP01_afePwrWireDelta_14_3 : 16|16@1+ (0.01,0) [0|655.34] "V"  HVESP01
 SG_ HVESP01_afePwrWireDelta_15_3 : 32|16@1+ (0.01,0) [0|655.34] "V"  HVESP01
 SG_ HVESP01_afePwrWireDelta_16_3 : 48|16@1+ (0.01,0) [0|655.34] "V"  HVESP01

BO_ 2499754344 HVESP01_AfePwrWireDelta_13_16_4: 8 HVESP01
 SG_ HVESP01_afePwrWireDelta_13_4 : 0|16@1+ (0.01,0) [0|655.34] "V"  HVESP01
 SG_ HVESP01_afePwrWireDelta_14_4 : 16|16@1+ (0.01,0) [0|655.34] "V"  HVESP01
 SG_ HVESP01_afePwrWireDelta_15_4 : 32|16@1+ (0.01,0) [0|655.34] "V"  HVESP01
 SG_ HVESP01_afePwrWireDelta_16_4 : 48|16@1+ (0.01,0) [0|655.34] "V"  HVESP01

BO_ 2499754345 HVESP01_AfePwrWireDelta_13_16_5: 8 HVESP01
 SG_ HVESP01_afePwrWireDelta_13_5 : 0|16@1+ (0.01,0) [0|655.34] "V"  HVESP01
 SG_ HVESP01_afePwrWireDelta_14_5 : 16|16@1+ (0.01,0) [0|655.34] "V"  HVESP01
 SG_ HVESP01_afePwrWireDelta_15_5 : 32|16@1+ (0.01,0) [0|655.34] "V"  HVESP01
 SG_ HVESP01_afePwrWireDelta_16_5 : 48|16@1+ (0.01,0) [0|655.34] "V"  HVESP01

BO_ 2499754346 HVESP01_AfePwrWireDelta_13_16_6: 8 HVESP01
 SG_ HVESP01_afePwrWireDelta_13_6 : 0|16@1+ (0.01,0) [0|655.34] "V"  HVESP01
 SG_ HVESP01_afePwrWireDelta_14_6 : 16|16@1+ (0.01,0) [0|655.34] "V"  HVESP01
 SG_ HVESP01_afePwrWireDelta_15_6 : 32|16@1+ (0.01,0) [0|655.34] "V"  HVESP01
 SG_ HVESP01_afePwrWireDelta_16_6 : 48|16@1+ (0.01,0) [0|655.34] "V"  HVESP01

BO_ 2499754347 HVESP01_AfePwrWireDelta_13_16_7: 8 HVESP01
 SG_ HVESP01_afePwrWireDelta_13_7 : 0|16@1+ (0.01,0) [0|655.34] "V"  HVESP01
 SG_ HVESP01_afePwrWireDelta_14_7 : 16|16@1+ (0.01,0) [0|655.34] "V"  HVESP01
 SG_ HVESP01_afePwrWireDelta_15_7 : 32|16@1+ (0.01,0) [0|655.34] "V"  HVESP01
 SG_ HVESP01_afePwrWireDelta_16_7 : 48|16@1+ (0.01,0) [0|655.34] "V"  HVESP01

BO_ 2499754348 HVESP01_AfePwrWireDelta_13_16_8: 8 HVESP01
 SG_ HVESP01_afePwrWireDelta_13_8 : 0|16@1+ (0.01,0) [0|655.34] "V"  HVESP01
 SG_ HVESP01_afePwrWireDelta_14_8 : 16|16@1+ (0.01,0) [0|655.34] "V"  HVESP01
 SG_ HVESP01_afePwrWireDelta_15_8 : 32|16@1+ (0.01,0) [0|655.34] "V"  HVESP01
 SG_ HVESP01_afePwrWireDelta_16_8 : 48|16@1+ (0.01,0) [0|655.34] "V"  HVESP01

BO_ 2499754597 HVESP01_AfePwrWireDelta_17_20_1: 8 HVESP01
 SG_ HVESP01_afePwrWireDelta_17_1 : 0|16@1+ (0.01,0) [0|655.34] "V"  HVESP01
 SG_ HVESP01_afePwrWireDelta_18_1 : 16|16@1+ (0.01,0) [0|655.34] "V"  HVESP01
 SG_ HVESP01_afePwrWireDelta_19_1 : 32|16@1+ (0.01,0) [0|655.34] "V"  HVESP01
 SG_ HVESP01_afePwrWireDelta_20_1 : 48|16@1+ (0.01,0) [0|655.34] "V"  HVESP01

BO_ 2499754598 HVESP01_AfePwrWireDelta_17_20_2: 8 HVESP01
 SG_ HVESP01_afePwrWireDelta_17_2 : 0|16@1+ (0.01,0) [0|655.34] "V"  HVESP01
 SG_ HVESP01_afePwrWireDelta_18_2 : 16|16@1+ (0.01,0) [0|655.34] "V"  HVESP01
 SG_ HVESP01_afePwrWireDelta_19_2 : 32|16@1+ (0.01,0) [0|655.34] "V"  HVESP01
 SG_ HVESP01_afePwrWireDelta_20_2 : 48|16@1+ (0.01,0) [0|655.34] "V"  HVESP01

BO_ 2499754599 HVESP01_AfePwrWireDelta_17_20_3: 8 HVESP01
 SG_ HVESP01_afePwrWireDelta_17_3 : 0|16@1+ (0.01,0) [0|655.34] "V"  HVESP01
 SG_ HVESP01_afePwrWireDelta_18_3 : 16|16@1+ (0.01,0) [0|655.34] "V"  HVESP01
 SG_ HVESP01_afePwrWireDelta_19_3 : 32|16@1+ (0.01,0) [0|655.34] "V"  HVESP01
 SG_ HVESP01_afePwrWireDelta_20_3 : 48|16@1+ (0.01,0) [0|655.34] "V"  HVESP01

BO_ 2499754600 HVESP01_AfePwrWireDelta_17_20_4: 8 HVESP01
 SG_ HVESP01_afePwrWireDelta_17_4 : 0|16@1+ (0.01,0) [0|655.34] "V"  HVESP01
 SG_ HVESP01_afePwrWireDelta_18_4 : 16|16@1+ (0.01,0) [0|655.34] "V"  HVESP01
 SG_ HVESP01_afePwrWireDelta_19_4 : 32|16@1+ (0.01,0) [0|655.34] "V"  HVESP01
 SG_ HVESP01_afePwrWireDelta_20_4 : 48|16@1+ (0.01,0) [0|655.34] "V"  HVESP01

BO_ 2499754601 HVESP01_AfePwrWireDelta_17_20_5: 8 HVESP01
 SG_ HVESP01_afePwrWireDelta_17_5 : 0|16@1+ (0.01,0) [0|655.34] "V"  HVESP01
 SG_ HVESP01_afePwrWireDelta_18_5 : 16|16@1+ (0.01,0) [0|655.34] "V"  HVESP01
 SG_ HVESP01_afePwrWireDelta_19_5 : 32|16@1+ (0.01,0) [0|655.34] "V"  HVESP01
 SG_ HVESP01_afePwrWireDelta_20_5 : 48|16@1+ (0.01,0) [0|655.34] "V"  HVESP01

BO_ 2499754602 HVESP01_AfePwrWireDelta_17_20_6: 8 HVESP01
 SG_ HVESP01_afePwrWireDelta_17_6 : 0|16@1+ (0.01,0) [0|655.34] "V"  HVESP01
 SG_ HVESP01_afePwrWireDelta_18_6 : 16|16@1+ (0.01,0) [0|655.34] "V"  HVESP01
 SG_ HVESP01_afePwrWireDelta_19_6 : 32|16@1+ (0.01,0) [0|655.34] "V"  HVESP01
 SG_ HVESP01_afePwrWireDelta_20_6 : 48|16@1+ (0.01,0) [0|655.34] "V"  HVESP01

BO_ 2499754603 HVESP01_AfePwrWireDelta_17_20_7: 8 HVESP01
 SG_ HVESP01_afePwrWireDelta_17_7 : 0|16@1+ (0.01,0) [0|655.34] "V"  HVESP01
 SG_ HVESP01_afePwrWireDelta_18_7 : 16|16@1+ (0.01,0) [0|655.34] "V"  HVESP01
 SG_ HVESP01_afePwrWireDelta_19_7 : 32|16@1+ (0.01,0) [0|655.34] "V"  HVESP01
 SG_ HVESP01_afePwrWireDelta_20_7 : 48|16@1+ (0.01,0) [0|655.34] "V"  HVESP01

BO_ 2499754604 HVESP01_AfePwrWireDelta_17_20_8: 8 HVESP01
 SG_ HVESP01_afePwrWireDelta_17_8 : 0|16@1+ (0.01,0) [0|655.34] "V"  HVESP01
 SG_ HVESP01_afePwrWireDelta_18_8 : 16|16@1+ (0.01,0) [0|655.34] "V"  HVESP01
 SG_ HVESP01_afePwrWireDelta_19_8 : 32|16@1+ (0.01,0) [0|655.34] "V"  HVESP01
 SG_ HVESP01_afePwrWireDelta_20_8 : 48|16@1+ (0.01,0) [0|655.34] "V"  HVESP01

BO_ 2499754853 HVESP01_AfePwrWireDelta_21_22_1: 8 HVESP01
 SG_ HVESP01_afePwrWireDelta_21_1 : 0|16@1+ (0.01,0) [0|655.34] "V"  HVESP01
 SG_ HVESP01_afePwrWireDelta_22_1 : 16|16@1+ (0.01,0) [0|655.34] "V"  HVESP01

BO_ 2499754854 HVESP01_AfePwrWireDelta_21_22_2: 8 HVESP01
 SG_ HVESP01_afePwrWireDelta_21_2 : 0|16@1+ (0.01,0) [0|655.34] "V"  HVESP01
 SG_ HVESP01_afePwrWireDelta_22_2 : 16|16@1+ (0.01,0) [0|655.34] "V"  HVESP01

BO_ 2499754855 HVESP01_AfePwrWireDelta_21_22_3: 8 HVESP01
 SG_ HVESP01_afePwrWireDelta_21_3 : 0|16@1+ (0.01,0) [0|655.34] "V"  HVESP01
 SG_ HVESP01_afePwrWireDelta_22_3 : 16|16@1+ (0.01,0) [0|655.34] "V"  HVESP01

BO_ 2499754856 HVESP01_AfePwrWireDelta_21_22_4: 8 HVESP01
 SG_ HVESP01_afePwrWireDelta_21_4 : 0|16@1+ (0.01,0) [0|655.34] "V"  HVESP01
 SG_ HVESP01_afePwrWireDelta_22_4 : 16|16@1+ (0.01,0) [0|655.34] "V"  HVESP01

BO_ 2499754857 HVESP01_AfePwrWireDelta_21_22_5: 8 HVESP01
 SG_ HVESP01_afePwrWireDelta_21_5 : 0|16@1+ (0.01,0) [0|655.34] "V"  HVESP01
 SG_ HVESP01_afePwrWireDelta_22_5 : 16|16@1+ (0.01,0) [0|655.34] "V"  HVESP01

BO_ 2499754858 HVESP01_AfePwrWireDelta_21_22_6: 8 HVESP01
 SG_ HVESP01_afePwrWireDelta_21_6 : 0|16@1+ (0.01,0) [0|655.34] "V"  HVESP01
 SG_ HVESP01_afePwrWireDelta_22_6 : 16|16@1+ (0.01,0) [0|655.34] "V"  HVESP01

BO_ 2499754859 HVESP01_AfePwrWireDelta_21_22_7: 8 HVESP01
 SG_ HVESP01_afePwrWireDelta_21_7 : 0|16@1+ (0.01,0) [0|655.34] "V"  HVESP01
 SG_ HVESP01_afePwrWireDelta_22_7 : 16|16@1+ (0.01,0) [0|655.34] "V"  HVESP01

BO_ 2499754860 HVESP01_AfePwrWireDelta_21_22_8: 8 HVESP01
 SG_ HVESP01_afePwrWireDelta_21_8 : 0|16@1+ (0.01,0) [0|655.34] "V"  HVESP01
 SG_ HVESP01_afePwrWireDelta_22_8 : 16|16@1+ (0.01,0) [0|655.34] "V"  HVESP01

CM_ BO_ 2499764325 "EU battery passport; cyclic 1000 ms; CAN ID 0x14FF6065; 500 kbit/s.";
CM_ SG_ 2499764325 HVESP01_DPP_Pack_ID_1 "One-based battery pack identifier (1-8); used by the speaker as the receive-array index.";
CM_ SG_ 2499764325 HVESP01_DPP_Data_ID_1 "1=Battery life status;  2=Battery capacity;  3-7=SOC history;  8-10=power capability;  11=charge/discharge count; 12-17=temperature history;  18=deep-discharge event count;  19=overcharge event count;  20=post-event status.";
CM_ SG_ 2499764325 HVESP01_DPP_Data_Value_1 "Raw value selected by Data_ID. See PASSPORT_DATA_ID_MAPPING for encoding and units. IDs 8-10 use 0.1 W/bit; other IDs use factor 1. All offsets are 0. Upper bits for values shorter than 32 bits are unspecified.";
CM_ SG_ 2499764325 HVESP01_DPP_Message_Counter_1 "Incremented per pack frame; rolls over 255 to 0.";
CM_ SG_ 2499764325 HVESP01_DPP_Data_Status_1 "0=Valid; 1=Invalid / not available.";
CM_ BO_ 2499764581 "EU battery passport; cyclic 1000 ms; CAN ID 0x14FF6165; 500 kbit/s.";
CM_ SG_ 2499764581 HVESP01_DPP_Pack_ID_1 "One-based battery pack identifier (1 to 8).";
CM_ SG_ 2499764581 HVESP01_Segment_ID_1 "Cumulative byte count for a 64-byte DPP ID: 6, 12, ..., 60, 64. Ten chunks carry six bytes and the final chunk carries four bytes; restart from the first chunk for the next transfer.";
CM_ SG_ 2499764581 HVESP01_DPP_Info_1 "Up to six DPP ID bytes in payload bytes 2-7. Identifier length is exactly 64 bytes. The final chunk contains four ID bytes followed by two zero padding bytes. No terminator is transmitted.";
CM_ BO_ 2499764326 "EU battery passport; cyclic 1000 ms; CAN ID 0x14FF6066; 500 kbit/s.";
CM_ SG_ 2499764326 HVESP01_DPP_Pack_ID_2 "One-based battery pack identifier (1-8); used by the speaker as the receive-array index.";
CM_ SG_ 2499764326 HVESP01_DPP_Data_ID_2 "1=Battery life status;  2=Battery capacity;  3-7=SOC history;  8-10=power capability;  11=charge/discharge count; 12-17=temperature history;  18=deep-discharge event count;  19=overcharge event count;  20=post-event status.";
CM_ SG_ 2499764326 HVESP01_DPP_Data_Value_2 "Raw value selected by Data_ID. See PASSPORT_DATA_ID_MAPPING for encoding and units. IDs 8-10 use 0.1 W/bit; other IDs use factor 1. All offsets are 0. Upper bits for values shorter than 32 bits are unspecified.";
CM_ SG_ 2499764326 HVESP01_DPP_Message_Counter_2 "Incremented per pack frame; rolls over 255 to 0.";
CM_ SG_ 2499764326 HVESP01_DPP_Data_Status_2 "0=Valid; 1=Invalid / not available.";
CM_ BO_ 2499764582 "EU battery passport; cyclic 1000 ms; CAN ID 0x14FF6166; 500 kbit/s.";
CM_ SG_ 2499764582 HVESP01_DPP_Pack_ID_2 "One-based battery pack identifier (1 to 8).";
CM_ SG_ 2499764582 HVESP01_Segment_ID_2 "Cumulative byte count for a 64-byte DPP ID: 6, 12, ..., 60, 64. Ten chunks carry six bytes and the final chunk carries four bytes; restart from the first chunk for the next transfer.";
CM_ SG_ 2499764582 HVESP01_DPP_Info_2 "Up to six DPP ID bytes in payload bytes 2-7. Identifier length is exactly 64 bytes. The final chunk contains four ID bytes followed by two zero padding bytes. No terminator is transmitted.";
CM_ BO_ 2499764327 "EU battery passport; cyclic 1000 ms; CAN ID 0x14FF6067; 500 kbit/s.";
CM_ SG_ 2499764327 HVESP01_DPP_Pack_ID_3 "One-based battery pack identifier (1-8); used by the speaker as the receive-array index.";
CM_ SG_ 2499764327 HVESP01_DPP_Data_ID_3 "1=Battery life status;  2=Battery capacity;  3-7=SOC history;  8-10=power capability;  11=charge/discharge count; 12-17=temperature history;  18=deep-discharge event count;  19=overcharge event count;  20=post-event status.";
CM_ SG_ 2499764327 HVESP01_DPP_Data_Value_3 "Raw value selected by Data_ID. See PASSPORT_DATA_ID_MAPPING for encoding and units. IDs 8-10 use 0.1 W/bit; other IDs use factor 1. All offsets are 0. Upper bits for values shorter than 32 bits are unspecified.";
CM_ SG_ 2499764327 HVESP01_DPP_Message_Counter_3 "Incremented per pack frame; rolls over 255 to 0.";
CM_ SG_ 2499764327 HVESP01_DPP_Data_Status_3 "0=Valid; 1=Invalid / not available.";
CM_ BO_ 2499764583 "EU battery passport; cyclic 1000 ms; CAN ID 0x14FF6167; 500 kbit/s.";
CM_ SG_ 2499764583 HVESP01_DPP_Pack_ID_3 "One-based battery pack identifier (1 to 8).";
CM_ SG_ 2499764583 HVESP01_Segment_ID_3 "Cumulative byte count for a 64-byte DPP ID: 6, 12, ..., 60, 64. Ten chunks carry six bytes and the final chunk carries four bytes; restart from the first chunk for the next transfer.";
CM_ SG_ 2499764583 HVESP01_DPP_Info_3 "Up to six DPP ID bytes in payload bytes 2-7. Identifier length is exactly 64 bytes. The final chunk contains four ID bytes followed by two zero padding bytes. No terminator is transmitted.";
CM_ BO_ 2499764328 "EU battery passport; cyclic 1000 ms; CAN ID 0x14FF6068; 500 kbit/s.";
CM_ SG_ 2499764328 HVESP01_DPP_Pack_ID_4 "One-based battery pack identifier (1-8); used by the speaker as the receive-array index.";
CM_ SG_ 2499764328 HVESP01_DPP_Data_ID_4 "1=Battery life status;  2=Battery capacity;  3-7=SOC history;  8-10=power capability;  11=charge/discharge count; 12-17=temperature history;  18=deep-discharge event count;  19=overcharge event count;  20=post-event status.";
CM_ SG_ 2499764328 HVESP01_DPP_Data_Value_4 "Raw value selected by Data_ID. See PASSPORT_DATA_ID_MAPPING for encoding and units. IDs 8-10 use 0.1 W/bit; other IDs use factor 1. All offsets are 0. Upper bits for values shorter than 32 bits are unspecified.";
CM_ SG_ 2499764328 HVESP01_DPP_Message_Counter_4 "Incremented per pack frame; rolls over 255 to 0.";
CM_ SG_ 2499764328 HVESP01_DPP_Data_Status_4 "0=Valid; 1=Invalid / not available.";
CM_ BO_ 2499764584 "EU battery passport; cyclic 1000 ms; CAN ID 0x14FF6168; 500 kbit/s.";
CM_ SG_ 2499764584 HVESP01_DPP_Pack_ID_4 "One-based battery pack identifier (1 to 8).";
CM_ SG_ 2499764584 HVESP01_Segment_ID_4 "Cumulative byte count for a 64-byte DPP ID: 6, 12, ..., 60, 64. Ten chunks carry six bytes and the final chunk carries four bytes; restart from the first chunk for the next transfer.";
CM_ SG_ 2499764584 HVESP01_DPP_Info_4 "Up to six DPP ID bytes in payload bytes 2-7. Identifier length is exactly 64 bytes. The final chunk contains four ID bytes followed by two zero padding bytes. No terminator is transmitted.";
CM_ BO_ 2499764329 "EU battery passport; cyclic 1000 ms; CAN ID 0x14FF6069; 500 kbit/s.";
CM_ BO_ 2499764330 "EU battery passport; cyclic 1000 ms; CAN ID 0x14FF6069; 500 kbit/s.";
CM_ BO_ 2499764331 "EU battery passport; cyclic 1000 ms; CAN ID 0x14FF6069; 500 kbit/s.";
CM_ BO_ 2499764332 "EU battery passport; cyclic 1000 ms; CAN ID 0x14FF6069; 500 kbit/s.";
CM_ SG_ 2499764329 HVESP01_DPP_Pack_ID_5 "One-based battery pack identifier (1-8); used by the speaker as the receive-array index.";
CM_ SG_ 2499764330 HVESP01_DPP_Pack_ID_6 "One-based battery pack identifier (1-8); used by the speaker as the receive-array index.";
CM_ SG_ 2499764331 HVESP01_DPP_Pack_ID_7 "One-based battery pack identifier (1-8); used by the speaker as the receive-array index.";
CM_ SG_ 2499764332 HVESP01_DPP_Pack_ID_8 "One-based battery pack identifier (1-8); used by the speaker as the receive-array index.";
CM_ SG_ 2499764329 HVESP01_DPP_Data_ID_5 "1=Battery life status;  2=Battery capacity;  3-7=SOC history;  8-10=power capability;  11=charge/discharge count; 12-17=temperature history;  18=deep-discharge event count;  19=overcharge event count;  20=post-event status.";
CM_ SG_ 2499764330 HVESP01_DPP_Data_ID_6 "1=Battery life status;  2=Battery capacity;  3-7=SOC history;  8-10=power capability;  11=charge/discharge count; 12-17=temperature history;  18=deep-discharge event count;  19=overcharge event count;  20=post-event status.";
CM_ SG_ 2499764331 HVESP01_DPP_Data_ID_7 "1=Battery life status;  2=Battery capacity;  3-7=SOC history;  8-10=power capability;  11=charge/discharge count; 12-17=temperature history;  18=deep-discharge event count;  19=overcharge event count;  20=post-event status.";
CM_ SG_ 2499764332 HVESP01_DPP_Data_ID_8 "1=Battery life status;  2=Battery capacity;  3-7=SOC history;  8-10=power capability;  11=charge/discharge count; 12-17=temperature history;  18=deep-discharge event count;  19=overcharge event count;  20=post-event status.";
CM_ SG_ 2499764329 HVESP01_DPP_Data_Value_5 "Raw value selected by Data_ID. See PASSPORT_DATA_ID_MAPPING for encoding and units. IDs 8-10 use 0.1 W/bit; other IDs use factor 1. All offsets are 0. Upper bits for values shorter than 32 bits are unspecified.";
CM_ SG_ 2499764330 HVESP01_DPP_Data_Value_6 "Raw value selected by Data_ID. See PASSPORT_DATA_ID_MAPPING for encoding and units. IDs 8-10 use 0.1 W/bit; other IDs use factor 1. All offsets are 0. Upper bits for values shorter than 32 bits are unspecified.";
CM_ SG_ 2499764331 HVESP01_DPP_Data_Value_7 "Raw value selected by Data_ID. See PASSPORT_DATA_ID_MAPPING for encoding and units. IDs 8-10 use 0.1 W/bit; other IDs use factor 1. All offsets are 0. Upper bits for values shorter than 32 bits are unspecified.";
CM_ SG_ 2499764332 HVESP01_DPP_Data_Value_8 "Raw value selected by Data_ID. See PASSPORT_DATA_ID_MAPPING for encoding and units. IDs 8-10 use 0.1 W/bit; other IDs use factor 1. All offsets are 0. Upper bits for values shorter than 32 bits are unspecified.";
CM_ SG_ 2499764329 HVESP01_DPP_Message_Counter_5 "Incremented per pack frame; rolls over 255 to 0.";
CM_ SG_ 2499764330 HVESP01_DPP_Message_Counter_6 "Incremented per pack frame; rolls over 255 to 0.";
CM_ SG_ 2499764331 HVESP01_DPP_Message_Counter_7 "Incremented per pack frame; rolls over 255 to 0.";
CM_ SG_ 2499764332 HVESP01_DPP_Message_Counter_8 "Incremented per pack frame; rolls over 255 to 0.";
CM_ SG_ 2499764329 HVESP01_DPP_Data_Status_5 "0=Valid; 1=Invalid / not available.";
CM_ SG_ 2499764330 HVESP01_DPP_Data_Status_6 "0=Valid; 1=Invalid / not available.";
CM_ SG_ 2499764331 HVESP01_DPP_Data_Status_7 "0=Valid; 1=Invalid / not available.";
CM_ SG_ 2499764332 HVESP01_DPP_Data_Status_8 "0=Valid; 1=Invalid / not available.";
CM_ BO_ 2499764585 "EU battery passport; cyclic 1000 ms; CAN ID 0x14FF6169; 500 kbit/s.";
CM_ BO_ 2499764586 "EU battery passport; cyclic 1000 ms; CAN ID 0x14FF6169; 500 kbit/s.";
CM_ BO_ 2499764587 "EU battery passport; cyclic 1000 ms; CAN ID 0x14FF6169; 500 kbit/s.";
CM_ BO_ 2499764588 "EU battery passport; cyclic 1000 ms; CAN ID 0x14FF6169; 500 kbit/s.";
CM_ SG_ 2499764585 HVESP01_DPP_Pack_ID_5 "One-based battery pack identifier (1 to 8).";
CM_ SG_ 2499764586 HVESP01_DPP_Pack_ID_6 "One-based battery pack identifier (1 to 8).";
CM_ SG_ 2499764587 HVESP01_DPP_Pack_ID_7 "One-based battery pack identifier (1 to 8).";
CM_ SG_ 2499764588 HVESP01_DPP_Pack_ID_8 "One-based battery pack identifier (1 to 8).";
CM_ SG_ 2499764585 HVESP01_Segment_ID_5 "Cumulative byte count for a 64-byte DPP ID: 6, 12, ..., 60, 64. Ten chunks carry six bytes and the final chunk carries four bytes; restart from the first chunk for the next transfer.";
CM_ SG_ 2499764586 HVESP01_Segment_ID_6 "Cumulative byte count for a 64-byte DPP ID: 6, 12, ..., 60, 64. Ten chunks carry six bytes and the final chunk carries four bytes; restart from the first chunk for the next transfer.";
CM_ SG_ 2499764587 HVESP01_Segment_ID_7 "Cumulative byte count for a 64-byte DPP ID: 6, 12, ..., 60, 64. Ten chunks carry six bytes and the final chunk carries four bytes; restart from the first chunk for the next transfer.";
CM_ SG_ 2499764588 HVESP01_Segment_ID_8 "Cumulative byte count for a 64-byte DPP ID: 6, 12, ..., 60, 64. Ten chunks carry six bytes and the final chunk carries four bytes; restart from the first chunk for the next transfer.";
CM_ SG_ 2499764585 HVESP01_DPP_Info_5 "Up to six DPP ID bytes in payload bytes 2-7. Identifier length is exactly 64 bytes. The final chunk contains four ID bytes followed by two zero padding bytes. No terminator is transmitted.";
CM_ SG_ 2499764586 HVESP01_DPP_Info_6 "Up to six DPP ID bytes in payload bytes 2-7. Identifier length is exactly 64 bytes. The final chunk contains four ID bytes followed by two zero padding bytes. No terminator is transmitted.";
CM_ SG_ 2499764587 HVESP01_DPP_Info_7 "Up to six DPP ID bytes in payload bytes 2-7. Identifier length is exactly 64 bytes. The final chunk contains four ID bytes followed by two zero padding bytes. No terminator is transmitted.";
CM_ SG_ 2499764588 HVESP01_DPP_Info_8 "Up to six DPP ID bytes in payload bytes 2-7. Identifier length is exactly 64 bytes. The final chunk contains four ID bytes followed by two zero padding bytes. No terminator is transmitted.";
CM_ BO_ 2499750501 "AFE V+ total voltage, modules 01-04; pack instance 1; 0xFFFF encodes unavailable.";
CM_ BO_ 2499750502 "AFE V+ total voltage, modules 01-04; pack instance 2; 0xFFFF encodes unavailable.";
CM_ BO_ 2499750503 "AFE V+ total voltage, modules 01-04; pack instance 3; 0xFFFF encodes unavailable.";
CM_ BO_ 2499750504 "AFE V+ total voltage, modules 01-04; pack instance 4; 0xFFFF encodes unavailable.";
CM_ BO_ 2499750505 "AFE V+ total voltage, modules 01-04; pack instance 5; 0xFFFF encodes unavailable.";
CM_ BO_ 2499750506 "AFE V+ total voltage, modules 01-04; pack instance 6; 0xFFFF encodes unavailable.";
CM_ BO_ 2499750507 "AFE V+ total voltage, modules 01-04; pack instance 7; 0xFFFF encodes unavailable.";
CM_ BO_ 2499750508 "AFE V+ total voltage, modules 01-04; pack instance 8; 0xFFFF encodes unavailable.";
CM_ BO_ 2499750757 "AFE V+ total voltage, modules 05-08; pack instance 1; 0xFFFF encodes unavailable.";
CM_ BO_ 2499750758 "AFE V+ total voltage, modules 05-08; pack instance 2; 0xFFFF encodes unavailable.";
CM_ BO_ 2499750759 "AFE V+ total voltage, modules 05-08; pack instance 3; 0xFFFF encodes unavailable.";
CM_ BO_ 2499750760 "AFE V+ total voltage, modules 05-08; pack instance 4; 0xFFFF encodes unavailable.";
CM_ BO_ 2499750761 "AFE V+ total voltage, modules 05-08; pack instance 5; 0xFFFF encodes unavailable.";
CM_ BO_ 2499750762 "AFE V+ total voltage, modules 05-08; pack instance 6; 0xFFFF encodes unavailable.";
CM_ BO_ 2499750763 "AFE V+ total voltage, modules 05-08; pack instance 7; 0xFFFF encodes unavailable.";
CM_ BO_ 2499750764 "AFE V+ total voltage, modules 05-08; pack instance 8; 0xFFFF encodes unavailable.";
CM_ BO_ 2499751013 "AFE V+ total voltage, modules 09-12; pack instance 1; 0xFFFF encodes unavailable.";
CM_ BO_ 2499751014 "AFE V+ total voltage, modules 09-12; pack instance 2; 0xFFFF encodes unavailable.";
CM_ BO_ 2499751015 "AFE V+ total voltage, modules 09-12; pack instance 3; 0xFFFF encodes unavailable.";
CM_ BO_ 2499751016 "AFE V+ total voltage, modules 09-12; pack instance 4; 0xFFFF encodes unavailable.";
CM_ BO_ 2499751017 "AFE V+ total voltage, modules 09-12; pack instance 5; 0xFFFF encodes unavailable.";
CM_ BO_ 2499751018 "AFE V+ total voltage, modules 09-12; pack instance 6; 0xFFFF encodes unavailable.";
CM_ BO_ 2499751019 "AFE V+ total voltage, modules 09-12; pack instance 7; 0xFFFF encodes unavailable.";
CM_ BO_ 2499751020 "AFE V+ total voltage, modules 09-12; pack instance 8; 0xFFFF encodes unavailable.";
CM_ BO_ 2499751269 "AFE V+ total voltage, modules 13-16; pack instance 1; 0xFFFF encodes unavailable.";
CM_ BO_ 2499751270 "AFE V+ total voltage, modules 13-16; pack instance 2; 0xFFFF encodes unavailable.";
CM_ BO_ 2499751271 "AFE V+ total voltage, modules 13-16; pack instance 3; 0xFFFF encodes unavailable.";
CM_ BO_ 2499751272 "AFE V+ total voltage, modules 13-16; pack instance 4; 0xFFFF encodes unavailable.";
CM_ BO_ 2499751273 "AFE V+ total voltage, modules 13-16; pack instance 5; 0xFFFF encodes unavailable.";
CM_ BO_ 2499751274 "AFE V+ total voltage, modules 13-16; pack instance 6; 0xFFFF encodes unavailable.";
CM_ BO_ 2499751275 "AFE V+ total voltage, modules 13-16; pack instance 7; 0xFFFF encodes unavailable.";
CM_ BO_ 2499751276 "AFE V+ total voltage, modules 13-16; pack instance 8; 0xFFFF encodes unavailable.";
CM_ BO_ 2499751525 "AFE V+ total voltage, modules 17-20; pack instance 1; 0xFFFF encodes unavailable.";
CM_ BO_ 2499751526 "AFE V+ total voltage, modules 17-20; pack instance 2; 0xFFFF encodes unavailable.";
CM_ BO_ 2499751527 "AFE V+ total voltage, modules 17-20; pack instance 3; 0xFFFF encodes unavailable.";
CM_ BO_ 2499751528 "AFE V+ total voltage, modules 17-20; pack instance 4; 0xFFFF encodes unavailable.";
CM_ BO_ 2499751529 "AFE V+ total voltage, modules 17-20; pack instance 5; 0xFFFF encodes unavailable.";
CM_ BO_ 2499751530 "AFE V+ total voltage, modules 17-20; pack instance 6; 0xFFFF encodes unavailable.";
CM_ BO_ 2499751531 "AFE V+ total voltage, modules 17-20; pack instance 7; 0xFFFF encodes unavailable.";
CM_ BO_ 2499751532 "AFE V+ total voltage, modules 17-20; pack instance 8; 0xFFFF encodes unavailable.";
CM_ BO_ 2499751781 "AFE V+ total voltage, modules 21-22; pack instance 1; 0xFFFF encodes unavailable.";
CM_ BO_ 2499751782 "AFE V+ total voltage, modules 21-22; pack instance 2; 0xFFFF encodes unavailable.";
CM_ BO_ 2499751783 "AFE V+ total voltage, modules 21-22; pack instance 3; 0xFFFF encodes unavailable.";
CM_ BO_ 2499751784 "AFE V+ total voltage, modules 21-22; pack instance 4; 0xFFFF encodes unavailable.";
CM_ BO_ 2499751785 "AFE V+ total voltage, modules 21-22; pack instance 5; 0xFFFF encodes unavailable.";
CM_ BO_ 2499751786 "AFE V+ total voltage, modules 21-22; pack instance 6; 0xFFFF encodes unavailable.";
CM_ BO_ 2499751787 "AFE V+ total voltage, modules 21-22; pack instance 7; 0xFFFF encodes unavailable.";
CM_ BO_ 2499751788 "AFE V+ total voltage, modules 21-22; pack instance 8; 0xFFFF encodes unavailable.";
CM_ BO_ 2499752037 "AFE module cell voltage sum, modules 01-04; pack instance 1; 0xFFFF encodes unavailable.";
CM_ BO_ 2499752038 "AFE module cell voltage sum, modules 01-04; pack instance 2; 0xFFFF encodes unavailable.";
CM_ BO_ 2499752039 "AFE module cell voltage sum, modules 01-04; pack instance 3; 0xFFFF encodes unavailable.";
CM_ BO_ 2499752040 "AFE module cell voltage sum, modules 01-04; pack instance 4; 0xFFFF encodes unavailable.";
CM_ BO_ 2499752041 "AFE module cell voltage sum, modules 01-04; pack instance 5; 0xFFFF encodes unavailable.";
CM_ BO_ 2499752042 "AFE module cell voltage sum, modules 01-04; pack instance 6; 0xFFFF encodes unavailable.";
CM_ BO_ 2499752043 "AFE module cell voltage sum, modules 01-04; pack instance 7; 0xFFFF encodes unavailable.";
CM_ BO_ 2499752044 "AFE module cell voltage sum, modules 01-04; pack instance 8; 0xFFFF encodes unavailable.";
CM_ BO_ 2499752293 "AFE module cell voltage sum, modules 05-08; pack instance 1; 0xFFFF encodes unavailable.";
CM_ BO_ 2499752294 "AFE module cell voltage sum, modules 05-08; pack instance 2; 0xFFFF encodes unavailable.";
CM_ BO_ 2499752295 "AFE module cell voltage sum, modules 05-08; pack instance 3; 0xFFFF encodes unavailable.";
CM_ BO_ 2499752296 "AFE module cell voltage sum, modules 05-08; pack instance 4; 0xFFFF encodes unavailable.";
CM_ BO_ 2499752297 "AFE module cell voltage sum, modules 05-08; pack instance 5; 0xFFFF encodes unavailable.";
CM_ BO_ 2499752298 "AFE module cell voltage sum, modules 05-08; pack instance 6; 0xFFFF encodes unavailable.";
CM_ BO_ 2499752299 "AFE module cell voltage sum, modules 05-08; pack instance 7; 0xFFFF encodes unavailable.";
CM_ BO_ 2499752300 "AFE module cell voltage sum, modules 05-08; pack instance 8; 0xFFFF encodes unavailable.";
CM_ BO_ 2499752549 "AFE module cell voltage sum, modules 09-12; pack instance 1; 0xFFFF encodes unavailable.";
CM_ BO_ 2499752550 "AFE module cell voltage sum, modules 09-12; pack instance 2; 0xFFFF encodes unavailable.";
CM_ BO_ 2499752551 "AFE module cell voltage sum, modules 09-12; pack instance 3; 0xFFFF encodes unavailable.";
CM_ BO_ 2499752552 "AFE module cell voltage sum, modules 09-12; pack instance 4; 0xFFFF encodes unavailable.";
CM_ BO_ 2499752553 "AFE module cell voltage sum, modules 09-12; pack instance 5; 0xFFFF encodes unavailable.";
CM_ BO_ 2499752554 "AFE module cell voltage sum, modules 09-12; pack instance 6; 0xFFFF encodes unavailable.";
CM_ BO_ 2499752555 "AFE module cell voltage sum, modules 09-12; pack instance 7; 0xFFFF encodes unavailable.";
CM_ BO_ 2499752556 "AFE module cell voltage sum, modules 09-12; pack instance 8; 0xFFFF encodes unavailable.";
CM_ BO_ 2499752805 "AFE module cell voltage sum, modules 13-16; pack instance 1; 0xFFFF encodes unavailable.";
CM_ BO_ 2499752806 "AFE module cell voltage sum, modules 13-16; pack instance 2; 0xFFFF encodes unavailable.";
CM_ BO_ 2499752807 "AFE module cell voltage sum, modules 13-16; pack instance 3; 0xFFFF encodes unavailable.";
CM_ BO_ 2499752808 "AFE module cell voltage sum, modules 13-16; pack instance 4; 0xFFFF encodes unavailable.";
CM_ BO_ 2499752809 "AFE module cell voltage sum, modules 13-16; pack instance 5; 0xFFFF encodes unavailable.";
CM_ BO_ 2499752810 "AFE module cell voltage sum, modules 13-16; pack instance 6; 0xFFFF encodes unavailable.";
CM_ BO_ 2499752811 "AFE module cell voltage sum, modules 13-16; pack instance 7; 0xFFFF encodes unavailable.";
CM_ BO_ 2499752812 "AFE module cell voltage sum, modules 13-16; pack instance 8; 0xFFFF encodes unavailable.";
CM_ BO_ 2499753061 "AFE module cell voltage sum, modules 17-20; pack instance 1; 0xFFFF encodes unavailable.";
CM_ BO_ 2499753062 "AFE module cell voltage sum, modules 17-20; pack instance 2; 0xFFFF encodes unavailable.";
CM_ BO_ 2499753063 "AFE module cell voltage sum, modules 17-20; pack instance 3; 0xFFFF encodes unavailable.";
CM_ BO_ 2499753064 "AFE module cell voltage sum, modules 17-20; pack instance 4; 0xFFFF encodes unavailable.";
CM_ BO_ 2499753065 "AFE module cell voltage sum, modules 17-20; pack instance 5; 0xFFFF encodes unavailable.";
CM_ BO_ 2499753066 "AFE module cell voltage sum, modules 17-20; pack instance 6; 0xFFFF encodes unavailable.";
CM_ BO_ 2499753067 "AFE module cell voltage sum, modules 17-20; pack instance 7; 0xFFFF encodes unavailable.";
CM_ BO_ 2499753068 "AFE module cell voltage sum, modules 17-20; pack instance 8; 0xFFFF encodes unavailable.";
CM_ BO_ 2499753317 "AFE module cell voltage sum, modules 21-22; pack instance 1; 0xFFFF encodes unavailable.";
CM_ BO_ 2499753318 "AFE module cell voltage sum, modules 21-22; pack instance 2; 0xFFFF encodes unavailable.";
CM_ BO_ 2499753319 "AFE module cell voltage sum, modules 21-22; pack instance 3; 0xFFFF encodes unavailable.";
CM_ BO_ 2499753320 "AFE module cell voltage sum, modules 21-22; pack instance 4; 0xFFFF encodes unavailable.";
CM_ BO_ 2499753321 "AFE module cell voltage sum, modules 21-22; pack instance 5; 0xFFFF encodes unavailable.";
CM_ BO_ 2499753322 "AFE module cell voltage sum, modules 21-22; pack instance 6; 0xFFFF encodes unavailable.";
CM_ BO_ 2499753323 "AFE module cell voltage sum, modules 21-22; pack instance 7; 0xFFFF encodes unavailable.";
CM_ BO_ 2499753324 "AFE module cell voltage sum, modules 21-22; pack instance 8; 0xFFFF encodes unavailable.";
CM_ BO_ 2499753573 "AFE module absolute voltage difference, modules 01-04; pack instance 1; 0xFFFF encodes unavailable.";
CM_ BO_ 2499753574 "AFE module absolute voltage difference, modules 01-04; pack instance 2; 0xFFFF encodes unavailable.";
CM_ BO_ 2499753575 "AFE module absolute voltage difference, modules 01-04; pack instance 3; 0xFFFF encodes unavailable.";
CM_ BO_ 2499753576 "AFE module absolute voltage difference, modules 01-04; pack instance 4; 0xFFFF encodes unavailable.";
CM_ BO_ 2499753577 "AFE module absolute voltage difference, modules 01-04; pack instance 5; 0xFFFF encodes unavailable.";
CM_ BO_ 2499753578 "AFE module absolute voltage difference, modules 01-04; pack instance 6; 0xFFFF encodes unavailable.";
CM_ BO_ 2499753579 "AFE module absolute voltage difference, modules 01-04; pack instance 7; 0xFFFF encodes unavailable.";
CM_ BO_ 2499753580 "AFE module absolute voltage difference, modules 01-04; pack instance 8; 0xFFFF encodes unavailable.";
CM_ BO_ 2499753829 "AFE module absolute voltage difference, modules 05-08; pack instance 1; 0xFFFF encodes unavailable.";
CM_ BO_ 2499753830 "AFE module absolute voltage difference, modules 05-08; pack instance 2; 0xFFFF encodes unavailable.";
CM_ BO_ 2499753831 "AFE module absolute voltage difference, modules 05-08; pack instance 3; 0xFFFF encodes unavailable.";
CM_ BO_ 2499753832 "AFE module absolute voltage difference, modules 05-08; pack instance 4; 0xFFFF encodes unavailable.";
CM_ BO_ 2499753833 "AFE module absolute voltage difference, modules 05-08; pack instance 5; 0xFFFF encodes unavailable.";
CM_ BO_ 2499753834 "AFE module absolute voltage difference, modules 05-08; pack instance 6; 0xFFFF encodes unavailable.";
CM_ BO_ 2499753835 "AFE module absolute voltage difference, modules 05-08; pack instance 7; 0xFFFF encodes unavailable.";
CM_ BO_ 2499753836 "AFE module absolute voltage difference, modules 05-08; pack instance 8; 0xFFFF encodes unavailable.";
CM_ BO_ 2499754085 "AFE module absolute voltage difference, modules 09-12; pack instance 1; 0xFFFF encodes unavailable.";
CM_ BO_ 2499754086 "AFE module absolute voltage difference, modules 09-12; pack instance 2; 0xFFFF encodes unavailable.";
CM_ BO_ 2499754087 "AFE module absolute voltage difference, modules 09-12; pack instance 3; 0xFFFF encodes unavailable.";
CM_ BO_ 2499754088 "AFE module absolute voltage difference, modules 09-12; pack instance 4; 0xFFFF encodes unavailable.";
CM_ BO_ 2499754089 "AFE module absolute voltage difference, modules 09-12; pack instance 5; 0xFFFF encodes unavailable.";
CM_ BO_ 2499754090 "AFE module absolute voltage difference, modules 09-12; pack instance 6; 0xFFFF encodes unavailable.";
CM_ BO_ 2499754091 "AFE module absolute voltage difference, modules 09-12; pack instance 7; 0xFFFF encodes unavailable.";
CM_ BO_ 2499754092 "AFE module absolute voltage difference, modules 09-12; pack instance 8; 0xFFFF encodes unavailable.";
CM_ BO_ 2499754341 "AFE module absolute voltage difference, modules 13-16; pack instance 1; 0xFFFF encodes unavailable.";
CM_ BO_ 2499754342 "AFE module absolute voltage difference, modules 13-16; pack instance 2; 0xFFFF encodes unavailable.";
CM_ BO_ 2499754343 "AFE module absolute voltage difference, modules 13-16; pack instance 3; 0xFFFF encodes unavailable.";
CM_ BO_ 2499754344 "AFE module absolute voltage difference, modules 13-16; pack instance 4; 0xFFFF encodes unavailable.";
CM_ BO_ 2499754345 "AFE module absolute voltage difference, modules 13-16; pack instance 5; 0xFFFF encodes unavailable.";
CM_ BO_ 2499754346 "AFE module absolute voltage difference, modules 13-16; pack instance 6; 0xFFFF encodes unavailable.";
CM_ BO_ 2499754347 "AFE module absolute voltage difference, modules 13-16; pack instance 7; 0xFFFF encodes unavailable.";
CM_ BO_ 2499754348 "AFE module absolute voltage difference, modules 13-16; pack instance 8; 0xFFFF encodes unavailable.";
CM_ BO_ 2499754597 "AFE module absolute voltage difference, modules 17-20; pack instance 1; 0xFFFF encodes unavailable.";
CM_ BO_ 2499754598 "AFE module absolute voltage difference, modules 17-20; pack instance 2; 0xFFFF encodes unavailable.";
CM_ BO_ 2499754599 "AFE module absolute voltage difference, modules 17-20; pack instance 3; 0xFFFF encodes unavailable.";
CM_ BO_ 2499754600 "AFE module absolute voltage difference, modules 17-20; pack instance 4; 0xFFFF encodes unavailable.";
CM_ BO_ 2499754601 "AFE module absolute voltage difference, modules 17-20; pack instance 5; 0xFFFF encodes unavailable.";
CM_ BO_ 2499754602 "AFE module absolute voltage difference, modules 17-20; pack instance 6; 0xFFFF encodes unavailable.";
CM_ BO_ 2499754603 "AFE module absolute voltage difference, modules 17-20; pack instance 7; 0xFFFF encodes unavailable.";
CM_ BO_ 2499754604 "AFE module absolute voltage difference, modules 17-20; pack instance 8; 0xFFFF encodes unavailable.";
CM_ BO_ 2499754853 "AFE module absolute voltage difference, modules 21-22; pack instance 1; 0xFFFF encodes unavailable.";
CM_ BO_ 2499754854 "AFE module absolute voltage difference, modules 21-22; pack instance 2; 0xFFFF encodes unavailable.";
CM_ BO_ 2499754855 "AFE module absolute voltage difference, modules 21-22; pack instance 3; 0xFFFF encodes unavailable.";
CM_ BO_ 2499754856 "AFE module absolute voltage difference, modules 21-22; pack instance 4; 0xFFFF encodes unavailable.";
CM_ BO_ 2499754857 "AFE module absolute voltage difference, modules 21-22; pack instance 5; 0xFFFF encodes unavailable.";
CM_ BO_ 2499754858 "AFE module absolute voltage difference, modules 21-22; pack instance 6; 0xFFFF encodes unavailable.";
CM_ BO_ 2499754859 "AFE module absolute voltage difference, modules 21-22; pack instance 7; 0xFFFF encodes unavailable.";
CM_ BO_ 2499754860 "AFE module absolute voltage difference, modules 21-22; pack instance 8; 0xFFFF encodes unavailable.";
BA_DEF_ BO_  "GenMsgDiag" ENUM  "No","Yes";
BA_DEF_ BO_  "GenMsgInstanced" STRING ;
BA_DEF_ SG_  "SigType" ENUM  "Default","Range","RangeSigned","ASCII","Discrete","Control","ReferencePGN","DTC","StringDelimiter","StringLength","StringLengthControl","MessageCounter","MessageChecksum";
BA_DEF_ SG_  "GenSigEVName" STRING ;
BA_DEF_ SG_  "GenSigILSupport" ENUM  "No","Yes";
BA_DEF_ SG_  "GenSigSendType" ENUM  "Cyclic","OnWrite","OnWriteWithRepetition","OnChange","OnChangeWithRepetition","IfActive","IfActiveWithRepetition","NoSigSendType";
BA_DEF_ SG_  "GenSigStartValue" INT 0 10000;
BA_DEF_ BO_  "GenMsgILSupport" ENUM  "No","Yes";
BA_DEF_ BO_  "GenMsgSendType" ENUM  "cyclic","NotUsed","IfActive","NotUsed","NotUsed","NotUsed","NotUsed","NotUsed","noMsgSendType";
BA_DEF_ BO_  "GenMsgRequestable" INT 0 1;
BA_DEF_ BO_  "GenMsgCycleTime" INT 0 3600000;
BA_DEF_ BO_  "VFrameFormat" ENUM  "StandardCAN","ExtendedCAN","reserved","J1939PG";
BA_DEF_ SG_  "SystemSignalLongSymbol" STRING ;
BA_DEF_ BO_  "SystemMessageLongSymbol" STRING ;
BA_DEF_DEF_  "GenMsgDiag" "No";
BA_DEF_DEF_  "GenMsgInstanced" "No";
BA_DEF_DEF_  "SigType" "Default";
BA_DEF_DEF_  "GenSigEVName" "Env@Nodename_@Signame";
BA_DEF_DEF_  "GenSigILSupport" "Yes";
BA_DEF_DEF_  "GenSigSendType" "NoSigSendType";
BA_DEF_DEF_  "GenSigStartValue" 0;
BA_DEF_DEF_  "GenMsgILSupport" "Yes";
BA_DEF_DEF_  "GenMsgSendType" "noMsgSendType";
BA_DEF_DEF_  "GenMsgRequestable" 1;
BA_DEF_DEF_  "GenMsgCycleTime" 0;
BA_DEF_DEF_  "VFrameFormat" "J1939PG";
BA_DEF_DEF_  "SystemSignalLongSymbol" "";
BA_DEF_DEF_  "SystemMessageLongSymbol" "";
BA_ "VFrameFormat" BO_ 2499750250 1;
BA_ "GenMsgInstanced" BO_ 2499750250 "False";
BA_ "GenMsgDiag" BO_ 2499750250 1;
BA_ "VFrameFormat" BO_ 2499750251 1;
BA_ "GenMsgInstanced" BO_ 2499750251 "False";
BA_ "GenMsgDiag" BO_ 2499750251 1;
BA_ "VFrameFormat" BO_ 2499750252 1;
BA_ "GenMsgInstanced" BO_ 2499750252 "False";
BA_ "GenMsgDiag" BO_ 2499750252 1;
BA_ "GenMsgCycleTime" BO_ 2499760741 1000;
BA_ "GenMsgSendType" BO_ 2499760741 0;
BA_ "GenMsgInstanced" BO_ 2499760741 "False";
BA_ "GenMsgDiag" BO_ 2499760741 1;
BA_ "GenMsgCycleTime" BO_ 2499760742 1000;
BA_ "GenMsgSendType" BO_ 2499760742 0;
BA_ "GenMsgInstanced" BO_ 2499760742 "False";
BA_ "GenMsgDiag" BO_ 2499760742 1;
BA_ "GenMsgCycleTime" BO_ 2499760743 1000;
BA_ "GenMsgSendType" BO_ 2499760743 0;
BA_ "GenMsgInstanced" BO_ 2499760743 "False";
BA_ "GenMsgDiag" BO_ 2499760743 1;
BA_ "GenMsgCycleTime" BO_ 2499760744 1000;
BA_ "GenMsgSendType" BO_ 2499760744 0;
BA_ "GenMsgInstanced" BO_ 2499760744 "False";
BA_ "GenMsgDiag" BO_ 2499760744 1;
BA_ "GenMsgCycleTime" BO_ 2499760745 1000;
BA_ "GenMsgSendType" BO_ 2499760745 0;
BA_ "GenMsgInstanced" BO_ 2499760745 "False";
BA_ "GenMsgDiag" BO_ 2499760745 1;
BA_ "GenMsgCycleTime" BO_ 2499760746 1000;
BA_ "GenMsgSendType" BO_ 2499760746 0;
BA_ "GenMsgInstanced" BO_ 2499760746 "False";
BA_ "GenMsgDiag" BO_ 2499760746 1;
BA_ "GenMsgCycleTime" BO_ 2499760747 1000;
BA_ "GenMsgSendType" BO_ 2499760747 0;
BA_ "GenMsgInstanced" BO_ 2499760747 "False";
BA_ "GenMsgDiag" BO_ 2499760747 1;
BA_ "GenMsgCycleTime" BO_ 2499760748 1000;
BA_ "GenMsgSendType" BO_ 2499760748 0;
BA_ "GenMsgInstanced" BO_ 2499760748 "False";
BA_ "GenMsgDiag" BO_ 2499760748 1;
BA_ "GenMsgCycleTime" BO_ 2499760997 1000;
BA_ "GenMsgSendType" BO_ 2499760997 0;
BA_ "GenMsgInstanced" BO_ 2499760997 "False";
BA_ "GenMsgCycleTime" BO_ 2499760998 1000;
BA_ "GenMsgSendType" BO_ 2499760998 0;
BA_ "GenMsgInstanced" BO_ 2499760998 "False";
BA_ "GenMsgCycleTime" BO_ 2499760999 1000;
BA_ "GenMsgSendType" BO_ 2499760999 0;
BA_ "GenMsgInstanced" BO_ 2499760999 "False";
BA_ "GenMsgCycleTime" BO_ 2499761000 1000;
BA_ "GenMsgSendType" BO_ 2499761000 0;
BA_ "GenMsgInstanced" BO_ 2499761000 "False";
BA_ "GenMsgCycleTime" BO_ 2499761001 1000;
BA_ "GenMsgSendType" BO_ 2499761001 0;
BA_ "GenMsgInstanced" BO_ 2499761001 "False";
BA_ "GenMsgCycleTime" BO_ 2499761002 1000;
BA_ "GenMsgSendType" BO_ 2499761002 0;
BA_ "GenMsgInstanced" BO_ 2499761002 "False";
BA_ "GenMsgCycleTime" BO_ 2499761003 1000;
BA_ "GenMsgSendType" BO_ 2499761003 0;
BA_ "GenMsgInstanced" BO_ 2499761003 "False";
BA_ "GenMsgCycleTime" BO_ 2499761004 1000;
BA_ "GenMsgSendType" BO_ 2499761004 0;
BA_ "GenMsgInstanced" BO_ 2499761004 "False";
BA_ "GenMsgCycleTime" BO_ 2499761253 100;
BA_ "GenMsgSendType" BO_ 2499761253 0;
BA_ "GenMsgInstanced" BO_ 2499761253 "False";
BA_ "GenMsgDiag" BO_ 2499761253 1;
BA_ "GenMsgCycleTime" BO_ 2499761254 100;
BA_ "GenMsgSendType" BO_ 2499761254 0;
BA_ "GenMsgInstanced" BO_ 2499761254 "False";
BA_ "GenMsgDiag" BO_ 2499761254 1;
BA_ "GenMsgCycleTime" BO_ 2499761255 100;
BA_ "GenMsgSendType" BO_ 2499761255 0;
BA_ "GenMsgInstanced" BO_ 2499761255 "False";
BA_ "GenMsgDiag" BO_ 2499761255 1;
BA_ "GenMsgCycleTime" BO_ 2499761256 100;
BA_ "GenMsgSendType" BO_ 2499761256 0;
BA_ "GenMsgInstanced" BO_ 2499761256 "False";
BA_ "GenMsgDiag" BO_ 2499761256 1;
BA_ "GenMsgCycleTime" BO_ 2499761257 100;
BA_ "GenMsgSendType" BO_ 2499761257 0;
BA_ "GenMsgInstanced" BO_ 2499761257 "False";
BA_ "GenMsgDiag" BO_ 2499761257 1;
BA_ "GenMsgCycleTime" BO_ 2499761258 100;
BA_ "GenMsgSendType" BO_ 2499761258 0;
BA_ "GenMsgInstanced" BO_ 2499761258 "False";
BA_ "GenMsgDiag" BO_ 2499761258 1;
BA_ "GenMsgCycleTime" BO_ 2499761259 100;
BA_ "GenMsgSendType" BO_ 2499761259 0;
BA_ "GenMsgInstanced" BO_ 2499761259 "False";
BA_ "GenMsgDiag" BO_ 2499761259 1;
BA_ "GenMsgCycleTime" BO_ 2499761260 100;
BA_ "GenMsgSendType" BO_ 2499761260 0;
BA_ "GenMsgInstanced" BO_ 2499761260 "False";
BA_ "GenMsgDiag" BO_ 2499761260 1;
BA_ "VFrameFormat" BO_ 2499795813 1;
BA_ "GenMsgCycleTime" BO_ 2499795813 100;
BA_ "GenMsgInstanced" BO_ 2499795813 "False";
BA_ "VFrameFormat" BO_ 2499795814 1;
BA_ "GenMsgCycleTime" BO_ 2499795814 100;
BA_ "GenMsgInstanced" BO_ 2499795814 "False";
BA_ "VFrameFormat" BO_ 2499795815 1;
BA_ "GenMsgCycleTime" BO_ 2499795815 100;
BA_ "GenMsgInstanced" BO_ 2499795815 "False";
BA_ "VFrameFormat" BO_ 2499795816 1;
BA_ "GenMsgCycleTime" BO_ 2499795816 100;
BA_ "GenMsgInstanced" BO_ 2499795816 "False";
BA_ "VFrameFormat" BO_ 2499795817 1;
BA_ "GenMsgCycleTime" BO_ 2499795817 100;
BA_ "GenMsgInstanced" BO_ 2499795817 "False";
BA_ "VFrameFormat" BO_ 2499795818 1;
BA_ "GenMsgCycleTime" BO_ 2499795818 100;
BA_ "GenMsgInstanced" BO_ 2499795818 "False";
BA_ "VFrameFormat" BO_ 2499795819 1;
BA_ "GenMsgCycleTime" BO_ 2499795819 100;
BA_ "GenMsgInstanced" BO_ 2499795819 "False";
BA_ "VFrameFormat" BO_ 2499795820 1;
BA_ "GenMsgCycleTime" BO_ 2499795820 100;
BA_ "GenMsgInstanced" BO_ 2499795820 "False";
BA_ "VFrameFormat" BO_ 2499764325 1;
BA_ "GenMsgSendType" BO_ 2499764325 0;
BA_ "VFrameFormat" BO_ 2499764581 1;
BA_ "GenMsgSendType" BO_ 2499764581 0;
BA_ "VFrameFormat" BO_ 2499764326 1;
BA_ "GenMsgSendType" BO_ 2499764326 0;
BA_ "VFrameFormat" BO_ 2499764582 1;
BA_ "GenMsgSendType" BO_ 2499764582 0;
BA_ "VFrameFormat" BO_ 2499764327 1;
BA_ "GenMsgSendType" BO_ 2499764327 0;
BA_ "VFrameFormat" BO_ 2499764583 1;
BA_ "GenMsgSendType" BO_ 2499764583 0;
BA_ "VFrameFormat" BO_ 2499764328 1;
BA_ "GenMsgSendType" BO_ 2499764328 0;
BA_ "VFrameFormat" BO_ 2499764584 1;
BA_ "GenMsgSendType" BO_ 2499764584 0;
BA_ "VFrameFormat" BO_ 2499764329 1;
BA_ "VFrameFormat" BO_ 2499764330 1;
BA_ "VFrameFormat" BO_ 2499764331 1;
BA_ "VFrameFormat" BO_ 2499764332 1;
BA_ "GenMsgSendType" BO_ 2499764329 0;
BA_ "GenMsgSendType" BO_ 2499764330 0;
BA_ "GenMsgSendType" BO_ 2499764331 0;
BA_ "GenMsgSendType" BO_ 2499764332 0;
BA_ "VFrameFormat" BO_ 2499764585 1;
BA_ "VFrameFormat" BO_ 2499764586 1;
BA_ "VFrameFormat" BO_ 2499764587 1;
BA_ "VFrameFormat" BO_ 2499764588 1;
BA_ "GenMsgSendType" BO_ 2499764585 0;
BA_ "GenMsgSendType" BO_ 2499764586 0;
BA_ "GenMsgSendType" BO_ 2499764587 0;
BA_ "GenMsgSendType" BO_ 2499764588 0;
BA_ "GenMsgSendType" BO_ 2499750501 0;
BA_ "GenMsgDiag" BO_ 2499750501 1;
BA_ "GenMsgCycleTime" BO_ 2499750501 1000;
BA_ "GenMsgSendType" BO_ 2499750502 0;
BA_ "GenMsgDiag" BO_ 2499750502 1;
BA_ "GenMsgCycleTime" BO_ 2499750502 1000;
BA_ "GenMsgSendType" BO_ 2499750503 0;
BA_ "GenMsgDiag" BO_ 2499750503 1;
BA_ "GenMsgCycleTime" BO_ 2499750503 1000;
BA_ "GenMsgSendType" BO_ 2499750504 0;
BA_ "GenMsgDiag" BO_ 2499750504 1;
BA_ "GenMsgCycleTime" BO_ 2499750504 1000;
BA_ "GenMsgSendType" BO_ 2499750505 0;
BA_ "GenMsgDiag" BO_ 2499750505 1;
BA_ "GenMsgCycleTime" BO_ 2499750505 1000;
BA_ "GenMsgSendType" BO_ 2499750506 0;
BA_ "GenMsgDiag" BO_ 2499750506 1;
BA_ "GenMsgCycleTime" BO_ 2499750506 1000;
BA_ "GenMsgSendType" BO_ 2499750507 0;
BA_ "GenMsgDiag" BO_ 2499750507 1;
BA_ "GenMsgCycleTime" BO_ 2499750507 1000;
BA_ "GenMsgSendType" BO_ 2499750508 0;
BA_ "GenMsgDiag" BO_ 2499750508 1;
BA_ "GenMsgCycleTime" BO_ 2499750508 1000;
BA_ "GenMsgSendType" BO_ 2499750757 0;
BA_ "GenMsgDiag" BO_ 2499750757 1;
BA_ "GenMsgCycleTime" BO_ 2499750757 1000;
BA_ "GenMsgSendType" BO_ 2499750758 0;
BA_ "GenMsgDiag" BO_ 2499750758 1;
BA_ "GenMsgCycleTime" BO_ 2499750758 1000;
BA_ "GenMsgSendType" BO_ 2499750759 0;
BA_ "GenMsgDiag" BO_ 2499750759 1;
BA_ "GenMsgCycleTime" BO_ 2499750759 1000;
BA_ "GenMsgSendType" BO_ 2499750760 0;
BA_ "GenMsgDiag" BO_ 2499750760 1;
BA_ "GenMsgCycleTime" BO_ 2499750760 1000;
BA_ "GenMsgSendType" BO_ 2499750761 0;
BA_ "GenMsgDiag" BO_ 2499750761 1;
BA_ "GenMsgCycleTime" BO_ 2499750761 1000;
BA_ "GenMsgSendType" BO_ 2499750762 0;
BA_ "GenMsgDiag" BO_ 2499750762 1;
BA_ "GenMsgCycleTime" BO_ 2499750762 1000;
BA_ "GenMsgSendType" BO_ 2499750763 0;
BA_ "GenMsgDiag" BO_ 2499750763 1;
BA_ "GenMsgCycleTime" BO_ 2499750763 1000;
BA_ "GenMsgSendType" BO_ 2499750764 0;
BA_ "GenMsgDiag" BO_ 2499750764 1;
BA_ "GenMsgCycleTime" BO_ 2499750764 1000;
BA_ "GenMsgSendType" BO_ 2499751013 0;
BA_ "GenMsgDiag" BO_ 2499751013 1;
BA_ "GenMsgCycleTime" BO_ 2499751013 1000;
BA_ "GenMsgSendType" BO_ 2499751014 0;
BA_ "GenMsgDiag" BO_ 2499751014 1;
BA_ "GenMsgCycleTime" BO_ 2499751014 1000;
BA_ "GenMsgSendType" BO_ 2499751015 0;
BA_ "GenMsgDiag" BO_ 2499751015 1;
BA_ "GenMsgCycleTime" BO_ 2499751015 1000;
BA_ "GenMsgSendType" BO_ 2499751016 0;
BA_ "GenMsgDiag" BO_ 2499751016 1;
BA_ "GenMsgCycleTime" BO_ 2499751016 1000;
BA_ "GenMsgSendType" BO_ 2499751017 0;
BA_ "GenMsgDiag" BO_ 2499751017 1;
BA_ "GenMsgCycleTime" BO_ 2499751017 1000;
BA_ "GenMsgSendType" BO_ 2499751018 0;
BA_ "GenMsgDiag" BO_ 2499751018 1;
BA_ "GenMsgCycleTime" BO_ 2499751018 1000;
BA_ "GenMsgSendType" BO_ 2499751019 0;
BA_ "GenMsgDiag" BO_ 2499751019 1;
BA_ "GenMsgCycleTime" BO_ 2499751019 1000;
BA_ "GenMsgSendType" BO_ 2499751020 0;
BA_ "GenMsgDiag" BO_ 2499751020 1;
BA_ "GenMsgCycleTime" BO_ 2499751020 1000;
BA_ "GenMsgSendType" BO_ 2499751269 0;
BA_ "GenMsgDiag" BO_ 2499751269 1;
BA_ "GenMsgCycleTime" BO_ 2499751269 1000;
BA_ "GenMsgSendType" BO_ 2499751270 0;
BA_ "GenMsgDiag" BO_ 2499751270 1;
BA_ "GenMsgCycleTime" BO_ 2499751270 1000;
BA_ "GenMsgSendType" BO_ 2499751271 0;
BA_ "GenMsgDiag" BO_ 2499751271 1;
BA_ "GenMsgCycleTime" BO_ 2499751271 1000;
BA_ "GenMsgSendType" BO_ 2499751272 0;
BA_ "GenMsgDiag" BO_ 2499751272 1;
BA_ "GenMsgCycleTime" BO_ 2499751272 1000;
BA_ "GenMsgSendType" BO_ 2499751273 0;
BA_ "GenMsgDiag" BO_ 2499751273 1;
BA_ "GenMsgCycleTime" BO_ 2499751273 1000;
BA_ "GenMsgSendType" BO_ 2499751274 0;
BA_ "GenMsgDiag" BO_ 2499751274 1;
BA_ "GenMsgCycleTime" BO_ 2499751274 1000;
BA_ "GenMsgSendType" BO_ 2499751275 0;
BA_ "GenMsgDiag" BO_ 2499751275 1;
BA_ "GenMsgCycleTime" BO_ 2499751275 1000;
BA_ "GenMsgSendType" BO_ 2499751276 0;
BA_ "GenMsgDiag" BO_ 2499751276 1;
BA_ "GenMsgCycleTime" BO_ 2499751276 1000;
BA_ "GenMsgSendType" BO_ 2499751525 0;
BA_ "GenMsgDiag" BO_ 2499751525 1;
BA_ "GenMsgCycleTime" BO_ 2499751525 1000;
BA_ "GenMsgSendType" BO_ 2499751526 0;
BA_ "GenMsgDiag" BO_ 2499751526 1;
BA_ "GenMsgCycleTime" BO_ 2499751526 1000;
BA_ "GenMsgSendType" BO_ 2499751527 0;
BA_ "GenMsgDiag" BO_ 2499751527 1;
BA_ "GenMsgCycleTime" BO_ 2499751527 1000;
BA_ "GenMsgSendType" BO_ 2499751528 0;
BA_ "GenMsgDiag" BO_ 2499751528 1;
BA_ "GenMsgCycleTime" BO_ 2499751528 1000;
BA_ "GenMsgSendType" BO_ 2499751529 0;
BA_ "GenMsgDiag" BO_ 2499751529 1;
BA_ "GenMsgCycleTime" BO_ 2499751529 1000;
BA_ "GenMsgSendType" BO_ 2499751530 0;
BA_ "GenMsgDiag" BO_ 2499751530 1;
BA_ "GenMsgCycleTime" BO_ 2499751530 1000;
BA_ "GenMsgSendType" BO_ 2499751531 0;
BA_ "GenMsgDiag" BO_ 2499751531 1;
BA_ "GenMsgCycleTime" BO_ 2499751531 1000;
BA_ "GenMsgSendType" BO_ 2499751532 0;
BA_ "GenMsgDiag" BO_ 2499751532 1;
BA_ "GenMsgCycleTime" BO_ 2499751532 1000;
BA_ "GenMsgSendType" BO_ 2499751781 0;
BA_ "GenMsgDiag" BO_ 2499751781 1;
BA_ "GenMsgCycleTime" BO_ 2499751781 1000;
BA_ "GenMsgSendType" BO_ 2499751782 0;
BA_ "GenMsgDiag" BO_ 2499751782 1;
BA_ "GenMsgCycleTime" BO_ 2499751782 1000;
BA_ "GenMsgSendType" BO_ 2499751783 0;
BA_ "GenMsgDiag" BO_ 2499751783 1;
BA_ "GenMsgCycleTime" BO_ 2499751783 1000;
BA_ "GenMsgSendType" BO_ 2499751784 0;
BA_ "GenMsgDiag" BO_ 2499751784 1;
BA_ "GenMsgCycleTime" BO_ 2499751784 1000;
BA_ "GenMsgSendType" BO_ 2499751785 0;
BA_ "GenMsgDiag" BO_ 2499751785 1;
BA_ "GenMsgCycleTime" BO_ 2499751785 1000;
BA_ "GenMsgSendType" BO_ 2499751786 0;
BA_ "GenMsgDiag" BO_ 2499751786 1;
BA_ "GenMsgCycleTime" BO_ 2499751786 1000;
BA_ "GenMsgSendType" BO_ 2499751787 0;
BA_ "GenMsgDiag" BO_ 2499751787 1;
BA_ "GenMsgCycleTime" BO_ 2499751787 1000;
BA_ "GenMsgSendType" BO_ 2499751788 0;
BA_ "GenMsgDiag" BO_ 2499751788 1;
BA_ "GenMsgCycleTime" BO_ 2499751788 1000;
BA_ "GenMsgSendType" BO_ 2499752037 0;
BA_ "GenMsgDiag" BO_ 2499752037 1;
BA_ "GenMsgCycleTime" BO_ 2499752037 1000;
BA_ "SystemMessageLongSymbol" BO_ 2499752037 "HVESP01_AfePwrWireCellSum_01_04_1";
BA_ "GenMsgSendType" BO_ 2499752038 0;
BA_ "GenMsgDiag" BO_ 2499752038 1;
BA_ "GenMsgCycleTime" BO_ 2499752038 1000;
BA_ "SystemMessageLongSymbol" BO_ 2499752038 "HVESP01_AfePwrWireCellSum_01_04_2";
BA_ "GenMsgSendType" BO_ 2499752039 0;
BA_ "GenMsgDiag" BO_ 2499752039 1;
BA_ "GenMsgCycleTime" BO_ 2499752039 1000;
BA_ "SystemMessageLongSymbol" BO_ 2499752039 "HVESP01_AfePwrWireCellSum_01_04_3";
BA_ "GenMsgSendType" BO_ 2499752040 0;
BA_ "GenMsgDiag" BO_ 2499752040 1;
BA_ "GenMsgCycleTime" BO_ 2499752040 1000;
BA_ "SystemMessageLongSymbol" BO_ 2499752040 "HVESP01_AfePwrWireCellSum_01_04_4";
BA_ "GenMsgSendType" BO_ 2499752041 0;
BA_ "GenMsgDiag" BO_ 2499752041 1;
BA_ "GenMsgCycleTime" BO_ 2499752041 1000;
BA_ "SystemMessageLongSymbol" BO_ 2499752041 "HVESP01_AfePwrWireCellSum_01_04_5";
BA_ "GenMsgSendType" BO_ 2499752042 0;
BA_ "GenMsgDiag" BO_ 2499752042 1;
BA_ "GenMsgCycleTime" BO_ 2499752042 1000;
BA_ "SystemMessageLongSymbol" BO_ 2499752042 "HVESP01_AfePwrWireCellSum_01_04_6";
BA_ "GenMsgSendType" BO_ 2499752043 0;
BA_ "GenMsgDiag" BO_ 2499752043 1;
BA_ "GenMsgCycleTime" BO_ 2499752043 1000;
BA_ "SystemMessageLongSymbol" BO_ 2499752043 "HVESP01_AfePwrWireCellSum_01_04_7";
BA_ "GenMsgSendType" BO_ 2499752044 0;
BA_ "GenMsgDiag" BO_ 2499752044 1;
BA_ "GenMsgCycleTime" BO_ 2499752044 1000;
BA_ "SystemMessageLongSymbol" BO_ 2499752044 "HVESP01_AfePwrWireCellSum_01_04_8";
BA_ "GenMsgSendType" BO_ 2499752293 0;
BA_ "GenMsgDiag" BO_ 2499752293 1;
BA_ "GenMsgCycleTime" BO_ 2499752293 1000;
BA_ "SystemMessageLongSymbol" BO_ 2499752293 "HVESP01_AfePwrWireCellSum_05_08_1";
BA_ "GenMsgSendType" BO_ 2499752294 0;
BA_ "GenMsgDiag" BO_ 2499752294 1;
BA_ "GenMsgCycleTime" BO_ 2499752294 1000;
BA_ "SystemMessageLongSymbol" BO_ 2499752294 "HVESP01_AfePwrWireCellSum_05_08_2";
BA_ "GenMsgSendType" BO_ 2499752295 0;
BA_ "GenMsgDiag" BO_ 2499752295 1;
BA_ "GenMsgCycleTime" BO_ 2499752295 1000;
BA_ "SystemMessageLongSymbol" BO_ 2499752295 "HVESP01_AfePwrWireCellSum_05_08_3";
BA_ "GenMsgSendType" BO_ 2499752296 0;
BA_ "GenMsgDiag" BO_ 2499752296 1;
BA_ "GenMsgCycleTime" BO_ 2499752296 1000;
BA_ "SystemMessageLongSymbol" BO_ 2499752296 "HVESP01_AfePwrWireCellSum_05_08_4";
BA_ "GenMsgSendType" BO_ 2499752297 0;
BA_ "GenMsgDiag" BO_ 2499752297 1;
BA_ "GenMsgCycleTime" BO_ 2499752297 1000;
BA_ "SystemMessageLongSymbol" BO_ 2499752297 "HVESP01_AfePwrWireCellSum_05_08_5";
BA_ "GenMsgSendType" BO_ 2499752298 0;
BA_ "GenMsgDiag" BO_ 2499752298 1;
BA_ "GenMsgCycleTime" BO_ 2499752298 1000;
BA_ "SystemMessageLongSymbol" BO_ 2499752298 "HVESP01_AfePwrWireCellSum_05_08_6";
BA_ "GenMsgSendType" BO_ 2499752299 0;
BA_ "GenMsgDiag" BO_ 2499752299 1;
BA_ "GenMsgCycleTime" BO_ 2499752299 1000;
BA_ "SystemMessageLongSymbol" BO_ 2499752299 "HVESP01_AfePwrWireCellSum_05_08_7";
BA_ "GenMsgSendType" BO_ 2499752300 0;
BA_ "GenMsgDiag" BO_ 2499752300 1;
BA_ "GenMsgCycleTime" BO_ 2499752300 1000;
BA_ "SystemMessageLongSymbol" BO_ 2499752300 "HVESP01_AfePwrWireCellSum_05_08_8";
BA_ "GenMsgSendType" BO_ 2499752549 0;
BA_ "GenMsgDiag" BO_ 2499752549 1;
BA_ "GenMsgCycleTime" BO_ 2499752549 1000;
BA_ "SystemMessageLongSymbol" BO_ 2499752549 "HVESP01_AfePwrWireCellSum_09_12_1";
BA_ "GenMsgSendType" BO_ 2499752550 0;
BA_ "GenMsgDiag" BO_ 2499752550 1;
BA_ "GenMsgCycleTime" BO_ 2499752550 1000;
BA_ "SystemMessageLongSymbol" BO_ 2499752550 "HVESP01_AfePwrWireCellSum_09_12_2";
BA_ "GenMsgSendType" BO_ 2499752551 0;
BA_ "GenMsgDiag" BO_ 2499752551 1;
BA_ "GenMsgCycleTime" BO_ 2499752551 1000;
BA_ "SystemMessageLongSymbol" BO_ 2499752551 "HVESP01_AfePwrWireCellSum_09_12_3";
BA_ "GenMsgSendType" BO_ 2499752552 0;
BA_ "GenMsgDiag" BO_ 2499752552 1;
BA_ "GenMsgCycleTime" BO_ 2499752552 1000;
BA_ "SystemMessageLongSymbol" BO_ 2499752552 "HVESP01_AfePwrWireCellSum_09_12_4";
BA_ "GenMsgSendType" BO_ 2499752553 0;
BA_ "GenMsgDiag" BO_ 2499752553 1;
BA_ "GenMsgCycleTime" BO_ 2499752553 1000;
BA_ "SystemMessageLongSymbol" BO_ 2499752553 "HVESP01_AfePwrWireCellSum_09_12_5";
BA_ "GenMsgSendType" BO_ 2499752554 0;
BA_ "GenMsgDiag" BO_ 2499752554 1;
BA_ "GenMsgCycleTime" BO_ 2499752554 1000;
BA_ "SystemMessageLongSymbol" BO_ 2499752554 "HVESP01_AfePwrWireCellSum_09_12_6";
BA_ "GenMsgSendType" BO_ 2499752555 0;
BA_ "GenMsgDiag" BO_ 2499752555 1;
BA_ "GenMsgCycleTime" BO_ 2499752555 1000;
BA_ "SystemMessageLongSymbol" BO_ 2499752555 "HVESP01_AfePwrWireCellSum_09_12_7";
BA_ "GenMsgSendType" BO_ 2499752556 0;
BA_ "GenMsgDiag" BO_ 2499752556 1;
BA_ "GenMsgCycleTime" BO_ 2499752556 1000;
BA_ "SystemMessageLongSymbol" BO_ 2499752556 "HVESP01_AfePwrWireCellSum_09_12_8";
BA_ "GenMsgSendType" BO_ 2499752805 0;
BA_ "GenMsgDiag" BO_ 2499752805 1;
BA_ "GenMsgCycleTime" BO_ 2499752805 1000;
BA_ "SystemMessageLongSymbol" BO_ 2499752805 "HVESP01_AfePwrWireCellSum_13_16_1";
BA_ "GenMsgSendType" BO_ 2499752806 0;
BA_ "GenMsgDiag" BO_ 2499752806 1;
BA_ "GenMsgCycleTime" BO_ 2499752806 1000;
BA_ "SystemMessageLongSymbol" BO_ 2499752806 "HVESP01_AfePwrWireCellSum_13_16_2";
BA_ "GenMsgSendType" BO_ 2499752807 0;
BA_ "GenMsgDiag" BO_ 2499752807 1;
BA_ "GenMsgCycleTime" BO_ 2499752807 1000;
BA_ "SystemMessageLongSymbol" BO_ 2499752807 "HVESP01_AfePwrWireCellSum_13_16_3";
BA_ "GenMsgSendType" BO_ 2499752808 0;
BA_ "GenMsgDiag" BO_ 2499752808 1;
BA_ "GenMsgCycleTime" BO_ 2499752808 1000;
BA_ "SystemMessageLongSymbol" BO_ 2499752808 "HVESP01_AfePwrWireCellSum_13_16_4";
BA_ "GenMsgSendType" BO_ 2499752809 0;
BA_ "GenMsgDiag" BO_ 2499752809 1;
BA_ "GenMsgCycleTime" BO_ 2499752809 1000;
BA_ "SystemMessageLongSymbol" BO_ 2499752809 "HVESP01_AfePwrWireCellSum_13_16_5";
BA_ "GenMsgSendType" BO_ 2499752810 0;
BA_ "GenMsgDiag" BO_ 2499752810 1;
BA_ "GenMsgCycleTime" BO_ 2499752810 1000;
BA_ "SystemMessageLongSymbol" BO_ 2499752810 "HVESP01_AfePwrWireCellSum_13_16_6";
BA_ "GenMsgSendType" BO_ 2499752811 0;
BA_ "GenMsgDiag" BO_ 2499752811 1;
BA_ "GenMsgCycleTime" BO_ 2499752811 1000;
BA_ "SystemMessageLongSymbol" BO_ 2499752811 "HVESP01_AfePwrWireCellSum_13_16_7";
BA_ "GenMsgSendType" BO_ 2499752812 0;
BA_ "GenMsgDiag" BO_ 2499752812 1;
BA_ "GenMsgCycleTime" BO_ 2499752812 1000;
BA_ "SystemMessageLongSymbol" BO_ 2499752812 "HVESP01_AfePwrWireCellSum_13_16_8";
BA_ "GenMsgSendType" BO_ 2499753061 0;
BA_ "GenMsgDiag" BO_ 2499753061 1;
BA_ "GenMsgCycleTime" BO_ 2499753061 1000;
BA_ "SystemMessageLongSymbol" BO_ 2499753061 "HVESP01_AfePwrWireCellSum_17_20_1";
BA_ "GenMsgSendType" BO_ 2499753062 0;
BA_ "GenMsgDiag" BO_ 2499753062 1;
BA_ "GenMsgCycleTime" BO_ 2499753062 1000;
BA_ "SystemMessageLongSymbol" BO_ 2499753062 "HVESP01_AfePwrWireCellSum_17_20_2";
BA_ "GenMsgSendType" BO_ 2499753063 0;
BA_ "GenMsgDiag" BO_ 2499753063 1;
BA_ "GenMsgCycleTime" BO_ 2499753063 1000;
BA_ "SystemMessageLongSymbol" BO_ 2499753063 "HVESP01_AfePwrWireCellSum_17_20_3";
BA_ "GenMsgSendType" BO_ 2499753064 0;
BA_ "GenMsgDiag" BO_ 2499753064 1;
BA_ "GenMsgCycleTime" BO_ 2499753064 1000;
BA_ "SystemMessageLongSymbol" BO_ 2499753064 "HVESP01_AfePwrWireCellSum_17_20_4";
BA_ "GenMsgSendType" BO_ 2499753065 0;
BA_ "GenMsgDiag" BO_ 2499753065 1;
BA_ "GenMsgCycleTime" BO_ 2499753065 1000;
BA_ "SystemMessageLongSymbol" BO_ 2499753065 "HVESP01_AfePwrWireCellSum_17_20_5";
BA_ "GenMsgSendType" BO_ 2499753066 0;
BA_ "GenMsgDiag" BO_ 2499753066 1;
BA_ "GenMsgCycleTime" BO_ 2499753066 1000;
BA_ "SystemMessageLongSymbol" BO_ 2499753066 "HVESP01_AfePwrWireCellSum_17_20_6";
BA_ "GenMsgSendType" BO_ 2499753067 0;
BA_ "GenMsgDiag" BO_ 2499753067 1;
BA_ "GenMsgCycleTime" BO_ 2499753067 1000;
BA_ "SystemMessageLongSymbol" BO_ 2499753067 "HVESP01_AfePwrWireCellSum_17_20_7";
BA_ "GenMsgSendType" BO_ 2499753068 0;
BA_ "GenMsgDiag" BO_ 2499753068 1;
BA_ "GenMsgCycleTime" BO_ 2499753068 1000;
BA_ "SystemMessageLongSymbol" BO_ 2499753068 "HVESP01_AfePwrWireCellSum_17_20_8";
BA_ "GenMsgSendType" BO_ 2499753317 0;
BA_ "GenMsgDiag" BO_ 2499753317 1;
BA_ "GenMsgCycleTime" BO_ 2499753317 1000;
BA_ "SystemMessageLongSymbol" BO_ 2499753317 "HVESP01_AfePwrWireCellSum_21_22_1";
BA_ "GenMsgSendType" BO_ 2499753318 0;
BA_ "GenMsgDiag" BO_ 2499753318 1;
BA_ "GenMsgCycleTime" BO_ 2499753318 1000;
BA_ "SystemMessageLongSymbol" BO_ 2499753318 "HVESP01_AfePwrWireCellSum_21_22_2";
BA_ "GenMsgSendType" BO_ 2499753319 0;
BA_ "GenMsgDiag" BO_ 2499753319 1;
BA_ "GenMsgCycleTime" BO_ 2499753319 1000;
BA_ "SystemMessageLongSymbol" BO_ 2499753319 "HVESP01_AfePwrWireCellSum_21_22_3";
BA_ "GenMsgSendType" BO_ 2499753320 0;
BA_ "GenMsgDiag" BO_ 2499753320 1;
BA_ "GenMsgCycleTime" BO_ 2499753320 1000;
BA_ "SystemMessageLongSymbol" BO_ 2499753320 "HVESP01_AfePwrWireCellSum_21_22_4";
BA_ "GenMsgSendType" BO_ 2499753321 0;
BA_ "GenMsgDiag" BO_ 2499753321 1;
BA_ "GenMsgCycleTime" BO_ 2499753321 1000;
BA_ "SystemMessageLongSymbol" BO_ 2499753321 "HVESP01_AfePwrWireCellSum_21_22_5";
BA_ "GenMsgSendType" BO_ 2499753322 0;
BA_ "GenMsgDiag" BO_ 2499753322 1;
BA_ "GenMsgCycleTime" BO_ 2499753322 1000;
BA_ "SystemMessageLongSymbol" BO_ 2499753322 "HVESP01_AfePwrWireCellSum_21_22_6";
BA_ "GenMsgSendType" BO_ 2499753323 0;
BA_ "GenMsgDiag" BO_ 2499753323 1;
BA_ "GenMsgCycleTime" BO_ 2499753323 1000;
BA_ "SystemMessageLongSymbol" BO_ 2499753323 "HVESP01_AfePwrWireCellSum_21_22_7";
BA_ "GenMsgSendType" BO_ 2499753324 0;
BA_ "GenMsgDiag" BO_ 2499753324 1;
BA_ "GenMsgCycleTime" BO_ 2499753324 1000;
BA_ "SystemMessageLongSymbol" BO_ 2499753324 "HVESP01_AfePwrWireCellSum_21_22_8";
BA_ "GenMsgSendType" BO_ 2499753573 0;
BA_ "GenMsgDiag" BO_ 2499753573 1;
BA_ "GenMsgCycleTime" BO_ 2499753573 1000;
BA_ "GenMsgSendType" BO_ 2499753574 0;
BA_ "GenMsgDiag" BO_ 2499753574 1;
BA_ "GenMsgCycleTime" BO_ 2499753574 1000;
BA_ "GenMsgSendType" BO_ 2499753575 0;
BA_ "GenMsgDiag" BO_ 2499753575 1;
BA_ "GenMsgCycleTime" BO_ 2499753575 1000;
BA_ "GenMsgSendType" BO_ 2499753576 0;
BA_ "GenMsgDiag" BO_ 2499753576 1;
BA_ "GenMsgCycleTime" BO_ 2499753576 1000;
BA_ "GenMsgSendType" BO_ 2499753577 0;
BA_ "GenMsgDiag" BO_ 2499753577 1;
BA_ "GenMsgCycleTime" BO_ 2499753577 1000;
BA_ "GenMsgSendType" BO_ 2499753578 0;
BA_ "GenMsgDiag" BO_ 2499753578 1;
BA_ "GenMsgCycleTime" BO_ 2499753578 1000;
BA_ "GenMsgSendType" BO_ 2499753579 0;
BA_ "GenMsgDiag" BO_ 2499753579 1;
BA_ "GenMsgCycleTime" BO_ 2499753579 1000;
BA_ "GenMsgSendType" BO_ 2499753580 0;
BA_ "GenMsgDiag" BO_ 2499753580 1;
BA_ "GenMsgCycleTime" BO_ 2499753580 1000;
BA_ "GenMsgSendType" BO_ 2499753829 0;
BA_ "GenMsgDiag" BO_ 2499753829 1;
BA_ "GenMsgCycleTime" BO_ 2499753829 1000;
BA_ "GenMsgSendType" BO_ 2499753830 0;
BA_ "GenMsgDiag" BO_ 2499753830 1;
BA_ "GenMsgCycleTime" BO_ 2499753830 1000;
BA_ "GenMsgSendType" BO_ 2499753831 0;
BA_ "GenMsgDiag" BO_ 2499753831 1;
BA_ "GenMsgCycleTime" BO_ 2499753831 1000;
BA_ "GenMsgSendType" BO_ 2499753832 0;
BA_ "GenMsgDiag" BO_ 2499753832 1;
BA_ "GenMsgCycleTime" BO_ 2499753832 1000;
BA_ "GenMsgSendType" BO_ 2499753833 0;
BA_ "GenMsgDiag" BO_ 2499753833 1;
BA_ "GenMsgCycleTime" BO_ 2499753833 1000;
BA_ "GenMsgSendType" BO_ 2499753834 0;
BA_ "GenMsgDiag" BO_ 2499753834 1;
BA_ "GenMsgCycleTime" BO_ 2499753834 1000;
BA_ "GenMsgSendType" BO_ 2499753835 0;
BA_ "GenMsgDiag" BO_ 2499753835 1;
BA_ "GenMsgCycleTime" BO_ 2499753835 1000;
BA_ "GenMsgSendType" BO_ 2499753836 0;
BA_ "GenMsgDiag" BO_ 2499753836 1;
BA_ "GenMsgCycleTime" BO_ 2499753836 1000;
BA_ "GenMsgSendType" BO_ 2499754085 0;
BA_ "GenMsgDiag" BO_ 2499754085 1;
BA_ "GenMsgCycleTime" BO_ 2499754085 1000;
BA_ "GenMsgSendType" BO_ 2499754086 0;
BA_ "GenMsgDiag" BO_ 2499754086 1;
BA_ "GenMsgCycleTime" BO_ 2499754086 1000;
BA_ "GenMsgSendType" BO_ 2499754087 0;
BA_ "GenMsgDiag" BO_ 2499754087 1;
BA_ "GenMsgCycleTime" BO_ 2499754087 1000;
BA_ "GenMsgSendType" BO_ 2499754088 0;
BA_ "GenMsgDiag" BO_ 2499754088 1;
BA_ "GenMsgCycleTime" BO_ 2499754088 1000;
BA_ "GenMsgSendType" BO_ 2499754089 0;
BA_ "GenMsgDiag" BO_ 2499754089 1;
BA_ "GenMsgCycleTime" BO_ 2499754089 1000;
BA_ "GenMsgSendType" BO_ 2499754090 0;
BA_ "GenMsgDiag" BO_ 2499754090 1;
BA_ "GenMsgCycleTime" BO_ 2499754090 1000;
BA_ "GenMsgSendType" BO_ 2499754091 0;
BA_ "GenMsgDiag" BO_ 2499754091 1;
BA_ "GenMsgCycleTime" BO_ 2499754091 1000;
BA_ "GenMsgSendType" BO_ 2499754092 0;
BA_ "GenMsgDiag" BO_ 2499754092 1;
BA_ "GenMsgCycleTime" BO_ 2499754092 1000;
BA_ "GenMsgSendType" BO_ 2499754341 0;
BA_ "GenMsgDiag" BO_ 2499754341 1;
BA_ "GenMsgCycleTime" BO_ 2499754341 1000;
BA_ "GenMsgSendType" BO_ 2499754342 0;
BA_ "GenMsgDiag" BO_ 2499754342 1;
BA_ "GenMsgCycleTime" BO_ 2499754342 1000;
BA_ "GenMsgSendType" BO_ 2499754343 0;
BA_ "GenMsgDiag" BO_ 2499754343 1;
BA_ "GenMsgCycleTime" BO_ 2499754343 1000;
BA_ "GenMsgSendType" BO_ 2499754344 0;
BA_ "GenMsgDiag" BO_ 2499754344 1;
BA_ "GenMsgCycleTime" BO_ 2499754344 1000;
BA_ "GenMsgSendType" BO_ 2499754345 0;
BA_ "GenMsgDiag" BO_ 2499754345 1;
BA_ "GenMsgCycleTime" BO_ 2499754345 1000;
BA_ "GenMsgSendType" BO_ 2499754346 0;
BA_ "GenMsgDiag" BO_ 2499754346 1;
BA_ "GenMsgCycleTime" BO_ 2499754346 1000;
BA_ "GenMsgSendType" BO_ 2499754347 0;
BA_ "GenMsgDiag" BO_ 2499754347 1;
BA_ "GenMsgCycleTime" BO_ 2499754347 1000;
BA_ "GenMsgSendType" BO_ 2499754348 0;
BA_ "GenMsgDiag" BO_ 2499754348 1;
BA_ "GenMsgCycleTime" BO_ 2499754348 1000;
BA_ "GenMsgSendType" BO_ 2499754597 0;
BA_ "GenMsgDiag" BO_ 2499754597 1;
BA_ "GenMsgCycleTime" BO_ 2499754597 1000;
BA_ "GenMsgSendType" BO_ 2499754598 0;
BA_ "GenMsgDiag" BO_ 2499754598 1;
BA_ "GenMsgCycleTime" BO_ 2499754598 1000;
BA_ "GenMsgSendType" BO_ 2499754599 0;
BA_ "GenMsgDiag" BO_ 2499754599 1;
BA_ "GenMsgCycleTime" BO_ 2499754599 1000;
BA_ "GenMsgSendType" BO_ 2499754600 0;
BA_ "GenMsgDiag" BO_ 2499754600 1;
BA_ "GenMsgCycleTime" BO_ 2499754600 1000;
BA_ "GenMsgSendType" BO_ 2499754601 0;
BA_ "GenMsgDiag" BO_ 2499754601 1;
BA_ "GenMsgCycleTime" BO_ 2499754601 1000;
BA_ "GenMsgSendType" BO_ 2499754602 0;
BA_ "GenMsgDiag" BO_ 2499754602 1;
BA_ "GenMsgCycleTime" BO_ 2499754602 1000;
BA_ "GenMsgSendType" BO_ 2499754603 0;
BA_ "GenMsgDiag" BO_ 2499754603 1;
BA_ "GenMsgCycleTime" BO_ 2499754603 1000;
BA_ "GenMsgSendType" BO_ 2499754604 0;
BA_ "GenMsgDiag" BO_ 2499754604 1;
BA_ "GenMsgCycleTime" BO_ 2499754604 1000;
BA_ "GenMsgSendType" BO_ 2499754853 0;
BA_ "GenMsgDiag" BO_ 2499754853 1;
BA_ "GenMsgCycleTime" BO_ 2499754853 1000;
BA_ "GenMsgSendType" BO_ 2499754854 0;
BA_ "GenMsgDiag" BO_ 2499754854 1;
BA_ "GenMsgCycleTime" BO_ 2499754854 1000;
BA_ "GenMsgSendType" BO_ 2499754855 0;
BA_ "GenMsgDiag" BO_ 2499754855 1;
BA_ "GenMsgCycleTime" BO_ 2499754855 1000;
BA_ "GenMsgSendType" BO_ 2499754856 0;
BA_ "GenMsgDiag" BO_ 2499754856 1;
BA_ "GenMsgCycleTime" BO_ 2499754856 1000;
BA_ "GenMsgSendType" BO_ 2499754857 0;
BA_ "GenMsgDiag" BO_ 2499754857 1;
BA_ "GenMsgCycleTime" BO_ 2499754857 1000;
BA_ "GenMsgSendType" BO_ 2499754858 0;
BA_ "GenMsgDiag" BO_ 2499754858 1;
BA_ "GenMsgCycleTime" BO_ 2499754858 1000;
BA_ "GenMsgSendType" BO_ 2499754859 0;
BA_ "GenMsgDiag" BO_ 2499754859 1;
BA_ "GenMsgCycleTime" BO_ 2499754859 1000;
BA_ "GenMsgSendType" BO_ 2499754860 0;
BA_ "GenMsgDiag" BO_ 2499754860 1;
BA_ "GenMsgCycleTime" BO_ 2499754860 1000;
BA_ "SystemSignalLongSymbol" SG_ 2499760997 HVESP01_packBoardDetails_pack_id "HVESP01_packBoardDetails_pack_id_1";
BA_ "SystemSignalLongSymbol" SG_ 2499760997 HVESP01_packBoardDetails_revPath "HVESP01_packBoardDetails_revPathBreak";
BA_ "SystemSignalLongSymbol" SG_ 2499760997 HVESP01_packBoardDetails_fwdPath "HVESP01_packBoardDetails_fwdPathBreak";
BA_ "SystemSignalLongSymbol" SG_ 2499760997 HVESP01_packBoardDetails_variant "HVESP01_packBoardDetails_variant_1";
BA_ "SystemSignalLongSymbol" SG_ 2499760998 HVESP01_packBoardDetails_pa_0000 "HVESP01_packBoardDetails_pack_id_2";
BA_ "SystemSignalLongSymbol" SG_ 2499760998 HVESP01_packBoardDetails_re_0000 "HVESP01_packBoardDetails_revPathBreak";
BA_ "SystemSignalLongSymbol" SG_ 2499760998 HVESP01_packBoardDetails_fw_0000 "HVESP01_packBoardDetails_fwdPathBreak";
BA_ "SystemSignalLongSymbol" SG_ 2499760998 HVESP01_packBoardDetails_va_0000 "HVESP01_packBoardDetails_variant_2";
BA_ "SystemSignalLongSymbol" SG_ 2499760999 HVESP01_packBoardDetails_pa_0001 "HVESP01_packBoardDetails_pack_id_3";
BA_ "SystemSignalLongSymbol" SG_ 2499760999 HVESP01_packBoardDetails_re_0001 "HVESP01_packBoardDetails_revPathBreak";
BA_ "SystemSignalLongSymbol" SG_ 2499760999 HVESP01_packBoardDetails_fw_0001 "HVESP01_packBoardDetails_fwdPathBreak";
BA_ "SystemSignalLongSymbol" SG_ 2499760999 HVESP01_packBoardDetails_va_0001 "HVESP01_packBoardDetails_variant_3";
BA_ "SystemSignalLongSymbol" SG_ 2499761000 HVESP01_packBoardDetails_pa_0002 "HVESP01_packBoardDetails_pack_id_4";
BA_ "SystemSignalLongSymbol" SG_ 2499761000 HVESP01_packBoardDetails_re_0002 "HVESP01_packBoardDetails_revPathBreak";
BA_ "SystemSignalLongSymbol" SG_ 2499761000 HVESP01_packBoardDetails_fw_0002 "HVESP01_packBoardDetails_fwdPathBreak";
BA_ "SystemSignalLongSymbol" SG_ 2499761000 HVESP01_packBoardDetails_va_0002 "HVESP01_packBoardDetails_variant_4";
BA_ "SystemSignalLongSymbol" SG_ 2499761001 HVESP01_packBoardDetails_pa_0003 "HVESP01_packBoardDetails_pack_id_5";
BA_ "SystemSignalLongSymbol" SG_ 2499761001 HVESP01_packBoardDetails_re_0003 "HVESP01_packBoardDetails_revPathBreak";
BA_ "SystemSignalLongSymbol" SG_ 2499761001 HVESP01_packBoardDetails_fw_0003 "HVESP01_packBoardDetails_fwdPathBreak";
BA_ "SystemSignalLongSymbol" SG_ 2499761001 HVESP01_packBoardDetails_va_0003 "HVESP01_packBoardDetails_variant_5";
BA_ "SystemSignalLongSymbol" SG_ 2499761002 HVESP01_packBoardDetails_pa_0004 "HVESP01_packBoardDetails_pack_id_6";
BA_ "SystemSignalLongSymbol" SG_ 2499761002 HVESP01_packBoardDetails_re_0004 "HVESP01_packBoardDetails_revPathBreak";
BA_ "SystemSignalLongSymbol" SG_ 2499761002 HVESP01_packBoardDetails_fw_0004 "HVESP01_packBoardDetails_fwdPathBreak";
BA_ "SystemSignalLongSymbol" SG_ 2499761002 HVESP01_packBoardDetails_va_0004 "HVESP01_packBoardDetails_variant_6";
BA_ "SystemSignalLongSymbol" SG_ 2499761003 HVESP01_packBoardDetails_pa_0005 "HVESP01_packBoardDetails_pack_id_7";
BA_ "SystemSignalLongSymbol" SG_ 2499761003 HVESP01_packBoardDetails_re_0005 "HVESP01_packBoardDetails_revPathBreak";
BA_ "SystemSignalLongSymbol" SG_ 2499761003 HVESP01_packBoardDetails_fw_0005 "HVESP01_packBoardDetails_fwdPathBreak";
BA_ "SystemSignalLongSymbol" SG_ 2499761003 HVESP01_packBoardDetails_va_0005 "HVESP01_packBoardDetails_variant_7";
BA_ "SystemSignalLongSymbol" SG_ 2499761004 HVESP01_packBoardDetails_pa_0006 "HVESP01_packBoardDetails_pack_id_8";
BA_ "SystemSignalLongSymbol" SG_ 2499761004 HVESP01_packBoardDetails_re_0006 "HVESP01_packBoardDetails_revPathBreak";
BA_ "SystemSignalLongSymbol" SG_ 2499761004 HVESP01_packBoardDetails_fw_0006 "HVESP01_packBoardDetails_fwdPathBreak";
BA_ "SystemSignalLongSymbol" SG_ 2499761004 HVESP01_packBoardDetails_va_0006 "HVESP01_packBoardDetails_variant_8";
BA_ "SystemSignalLongSymbol" SG_ 2499761253 HVESP01_Des_software_dest_reset_ "HVESP01_Des_software_dest_reset_1";
BA_ "SystemSignalLongSymbol" SG_ 2499761253 HVESP01_Fes_self_test_done_reset "HVESP01_Fes_self_test_done_reset_1";
BA_ "SystemSignalLongSymbol" SG_ 2499761254 HVESP01_Des_software_dest_r_0000 "HVESP01_Des_software_dest_reset_2";
BA_ "SystemSignalLongSymbol" SG_ 2499761254 HVESP01_Fes_self_test_done__0000 "HVESP01_Fes_self_test_done_reset_2";
BA_ "SystemSignalLongSymbol" SG_ 2499761255 HVESP01_Des_software_dest_r_0001 "HVESP01_Des_software_dest_reset_3";
BA_ "SystemSignalLongSymbol" SG_ 2499761255 HVESP01_Fes_self_test_done__0001 "HVESP01_Fes_self_test_done_reset_3";
BA_ "SystemSignalLongSymbol" SG_ 2499761256 HVESP01_Des_software_dest_r_0002 "HVESP01_Des_software_dest_reset_4";
BA_ "SystemSignalLongSymbol" SG_ 2499761256 HVESP01_Fes_self_test_done__0002 "HVESP01_Fes_self_test_done_reset_4";
BA_ "SystemSignalLongSymbol" SG_ 2499761257 HVESP01_Des_software_dest_r_0003 "HVESP01_Des_software_dest_reset_5";
BA_ "SystemSignalLongSymbol" SG_ 2499761257 HVESP01_Fes_self_test_done__0003 "HVESP01_Fes_self_test_done_reset_5";
BA_ "SystemSignalLongSymbol" SG_ 2499761258 HVESP01_Des_software_dest_r_0004 "HVESP01_Des_software_dest_reset_6";
BA_ "SystemSignalLongSymbol" SG_ 2499761258 HVESP01_Fes_self_test_done__0004 "HVESP01_Fes_self_test_done_reset_6";
BA_ "SystemSignalLongSymbol" SG_ 2499761259 HVESP01_Des_software_dest_r_0005 "HVESP01_Des_software_dest_reset_7";
BA_ "SystemSignalLongSymbol" SG_ 2499761259 HVESP01_Fes_self_test_done__0005 "HVESP01_Fes_self_test_done_reset_7";
BA_ "SystemSignalLongSymbol" SG_ 2499761260 HVESP01_Des_software_dest_r_0006 "HVESP01_Des_software_dest_reset_8";
BA_ "SystemSignalLongSymbol" SG_ 2499761260 HVESP01_Fes_self_test_done__0006 "HVESP01_Fes_self_test_done_reset_8";
BA_ "GenSigStartValue" SG_ 2499764325 HVESP01_DPP_Pack_ID_1 1;
BA_ "GenSigStartValue" SG_ 2499764325 HVESP01_DPP_Data_ID_1 1;
BA_ "GenSigStartValue" SG_ 2499764581 HVESP01_DPP_Pack_ID_1 1;
BA_ "SigType" SG_ 2499764581 HVESP01_DPP_Info_1 3;
BA_ "GenSigStartValue" SG_ 2499764326 HVESP01_DPP_Pack_ID_2 1;
BA_ "GenSigStartValue" SG_ 2499764326 HVESP01_DPP_Data_ID_2 1;
BA_ "GenSigStartValue" SG_ 2499764582 HVESP01_DPP_Pack_ID_2 1;
BA_ "SigType" SG_ 2499764582 HVESP01_DPP_Info_2 3;
BA_ "GenSigStartValue" SG_ 2499764327 HVESP01_DPP_Pack_ID_3 1;
BA_ "GenSigStartValue" SG_ 2499764327 HVESP01_DPP_Data_ID_3 1;
BA_ "GenSigStartValue" SG_ 2499764583 HVESP01_DPP_Pack_ID_3 1;
BA_ "SigType" SG_ 2499764583 HVESP01_DPP_Info_3 3;
BA_ "GenSigStartValue" SG_ 2499764328 HVESP01_DPP_Pack_ID_4 1;
BA_ "GenSigStartValue" SG_ 2499764328 HVESP01_DPP_Data_ID_4 1;
BA_ "GenSigStartValue" SG_ 2499764584 HVESP01_DPP_Pack_ID_4 1;
BA_ "SigType" SG_ 2499764584 HVESP01_DPP_Info_4 3;
BA_ "GenSigStartValue" SG_ 2499764329 HVESP01_DPP_Pack_ID_5 1;
BA_ "GenSigStartValue" SG_ 2499764330 HVESP01_DPP_Pack_ID_6 1;
BA_ "GenSigStartValue" SG_ 2499764331 HVESP01_DPP_Pack_ID_7 1;
BA_ "GenSigStartValue" SG_ 2499764332 HVESP01_DPP_Pack_ID_8 1;
BA_ "GenSigStartValue" SG_ 2499764329 HVESP01_DPP_Data_ID_5 1;
BA_ "GenSigStartValue" SG_ 2499764330 HVESP01_DPP_Data_ID_6 1;
BA_ "GenSigStartValue" SG_ 2499764331 HVESP01_DPP_Data_ID_7 1;
BA_ "GenSigStartValue" SG_ 2499764332 HVESP01_DPP_Data_ID_8 1;
BA_ "GenSigStartValue" SG_ 2499764585 HVESP01_DPP_Pack_ID_5 1;
BA_ "GenSigStartValue" SG_ 2499764586 HVESP01_DPP_Pack_ID_6 1;
BA_ "GenSigStartValue" SG_ 2499764587 HVESP01_DPP_Pack_ID_7 1;
BA_ "GenSigStartValue" SG_ 2499764588 HVESP01_DPP_Pack_ID_8 1;
BA_ "SigType" SG_ 2499764585 HVESP01_DPP_Info_5 3;
BA_ "SigType" SG_ 2499764586 HVESP01_DPP_Info_6 3;
BA_ "SigType" SG_ 2499764587 HVESP01_DPP_Info_7 3;
BA_ "SigType" SG_ 2499764588 HVESP01_DPP_Info_8 3;
VAL_ 2499760997 HVESP01_packBoardDetails_board_1 3 "Unknown" 2 "Core" 1 "JuiceBox" 0 "BaldEagle" ;
VAL_ 2499760998 HVESP01_packBoardDetails_board_2 3 "Unknown" 2 "Core" 1 "JuiceBox" 0 "BaldEagle" ;
VAL_ 2499760999 HVESP01_packBoardDetails_board_3 3 "Unknown" 2 "Core" 1 "JuiceBox" 0 "BaldEagle" ;
VAL_ 2499761000 HVESP01_packBoardDetails_board_4 3 "Unknown" 2 "Core" 1 "JuiceBox" 0 "BaldEagle" ;
VAL_ 2499761001 HVESP01_packBoardDetails_board_5 3 "Unknown" 2 "Core" 1 "JuiceBox" 0 "BaldEagle" ;
VAL_ 2499761002 HVESP01_packBoardDetails_board_6 3 "Unknown" 2 "Core" 1 "JuiceBox" 0 "BaldEagle" ;
VAL_ 2499761003 HVESP01_packBoardDetails_board_7 3 "Unknown" 2 "Core" 1 "JuiceBox" 0 "BaldEagle" ;
VAL_ 2499761004 HVESP01_packBoardDetails_board_8 3 "Unknown" 2 "Core" 1 "JuiceBox" 0 "BaldEagle" ;
VAL_ 2499764325 HVESP01_DPP_Data_ID_1 1 "Batt_Life_Status" 2 "Batt_Capacity" 3 "SocHisto_0To20" 4 "SocHisto_20To40" 5 "SocHisto_40To60" 6 "SocHisto_60To80" 7 "SocHisto_80To100" 8 "20SOC_PowerCap" 9 "50SOC_PowerCap" 10 "80SOC_PowerCap" 11 "Chg_Dchg_Counter" 12 "TEMP_LT_M20" 13 "TEMP_M20_0" 14 "TEMP_0_20" 15 "TEMP_20_40" 16 "TEMP_40_60" 17 "TEMP_GT_60" 18 "Deep_Dchg_Evt_Cnt" 19 "Overchg_Evt_Cnt" 20 "Post_Evt_Status" ;
VAL_ 2499764325 HVESP01_DPP_Data_Status_1 0 "Valid" 1 "Invalid / not available" ;
VAL_ 2499764326 HVESP01_DPP_Data_ID_2 1 "Batt_Life_Status" 2 "Batt_Capacity" 3 "SocHisto_0To20" 4 "SocHisto_20To40" 5 "SocHisto_40To60" 6 "SocHisto_60To80" 7 "SocHisto_80To100" 8 "20SOC_PowerCap" 9 "50SOC_PowerCap" 10 "80SOC_PowerCap" 11 "Chg_Dchg_Counter" 12 "TEMP_LT_M20" 13 "TEMP_M20_0" 14 "TEMP_0_20" 15 "TEMP_20_40" 16 "TEMP_40_60" 17 "TEMP_GT_60" 18 "Deep_Dchg_Evt_Cnt" 19 "Overchg_Evt_Cnt" 20 "Post_Evt_Status" ;
VAL_ 2499764326 HVESP01_DPP_Data_Status_2 0 "Valid" 1 "Invalid / not available" ;
VAL_ 2499764327 HVESP01_DPP_Data_ID_3 1 "Batt_Life_Status" 2 "Batt_Capacity" 3 "SocHisto_0To20" 4 "SocHisto_20To40" 5 "SocHisto_40To60" 6 "SocHisto_60To80" 7 "SocHisto_80To100" 8 "20SOC_PowerCap" 9 "50SOC_PowerCap" 10 "80SOC_PowerCap" 11 "Chg_Dchg_Counter" 12 "TEMP_LT_M20" 13 "TEMP_M20_0" 14 "TEMP_0_20" 15 "TEMP_20_40" 16 "TEMP_40_60" 17 "TEMP_GT_60" 18 "Deep_Dchg_Evt_Cnt" 19 "Overchg_Evt_Cnt" 20 "Post_Evt_Status" ;
VAL_ 2499764327 HVESP01_DPP_Data_Status_3 0 "Valid" 1 "Invalid / not available" ;
VAL_ 2499764328 HVESP01_DPP_Data_ID_4 1 "Batt_Life_Status" 2 "Batt_Capacity" 3 "SocHisto_0To20" 4 "SocHisto_20To40" 5 "SocHisto_40To60" 6 "SocHisto_60To80" 7 "SocHisto_80To100" 8 "20SOC_PowerCap" 9 "50SOC_PowerCap" 10 "80SOC_PowerCap" 11 "Chg_Dchg_Counter" 12 "TEMP_LT_M20" 13 "TEMP_M20_0" 14 "TEMP_0_20" 15 "TEMP_20_40" 16 "TEMP_40_60" 17 "TEMP_GT_60" 18 "Deep_Dchg_Evt_Cnt" 19 "Overchg_Evt_Cnt" 20 "Post_Evt_Status" ;
VAL_ 2499764328 HVESP01_DPP_Data_Status_4 0 "Valid" 1 "Invalid / not available" ;
VAL_ 2499764329 HVESP01_DPP_Data_ID_5 1 "Batt_Life_Status" 2 "Batt_Capacity" 3 "SocHisto_0To20" 4 "SocHisto_20To40" 5 "SocHisto_40To60" 6 "SocHisto_60To80" 7 "SocHisto_80To100" 8 "20SOC_PowerCap" 9 "50SOC_PowerCap" 10 "80SOC_PowerCap" 11 "Chg_Dchg_Counter" 12 "TEMP_LT_M20" 13 "TEMP_M20_0" 14 "TEMP_0_20" 15 "TEMP_20_40" 16 "TEMP_40_60" 17 "TEMP_GT_60" 18 "Deep_Dchg_Evt_Cnt" 19 "Overchg_Evt_Cnt" 20 "Post_Evt_Status" ;
VAL_ 2499764330 HVESP01_DPP_Data_ID_6 1 "Batt_Life_Status" 2 "Batt_Capacity" 3 "SocHisto_0To20" 4 "SocHisto_20To40" 5 "SocHisto_40To60" 6 "SocHisto_60To80" 7 "SocHisto_80To100" 8 "20SOC_PowerCap" 9 "50SOC_PowerCap" 10 "80SOC_PowerCap" 11 "Chg_Dchg_Counter" 12 "TEMP_LT_M20" 13 "TEMP_M20_0" 14 "TEMP_0_20" 15 "TEMP_20_40" 16 "TEMP_40_60" 17 "TEMP_GT_60" 18 "Deep_Dchg_Evt_Cnt" 19 "Overchg_Evt_Cnt" 20 "Post_Evt_Status" ;
VAL_ 2499764331 HVESP01_DPP_Data_ID_7 1 "Batt_Life_Status" 2 "Batt_Capacity" 3 "SocHisto_0To20" 4 "SocHisto_20To40" 5 "SocHisto_40To60" 6 "SocHisto_60To80" 7 "SocHisto_80To100" 8 "20SOC_PowerCap" 9 "50SOC_PowerCap" 10 "80SOC_PowerCap" 11 "Chg_Dchg_Counter" 12 "TEMP_LT_M20" 13 "TEMP_M20_0" 14 "TEMP_0_20" 15 "TEMP_20_40" 16 "TEMP_40_60" 17 "TEMP_GT_60" 18 "Deep_Dchg_Evt_Cnt" 19 "Overchg_Evt_Cnt" 20 "Post_Evt_Status" ;
VAL_ 2499764332 HVESP01_DPP_Data_ID_8 1 "Batt_Life_Status" 2 "Batt_Capacity" 3 "SocHisto_0To20" 4 "SocHisto_20To40" 5 "SocHisto_40To60" 6 "SocHisto_60To80" 7 "SocHisto_80To100" 8 "20SOC_PowerCap" 9 "50SOC_PowerCap" 10 "80SOC_PowerCap" 11 "Chg_Dchg_Counter" 12 "TEMP_LT_M20" 13 "TEMP_M20_0" 14 "TEMP_0_20" 15 "TEMP_20_40" 16 "TEMP_40_60" 17 "TEMP_GT_60" 18 "Deep_Dchg_Evt_Cnt" 19 "Overchg_Evt_Cnt" 20 "Post_Evt_Status" ;
VAL_ 2499764329 HVESP01_DPP_Data_Status_5 0 "Valid" 1 "Invalid / not available" ;
VAL_ 2499764330 HVESP01_DPP_Data_Status_6 0 "Valid" 1 "Invalid / not available" ;
VAL_ 2499764331 HVESP01_DPP_Data_Status_7 0 "Valid" 1 "Invalid / not available" ;
VAL_ 2499764332 HVESP01_DPP_Data_Status_8 0 "Valid" 1 "Invalid / not available" ;
